// *************************************************************************** *
// *                                                                           *
// *                      Mentor Graphics Corporation                          *
// *                          All rights reserved                              *
// *                                                                           *
// *************************************************************************** *
// *                                                                           *
// * Description:         CANDB File                                           *
// * Generated at:        2019-08-28 11:46:03                                  *
// * System:              xMA19024                                             *
// * Variant:             LSPA                                                 *
// * Network:             PropulsionCAN                                        *
// *                                                                           *
// *************************************************************************** *
// *                                                                           *
// *             THIS CONFIGURATION MIGHT CONTAIN SOME ERRORS                  *
// *              IF THE INPUT MODEL WAS NOT PROPERLY FORMED!                  *
// *                    Do Not Use this File directly!                         *
// *                                                                           *
// *************************************************************************** *
VERSION "PropulsionCAN"

NS_ :

BS_:

BU_:  BECM DEM ECM EGSM ESM ETC IEM IGM ISGM MVBM MVCM MVEM OBC SRS TACM TCM VDDM VGM

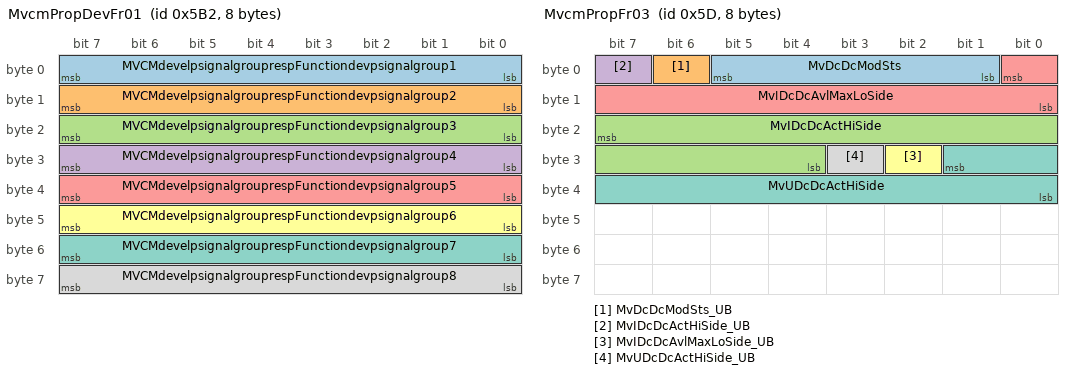
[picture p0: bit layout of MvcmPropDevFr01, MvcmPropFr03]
BO_ 1458 MvcmPropDevFr01: 8 MVCM
 SG_ MVCMdevelpsignalgrouprespFunctiondevpsignalgroup1 : 7|8@0+ (1.0,0.0) [0.0|255.0] "Unitless" ETC
 SG_ MVCMdevelpsignalgrouprespFunctiondevpsignalgroup2 : 15|8@0+ (1.0,0.0) [0.0|255.0] "Unitless" ETC
 SG_ MVCMdevelpsignalgrouprespFunctiondevpsignalgroup3 : 23|8@0+ (1.0,0.0) [0.0|255.0] "Unitless" ETC
 SG_ MVCMdevelpsignalgrouprespFunctiondevpsignalgroup4 : 31|8@0+ (1.0,0.0) [0.0|255.0] "Unitless" ETC
 SG_ MVCMdevelpsignalgrouprespFunctiondevpsignalgroup5 : 39|8@0+ (1.0,0.0) [0.0|255.0] "Unitless" ETC
 SG_ MVCMdevelpsignalgrouprespFunctiondevpsignalgroup6 : 47|8@0+ (1.0,0.0) [0.0|255.0] "Unitless" ETC
 SG_ MVCMdevelpsignalgrouprespFunctiondevpsignalgroup7 : 55|8@0+ (1.0,0.0) [0.0|255.0] "Unitless" ETC
 SG_ MVCMdevelpsignalgrouprespFunctiondevpsignalgroup8 : 63|8@0+ (1.0,0.0) [0.0|255.0] "Unitless" ETC

BO_ 93 MvcmPropFr03: 8 MVCM
 SG_ MvDcDcModSts : 5|5@0+ (1,0) [0|31] "" ECM
 SG_ MvDcDcModSts_UB : 6|1@0+ (1,0) [0|1] "" ECM
 SG_ MvIDcDcActHiSide : 23|12@0+ (0.1,-204.8) [-204.8|204.7] "A" ECM,MVBM
 SG_ MvIDcDcActHiSide_UB : 7|1@0+ (1,0) [0|1] "" ECM,MVBM
 SG_ MvIDcDcAvlMaxLoSide : 0|9@0+ (1.0,0.0) [0.0|511.0] "A" ECM,VDDM
 SG_ MvIDcDcAvlMaxLoSide_UB : 26|1@0+ (1,0) [0|1] "" ECM,VDDM
 SG_ MvUDcDcActHiSide : 25|10@0+ (0.1,0.0) [0.0|102.30000000000001] "Volt" ECM,MVBM
 SG_ MvUDcDcActHiSide_UB : 27|1@0+ (1,0) [0|1] "" ECM,MVBM

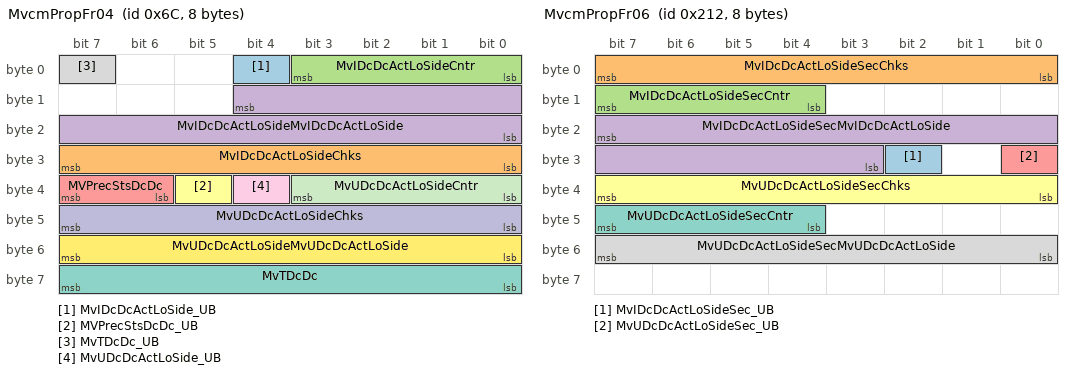
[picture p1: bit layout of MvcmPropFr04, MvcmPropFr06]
BO_ 108 MvcmPropFr04: 8 MVCM
 SG_ MvIDcDcActLoSide_UB : 4|1@0+ (1,0) [0|1] "" ECM,VDDM
 SG_ MvIDcDcActLoSideChks : 31|8@0+ (1.0,0.0) [0.0|255.0] "Unitless" ECM,VDDM
 SG_ MvIDcDcActLoSideCntr : 3|4@0+ (1.0,0.0) [0.0|15.0] "Unitless" ECM,VDDM
 SG_ MvIDcDcActLoSideMvIDcDcActLoSide : 12|13@0+ (0.1,-409.6) [-409.6|409.5] "A" ECM,VDDM
 SG_ MVPrecStsDcDc : 39|2@0+ (1,0) [0|3] "" ECM
 SG_ MVPrecStsDcDc_UB : 37|1@0+ (1,0) [0|1] "" ECM
 SG_ MvTDcDc : 63|8@0+ (1.0,-50.0) [-50.0|200.0] "degC" ECM,VDDM
 SG_ MvTDcDc_UB : 7|1@0+ (1,0) [0|1] "" ECM,VDDM
 SG_ MvUDcDcActLoSide_UB : 36|1@0+ (1,0) [0|1] "" ECM,VDDM
 SG_ MvUDcDcActLoSideChks : 47|8@0+ (1.0,0.0) [0.0|255.0] "Unitless" ECM,VDDM
 SG_ MvUDcDcActLoSideCntr : 35|4@0+ (1.0,0.0) [0.0|15.0] "Unitless" ECM,VDDM
 SG_ MvUDcDcActLoSideMvUDcDcActLoSide : 55|8@0+ (0.1,0.0) [0.0|25.400000000000002] "Volt" ECM,VDDM

BO_ 395 MvcmPropFr05: 8 MVCM
 SG_ MvFltDcDc_UB : 30|1@0+ (1,0) [0|1] "" ECM
 SG_ MvFltDcDcBoostModeFlt : 32|1@0+ (1,0) [0|1] "" ECM
 SG_ MvFltDcDcBuckModeFlt : 33|1@0+ (1,0) [0|1] "" ECM
 SG_ MvFltDcDcCANLoss : 39|1@0+ (1,0) [0|1] "" ECM
 SG_ MvFltDcDcHwFlt : 42|1@0+ (1,0) [0|1] "" ECM
 SG_ MvFltDcDcLVSideOpenLoad : 35|1@0+ (1,0) [0|1] "" ECM
 SG_ MvFltDcDcLVSideOverCurrent : 41|1@0+ (1,0) [0|1] "" ECM
 SG_ MvFltDcDcLVSideOverVoltage : 38|1@0+ (1,0) [0|1] "" ECM
 SG_ MvFltDcDcLVSideUnderVoltage : 47|1@0+ (1,0) [0|1] "" ECM
 SG_ MvFltDcDcMVSideOverCurrent : 44|1@0+ (1,0) [0|1] "" ECM
 SG_ MvFltDcDcMVSideOverVoltage : 34|1@0+ (1,0) [0|1] "" ECM
 SG_ MvFltDcDcMVSideUnderVoltage : 37|1@0+ (1,0) [0|1] "" ECM
 SG_ MvFltDcDcPCBOverTemp : 36|1@0+ (1,0) [0|1] "" ECM
 SG_ MvFltDcDcPreChargeFlt : 40|1@0+ (1,0) [0|1] "" ECM
 SG_ MvFltDcDcPwrGndLoss : 46|1@0+ (1,0) [0|1] "" ECM
 SG_ MvFltDcDcSec_UB : 60|1@0+ (1,0) [0|1] "" ECM
 SG_ MvFltDcDcSecBuckModeFault : 55|1@0+ (1,0) [0|1] "" ECM
 SG_ MvFltDcDcSecHwFlt : 54|1@0+ (1,0) [0|1] "" ECM
 SG_ MvFltDcDcSecLVSideOpenLoad : 53|1@0+ (1,0) [0|1] "" ECM
 SG_ MvFltDcDcSecLVSideOverCurrent : 52|1@0+ (1,0) [0|1] "" ECM
 SG_ MvFltDcDcSecLVSideOverVoltage : 51|1@0+ (1,0) [0|1] "" ECM
 SG_ MvFltDcDcSecLVSideUnderVoltage : 50|1@0+ (1,0) [0|1] "" ECM
 SG_ MvFltDcDcSecMVSideOverCurrent : 49|1@0+ (1,0) [0|1] "" ECM
 SG_ MvFltDcDcSecPCBOverTemperature : 48|1@0+ (1,0) [0|1] "" ECM
 SG_ MvFltDcDcSecPowerGNDLoss : 63|1@0+ (1,0) [0|1] "" ECM
 SG_ MvFltDcDcSecSensorFault : 62|1@0+ (1,0) [0|1] "" ECM
 SG_ MvFltDcDcSecSupplyVoltageCmpFlt : 61|1@0+ (1,0) [0|1] "" ECM
 SG_ MvFltDcDcSensorFlt : 45|1@0+ (1,0) [0|1] "" ECM
 SG_ MvFltDcDcSupplyVoltageCmpFlt : 43|1@0+ (1,0) [0|1] "" ECM
 SG_ MvLimnIndcnDcDc_UB : 31|1@0+ (1,0) [0|1] "" ECM,VDDM
 SG_ MvLimnIndcnDcDcChks : 7|8@0+ (1.0,0.0) [0.0|255.0] "Unitless" ECM,VDDM
 SG_ MvLimnIndcnDcDcCntr : 15|4@0+ (1.0,0.0) [0.0|15.0] "Unitless" ECM,VDDM
 SG_ MvLimnIndcnDcDcMvLimnIndcnDcDc : 23|8@0+ (1.0,0.0) [0.0|255.0] "Unitless" ECM,VDDM

BO_ 530 MvcmPropFr06: 8 MVCM
 SG_ MvIDcDcActLoSideSec_UB : 26|1@0+ (1,0) [0|1] "" ECM
 SG_ MvIDcDcActLoSideSecChks : 7|8@0+ (1.0,0.0) [0.0|255.0] "Unitless" ECM
 SG_ MvIDcDcActLoSideSecCntr : 15|4@0+ (1.0,0.0) [0.0|15.0] "Unitless" ECM
 SG_ MvIDcDcActLoSideSecMvIDcDcActLoSide : 23|13@0+ (0.1,-409.6) [-409.6|409.5] "A" ECM
 SG_ MvUDcDcActLoSideSec_UB : 24|1@0+ (1,0) [0|1] "" ECM
 SG_ MvUDcDcActLoSideSecChks : 39|8@0+ (1.0,0.0) [0.0|255.0] "Unitless" ECM
 SG_ MvUDcDcActLoSideSecCntr : 47|4@0+ (1.0,0.0) [0.0|15.0] "Unitless" ECM
 SG_ MvUDcDcActLoSideSecMvUDcDcActLoSide : 55|8@0+ (0.1,0.0) [0.0|25.400000000000002] "Volt" ECM

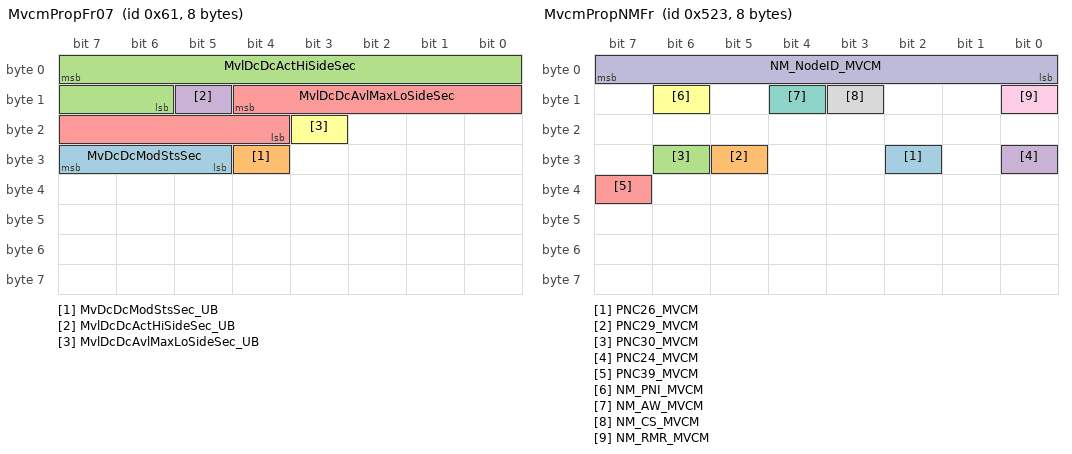
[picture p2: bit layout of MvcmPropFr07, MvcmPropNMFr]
BO_ 97 MvcmPropFr07: 8 MVCM
 SG_ MvDcDcModStsSec : 31|3@0+ (1,0) [0|7] "" ECM
 SG_ MvDcDcModStsSec_UB : 28|1@0+ (1,0) [0|1] "" ECM
 SG_ MvlDcDcActHiSideSec : 7|10@0+ (0.1,0.0) [0.0|102.30000000000001] "Volt" ECM
 SG_ MvlDcDcActHiSideSec_UB : 13|1@0+ (1,0) [0|1] "" ECM
 SG_ MvlDcDcAvlMaxLoSideSec : 12|9@0+ (1.0,0.0) [0.0|511.0] "A" ECM
 SG_ MvlDcDcAvlMaxLoSideSec_UB : 19|1@0+ (1,0) [0|1] "" ECM

BO_ 1154 MvcmPropFr08: 8 MVCM
 SG_ MvTDcDcSec : 7|8@0+ (1.0,-50.0) [-50.0|200.0] "degC" ECM
 SG_ MvTDcDcSec_UB : 15|1@0+ (1,0) [0|1] "" ECM

BO_ 1315 MvcmPropNMFr: 8 MVCM
 SG_ PNC26_MVCM : 26|1@0+ (1,0) [0|0] "" MVBM
 SG_ PNC29_MVCM : 29|1@0+ (1,0) [0|0] "" MVBM
 SG_ PNC30_MVCM : 30|1@0+ (1,0) [0|0] "" MVBM
 SG_ PNC24_MVCM : 24|1@0+ (1,0) [0|0] "" MVBM
 SG_ PNC39_MVCM : 39|1@0+ (1,0) [0|0] "" MVBM
 SG_ NM_PNI_MVCM : 14|1@0+ (1,0) [0|0] "" MVBM
 SG_ NM_AW_MVCM : 12|1@0+ (1,0) [0|0] "" MVBM
 SG_ NM_CS_MVCM : 11|1@0+ (1,0) [0|0] "" MVBM
 SG_ NM_RMR_MVCM : 8|1@0+ (1,0) [0|0] "" MVBM
 SG_ NM_NodeID_MVCM : 7|8@0+ (1,0) [0|0] "" MVBM

BO_ 1597 MvcmToVddmPropDiagResFrame: 8 MVCM
 SG_ MvcmToVddmPropDiagResNpdu : 7|64@0+ (1,0) [0|0] "" VDDM

BO_ 1617 MvemToVddmPropDiagResFrame1: 8 MVEM
 SG_ MvemToVddmPropDiagResNpdu : 7|64@0+ (1,0) [0|0] "" VDDM

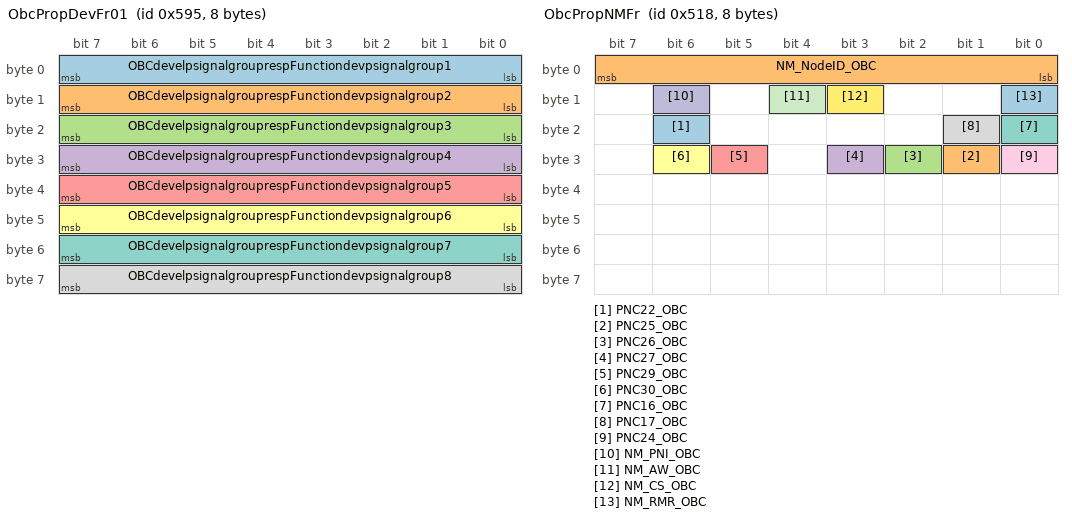
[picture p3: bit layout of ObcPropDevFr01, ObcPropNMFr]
BO_ 1429 ObcPropDevFr01: 8 OBC
 SG_ OBCdevelpsignalgrouprespFunctiondevpsignalgroup1 : 7|8@0+ (1.0,0.0) [0.0|255.0] "Unitless" ETC
 SG_ OBCdevelpsignalgrouprespFunctiondevpsignalgroup2 : 15|8@0+ (1.0,0.0) [0.0|255.0] "Unitless" ETC
 SG_ OBCdevelpsignalgrouprespFunctiondevpsignalgroup3 : 23|8@0+ (1.0,0.0) [0.0|255.0] "Unitless" ETC
 SG_ OBCdevelpsignalgrouprespFunctiondevpsignalgroup4 : 31|8@0+ (1.0,0.0) [0.0|255.0] "Unitless" ETC
 SG_ OBCdevelpsignalgrouprespFunctiondevpsignalgroup5 : 39|8@0+ (1.0,0.0) [0.0|255.0] "Unitless" ETC
 SG_ OBCdevelpsignalgrouprespFunctiondevpsignalgroup6 : 47|8@0+ (1.0,0.0) [0.0|255.0] "Unitless" ETC
 SG_ OBCdevelpsignalgrouprespFunctiondevpsignalgroup7 : 55|8@0+ (1.0,0.0) [0.0|255.0] "Unitless" ETC
 SG_ OBCdevelpsignalgrouprespFunctiondevpsignalgroup8 : 63|8@0+ (1.0,0.0) [0.0|255.0] "Unitless" ETC

BO_ 1304 ObcPropNMFr: 8 OBC
 SG_ PNC22_OBC : 22|1@0+ (1,0) [0|0] "" MVCM
 SG_ PNC25_OBC : 25|1@0+ (1,0) [0|0] "" MVCM
 SG_ PNC26_OBC : 26|1@0+ (1,0) [0|0] "" MVCM
 SG_ PNC27_OBC : 27|1@0+ (1,0) [0|0] "" MVCM
 SG_ PNC29_OBC : 29|1@0+ (1,0) [0|0] "" MVCM
 SG_ PNC30_OBC : 30|1@0+ (1,0) [0|0] "" MVCM
 SG_ PNC16_OBC : 16|1@0+ (1,0) [0|0] "" MVCM
 SG_ PNC17_OBC : 17|1@0+ (1,0) [0|0] "" MVCM
 SG_ PNC24_OBC : 24|1@0+ (1,0) [0|0] "" MVCM
 SG_ NM_PNI_OBC : 14|1@0+ (1,0) [0|0] "" MVCM
 SG_ NM_AW_OBC : 12|1@0+ (1,0) [0|0] "" MVCM
 SG_ NM_CS_OBC : 11|1@0+ (1,0) [0|0] "" MVCM
 SG_ NM_RMR_OBC : 8|1@0+ (1,0) [0|0] "" MVCM
 SG_ NM_NodeID_OBC : 7|8@0+ (1,0) [0|0] "" MVCM

BO_ 1362 ObcPropVFCVectorFr: 8 OBC
 SG_ VFCVectorOBCBlockID : 1|2@0+ (1.0,0.0) [0.0|3.0] "Unitless" ETC
 SG_ VFCVectorOBCVFCid0 : 2|1@0+ (1,0) [0|1] "" ETC
 SG_ VFCVectorOBCVFCid1 : 3|1@0+ (1,0) [0|1] "" ETC
 SG_ VFCVectorOBCVFCid10 : 12|1@0+ (1,0) [0|1] "" ETC
 SG_ VFCVectorOBCVFCid11 : 13|1@0+ (1,0) [0|1] "" ETC
 SG_ VFCVectorOBCVFCid12 : 14|1@0+ (1,0) [0|1] "" ETC
 SG_ VFCVectorOBCVFCid13 : 15|1@0+ (1,0) [0|1] "" ETC
 SG_ VFCVectorOBCVFCid14 : 16|1@0+ (1,0) [0|1] "" ETC
 SG_ VFCVectorOBCVFCid15 : 17|1@0+ (1,0) [0|1] "" ETC
 SG_ VFCVectorOBCVFCid16 : 18|1@0+ (1,0) [0|1] "" ETC
 SG_ VFCVectorOBCVFCid17 : 19|1@0+ (1,0) [0|1] "" ETC
 SG_ VFCVectorOBCVFCid18 : 20|1@0+ (1,0) [0|1] "" ETC
 SG_ VFCVectorOBCVFCid19 : 21|1@0+ (1,0) [0|1] "" ETC
 SG_ VFCVectorOBCVFCid2 : 4|1@0+ (1,0) [0|1] "" ETC
 SG_ VFCVectorOBCVFCid20 : 22|1@0+ (1,0) [0|1] "" ETC
 SG_ VFCVectorOBCVFCid21 : 23|1@0+ (1,0) [0|1] "" ETC
 SG_ VFCVectorOBCVFCid22 : 24|1@0+ (1,0) [0|1] "" ETC
 SG_ VFCVectorOBCVFCid23 : 25|1@0+ (1,0) [0|1] "" ETC
 SG_ VFCVectorOBCVFCid24 : 26|1@0+ (1,0) [0|1] "" ETC
 SG_ VFCVectorOBCVFCid25 : 27|1@0+ (1,0) [0|1] "" ETC
 SG_ VFCVectorOBCVFCid26 : 28|1@0+ (1,0) [0|1] "" ETC
 SG_ VFCVectorOBCVFCid27 : 29|1@0+ (1,0) [0|1] "" ETC
 SG_ VFCVectorOBCVFCid28 : 30|1@0+ (1,0) [0|1] "" ETC
 SG_ VFCVectorOBCVFCid29 : 31|1@0+ (1,0) [0|1] "" ETC
 SG_ VFCVectorOBCVFCid3 : 5|1@0+ (1,0) [0|1] "" ETC
 SG_ VFCVectorOBCVFCid30 : 32|1@0+ (1,0) [0|1] "" ETC
 SG_ VFCVectorOBCVFCid31 : 33|1@0+ (1,0) [0|1] "" ETC
 SG_ VFCVectorOBCVFCid32 : 34|1@0+ (1,0) [0|1] "" ETC
 SG_ VFCVectorOBCVFCid33 : 35|1@0+ (1,0) [0|1] "" ETC
 SG_ VFCVectorOBCVFCid34 : 36|1@0+ (1,0) [0|1] "" ETC
 SG_ VFCVectorOBCVFCid35 : 37|1@0+ (1,0) [0|1] "" ETC
 SG_ VFCVectorOBCVFCid36 : 38|1@0+ (1,0) [0|1] "" ETC
 SG_ VFCVectorOBCVFCid37 : 39|1@0+ (1,0) [0|1] "" ETC
 SG_ VFCVectorOBCVFCid38 : 40|1@0+ (1,0) [0|1] "" ETC
 SG_ VFCVectorOBCVFCid39 : 41|1@0+ (1,0) [0|1] "" ETC
 SG_ VFCVectorOBCVFCid4 : 6|1@0+ (1,0) [0|1] "" ETC
 SG_ VFCVectorOBCVFCid40 : 42|1@0+ (1,0) [0|1] "" ETC
 SG_ VFCVectorOBCVFCid41 : 43|1@0+ (1,0) [0|1] "" ETC
 SG_ VFCVectorOBCVFCid42 : 44|1@0+ (1,0) [0|1] "" ETC
 SG_ VFCVectorOBCVFCid43 : 45|1@0+ (1,0) [0|1] "" ETC
 SG_ VFCVectorOBCVFCid44 : 46|1@0+ (1,0) [0|1] "" ETC
 SG_ VFCVectorOBCVFCid45 : 47|1@0+ (1,0) [0|1] "" ETC
 SG_ VFCVectorOBCVFCid46 : 48|1@0+ (1,0) [0|1] "" ETC
 SG_ VFCVectorOBCVFCid47 : 49|1@0+ (1,0) [0|1] "" ETC
 SG_ VFCVectorOBCVFCid48 : 50|1@0+ (1,0) [0|1] "" ETC
 SG_ VFCVectorOBCVFCid49 : 51|1@0+ (1,0) [0|1] "" ETC
 SG_ VFCVectorOBCVFCid5 : 7|1@0+ (1,0) [0|1] "" ETC
 SG_ VFCVectorOBCVFCid50 : 52|1@0+ (1,0) [0|1] "" ETC
 SG_ VFCVectorOBCVFCid51 : 53|1@0+ (1,0) [0|1] "" ETC
 SG_ VFCVectorOBCVFCid52 : 54|1@0+ (1,0) [0|1] "" ETC
 SG_ VFCVectorOBCVFCid53 : 55|1@0+ (1,0) [0|1] "" ETC
 SG_ VFCVectorOBCVFCid54 : 56|1@0+ (1,0) [0|1] "" ETC
 SG_ VFCVectorOBCVFCid55 : 57|1@0+ (1,0) [0|1] "" ETC
 SG_ VFCVectorOBCVFCid56 : 58|1@0+ (1,0) [0|1] "" ETC
 SG_ VFCVectorOBCVFCid57 : 59|1@0+ (1,0) [0|1] "" ETC
 SG_ VFCVectorOBCVFCid58 : 60|1@0+ (1,0) [0|1] "" ETC
 SG_ VFCVectorOBCVFCid59 : 61|1@0+ (1,0) [0|1] "" ETC
 SG_ VFCVectorOBCVFCid6 : 8|1@0+ (1,0) [0|1] "" ETC
 SG_ VFCVectorOBCVFCid60 : 62|1@0+ (1,0) [0|1] "" ETC
 SG_ VFCVectorOBCVFCid61 : 63|1@0+ (1,0) [0|1] "" ETC
 SG_ VFCVectorOBCVFCid7 : 9|1@0+ (1,0) [0|1] "" ETC
 SG_ VFCVectorOBCVFCid8 : 10|1@0+ (1,0) [0|1] "" ETC
 SG_ VFCVectorOBCVFCid9 : 11|1@0+ (1,0) [0|1] "" ETC

BO_ 1588 ObcToVddmPropDiagResFrame: 8 OBC
 SG_ ObcToVddmPropDiagResNpdu : 7|64@0+ (1,0) [0|0] "" VDDM

BO_ 2029 ObcToVgmJ1979OBDPropCanResFrame11: 8 OBC
 SG_ ObcToVgmJ1979OBDPropCanResNpdu11 : 7|64@0+ (1,0) [0|0] "" VGM

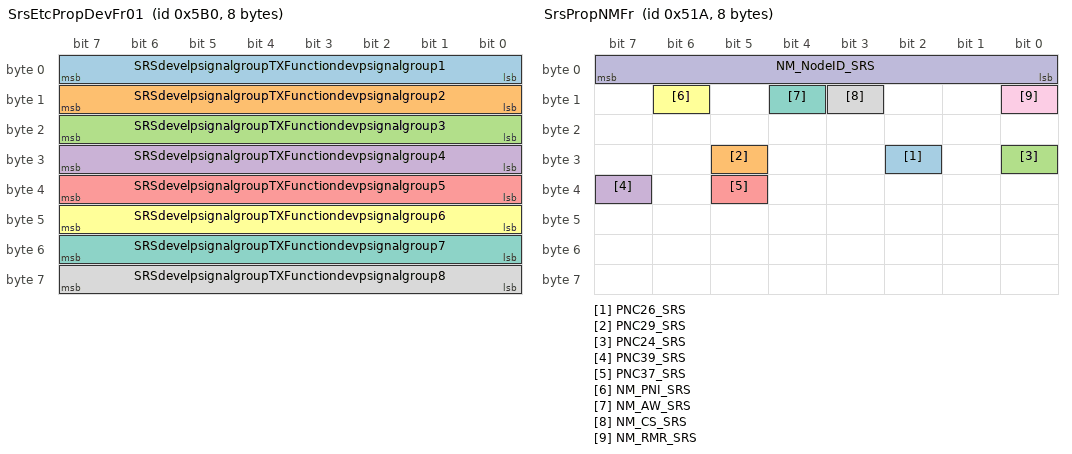
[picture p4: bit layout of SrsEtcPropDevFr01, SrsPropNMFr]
BO_ 1456 SrsEtcPropDevFr01: 8 SRS
 SG_ SRSdevelpsignalgroupTXFunctiondevpsignalgroup1 : 7|8@0+ (1.0,0.0) [0.0|255.0] "Unitless" ETC
 SG_ SRSdevelpsignalgroupTXFunctiondevpsignalgroup2 : 15|8@0+ (1.0,0.0) [0.0|255.0] "Unitless" ETC
 SG_ SRSdevelpsignalgroupTXFunctiondevpsignalgroup3 : 23|8@0+ (1.0,0.0) [0.0|255.0] "Unitless" ETC
 SG_ SRSdevelpsignalgroupTXFunctiondevpsignalgroup4 : 31|8@0+ (1.0,0.0) [0.0|255.0] "Unitless" ETC
 SG_ SRSdevelpsignalgroupTXFunctiondevpsignalgroup5 : 39|8@0+ (1.0,0.0) [0.0|255.0] "Unitless" ETC
 SG_ SRSdevelpsignalgroupTXFunctiondevpsignalgroup6 : 47|8@0+ (1.0,0.0) [0.0|255.0] "Unitless" ETC
 SG_ SRSdevelpsignalgroupTXFunctiondevpsignalgroup7 : 55|8@0+ (1.0,0.0) [0.0|255.0] "Unitless" ETC
 SG_ SRSdevelpsignalgroupTXFunctiondevpsignalgroup8 : 63|8@0+ (1.0,0.0) [0.0|255.0] "Unitless" ETC

BO_ 53 SrsPropFr02: 8 SRS
 SG_ CrashStsSafe_UB : 5|1@0+ (1,0) [0|1] "" BECM,ECM,IEM,IGM,ISGM,MVBM,MVCM,TCM
 SG_ CrashStsSafeChks : 15|8@0+ (1.0,0.0) [0.0|255.0] "Unitless" BECM,ECM,IEM,IGM,ISGM,MVBM,MVCM,TCM
 SG_ CrashStsSafeCntr : 3|4@0+ (1.0,0.0) [0.0|15.0] "Unitless" BECM,ECM,IEM,IGM,ISGM,MVBM,MVCM,TCM
 SG_ CrashStsSafeSts : 4|1@0+ (1,0) [0|1] "" BECM,ECM,IEM,IGM,ISGM,MVBM,MVCM,TCM

BO_ 1306 SrsPropNMFr: 8 SRS
 SG_ PNC26_SRS : 26|1@0+ (1,0) [0|0] "" OBC
 SG_ PNC29_SRS : 29|1@0+ (1,0) [0|0] "" OBC
 SG_ PNC24_SRS : 24|1@0+ (1,0) [0|0] "" OBC
 SG_ PNC39_SRS : 39|1@0+ (1,0) [0|0] "" OBC
 SG_ PNC37_SRS : 37|1@0+ (1,0) [0|0] "" OBC
 SG_ NM_PNI_SRS : 14|1@0+ (1,0) [0|0] "" OBC
 SG_ NM_AW_SRS : 12|1@0+ (1,0) [0|0] "" OBC
 SG_ NM_CS_SRS : 11|1@0+ (1,0) [0|0] "" OBC
 SG_ NM_RMR_SRS : 8|1@0+ (1,0) [0|0] "" OBC
 SG_ NM_NodeID_SRS : 7|8@0+ (1,0) [0|0] "" OBC

BO_ 2041 SrsToVgmISO26021PropDiagResFrame11: 8 SRS
 SG_ SrsToVgmISO26021PropCanResNpdu11 : 7|64@0+ (1,0) [0|0] "" VGM

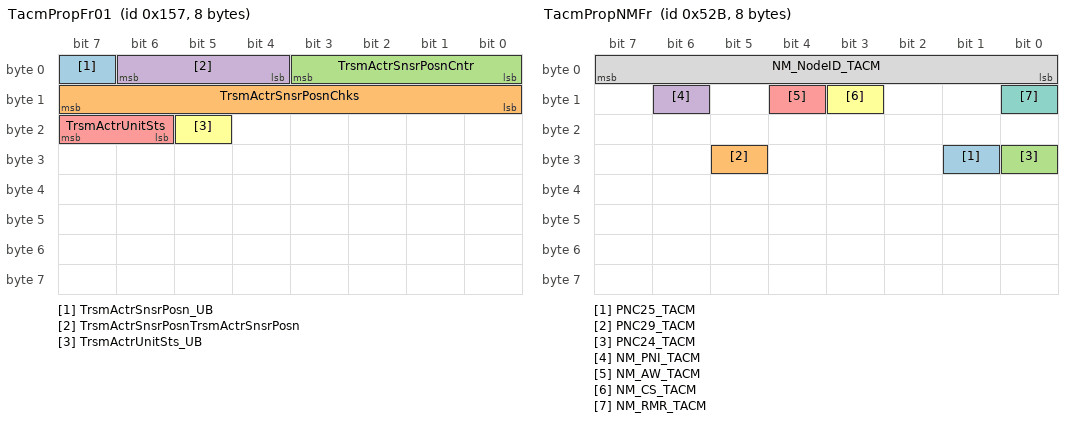
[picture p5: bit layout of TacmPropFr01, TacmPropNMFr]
BO_ 343 TacmPropFr01: 8 TACM
 SG_ TrsmActrSnsrPosn_UB : 7|1@0+ (1,0) [0|1] "" ECM,VDDM
 SG_ TrsmActrSnsrPosnChks : 15|8@0+ (1.0,0.0) [0.0|255.0] "Unitless" ECM,VDDM
 SG_ TrsmActrSnsrPosnCntr : 3|4@0+ (1.0,0.0) [0.0|15.0] "Unitless" ECM,VDDM
 SG_ TrsmActrSnsrPosnTrsmActrSnsrPosn : 6|3@0+ (1,0) [0|7] "" ECM,VDDM
 SG_ TrsmActrUnitSts : 23|2@0+ (1,0) [0|3] "" ECM
 SG_ TrsmActrUnitSts_UB : 21|1@0+ (1,0) [0|1] "" ECM

BO_ 1323 TacmPropNMFr: 8 TACM
 SG_ PNC25_TACM : 25|1@0+ (1,0) [0|0] "" SRS
 SG_ PNC29_TACM : 29|1@0+ (1,0) [0|0] "" SRS
 SG_ PNC24_TACM : 24|1@0+ (1,0) [0|0] "" SRS
 SG_ NM_PNI_TACM : 14|1@0+ (1,0) [0|0] "" SRS
 SG_ NM_AW_TACM : 12|1@0+ (1,0) [0|0] "" SRS
 SG_ NM_CS_TACM : 11|1@0+ (1,0) [0|0] "" SRS
 SG_ NM_RMR_TACM : 8|1@0+ (1,0) [0|0] "" SRS
 SG_ NM_NodeID_TACM : 7|8@0+ (1,0) [0|0] "" SRS

BO_ 1425 TACMtoETCXcpFr01: 8 TACM

BO_ 1426 TACMtoETCXcpFr02: 8 TACM

BO_ 1427 TACMtoETCXcpFr03: 8 TACM

BO_ 1596 TacmToVddmPropDiagResFrame: 8 TACM
 SG_ TacmToVddmPropDiagResNpdu : 7|64@0+ (1,0) [0|0] "" VDDM

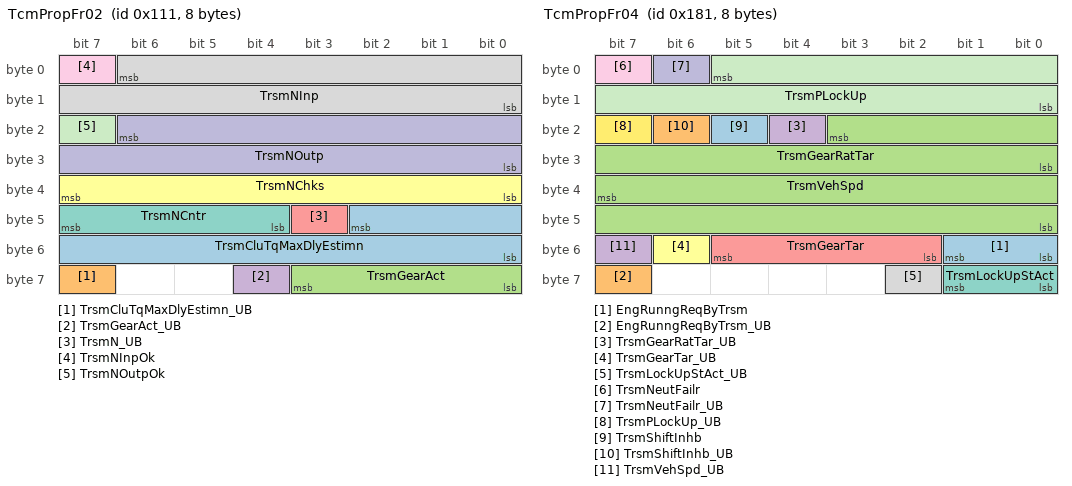
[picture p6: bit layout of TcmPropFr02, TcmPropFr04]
BO_ 273 TcmPropFr02: 8 TCM
 SG_ TrsmCluTqMaxDlyEstimn : 42|11@0+ (1.0,-1024.0) [-1024.0|1023.0] "NewtonMeter" ECM
 SG_ TrsmCluTqMaxDlyEstimn_UB : 63|1@0+ (1,0) [0|1] "" ECM
 SG_ TrsmGearAct : 59|4@0+ (1,0) [0|15] "" ECM
 SG_ TrsmGearAct_UB : 60|1@0+ (1,0) [0|1] "" ECM
 SG_ TrsmN_UB : 43|1@0+ (1,0) [0|1] "" ECM,VDDM
 SG_ TrsmNChks : 39|8@0+ (1.0,0.0) [0.0|255.0] "Unitless" ECM,VDDM
 SG_ TrsmNCntr : 47|4@0+ (1.0,0.0) [0.0|15.0] "Unitless" ECM,VDDM
 SG_ TrsmNInp : 6|15@0+ (0.5,0.0) [0.0|16383.5] "rpm" ECM,VDDM
 SG_ TrsmNInpOk : 7|1@0+ (1,0) [0|1] "" ECM,VDDM
 SG_ TrsmNOutp : 22|15@0+ (0.5,0.0) [0.0|16383.5] "rpm" ECM,VDDM
 SG_ TrsmNOutpOk : 23|1@0+ (1,0) [0|1] "" ECM,VDDM

BO_ 385 TcmPropFr04: 8 TCM
 SG_ EngRunngReqByTrsm : 49|2@0+ (1,0) [0|3] "" ECM,VDDM
 SG_ EngRunngReqByTrsm_UB : 63|1@0+ (1,0) [0|1] "" ECM,VDDM
 SG_ TrsmGearRatTar : 19|12@0+ (0.01,0.0) [0.0|40.95] "Unitless" ECM
 SG_ TrsmGearRatTar_UB : 20|1@0+ (1,0) [0|1] "" ECM
 SG_ TrsmGearTar : 53|4@0+ (1,0) [0|15] "" ECM
 SG_ TrsmGearTar_UB : 54|1@0+ (1,0) [0|1] "" ECM
 SG_ TrsmLockUpStAct : 57|2@0+ (1,0) [0|3] "" ECM
 SG_ TrsmLockUpStAct_UB : 58|1@0+ (1,0) [0|1] "" ECM
 SG_ TrsmNeutFailr : 7|1@0+ (1,0) [0|1] "" ECM
 SG_ TrsmNeutFailr_UB : 6|1@0+ (1,0) [0|1] "" ECM
 SG_ TrsmPLockUp : 5|14@0+ (1.0,0.0) [0.0|16383.0] "Unitless" ECM
 SG_ TrsmPLockUp_UB : 23|1@0+ (1,0) [0|1] "" ECM
 SG_ TrsmShiftInhb : 21|1@0+ (1,0) [0|1] "" ECM
 SG_ TrsmShiftInhb_UB : 22|1@0+ (1,0) [0|1] "" ECM
 SG_ TrsmVehSpd : 39|16@0+ (0.01,0.0) [0.0|655.35] "Km/h" BECM,ECM
 SG_ TrsmVehSpd_UB : 55|1@0+ (1,0) [0|1] "" BECM,ECM

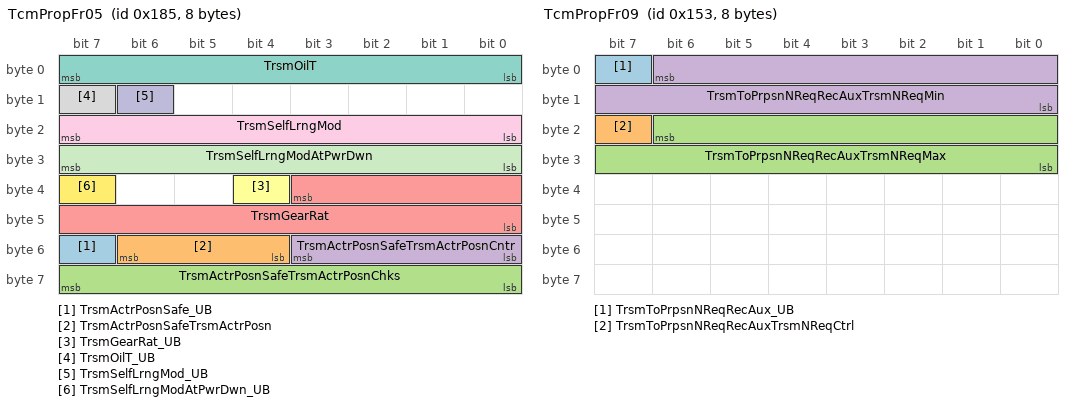
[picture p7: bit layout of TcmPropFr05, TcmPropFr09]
BO_ 389 TcmPropFr05: 8 TCM
 SG_ TrsmActrPosnSafe_UB : 55|1@0+ (1,0) [0|1] "" ECM,EGSM,TACM,VDDM
 SG_ TrsmActrPosnSafeTrsmActrPosn : 54|3@0+ (1,0) [0|7] "" ECM,EGSM,TACM,VDDM
 SG_ TrsmActrPosnSafeTrsmActrPosnChks : 63|8@0+ (1.0,0.0) [0.0|255.0] "Unitless" ECM,EGSM,TACM,VDDM
 SG_ TrsmActrPosnSafeTrsmActrPosnCntr : 51|4@0+ (1.0,0.0) [0.0|15.0] "Unitless" ECM,EGSM,TACM,VDDM
 SG_ TrsmGearRat : 35|12@0+ (0.01,0.0) [0.0|40.95] "Unitless" ECM
 SG_ TrsmGearRat_UB : 36|1@0+ (1,0) [0|1] "" ECM
 SG_ TrsmOilT : 7|8@0+ (1.0,-60.0) [-60.0|195.0] "degC" ECM,VDDM
 SG_ TrsmOilT_UB : 15|1@0+ (1,0) [0|1] "" ECM,VDDM
 SG_ TrsmSelfLrngMod : 23|8@0+ (1.0,0.0) [0.0|255.0] "Unitless" ECM
 SG_ TrsmSelfLrngMod_UB : 14|1@0+ (1,0) [0|1] "" ECM
 SG_ TrsmSelfLrngModAtPwrDwn : 31|8@0+ (1.0,0.0) [0.0|255.0] "Unitless" ECM
 SG_ TrsmSelfLrngModAtPwrDwn_UB : 39|1@0+ (1,0) [0|1] "" ECM

BO_ 339 TcmPropFr09: 8 TCM
 SG_ TrsmToPrpsnNReqRecAux_UB : 7|1@0+ (1,0) [0|1] "" ECM
 SG_ TrsmToPrpsnNReqRecAuxTrsmNReqCtrl : 23|1@0+ (1,0) [0|1] "" ECM
 SG_ TrsmToPrpsnNReqRecAuxTrsmNReqMax : 22|15@0+ (0.5,0.0) [0.0|16383.5] "rpm" ECM
 SG_ TrsmToPrpsnNReqRecAuxTrsmNReqMin : 6|15@0+ (0.5,0.0) [0.0|16383.5] "rpm" ECM

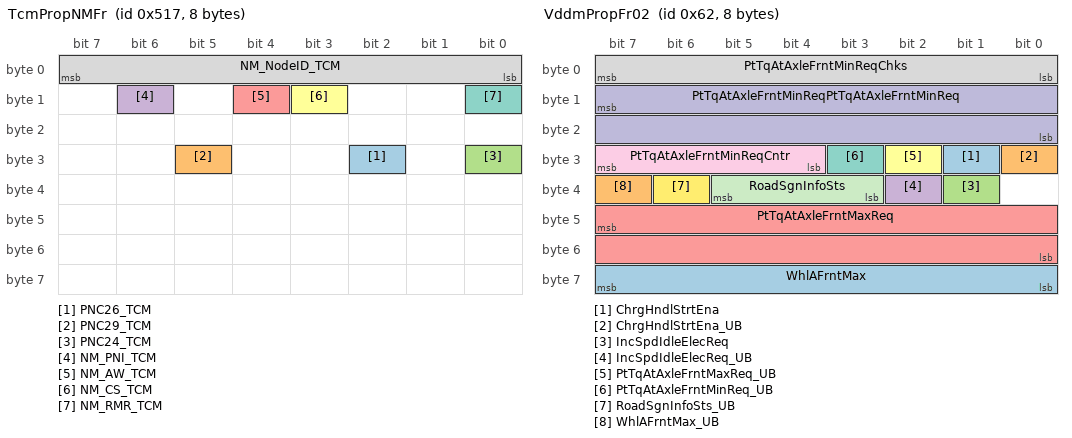
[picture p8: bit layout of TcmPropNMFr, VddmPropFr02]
BO_ 1303 TcmPropNMFr: 8 TCM
 SG_ PNC26_TCM : 26|1@0+ (1,0) [0|0] "" TACM
 SG_ PNC29_TCM : 29|1@0+ (1,0) [0|0] "" TACM
 SG_ PNC24_TCM : 24|1@0+ (1,0) [0|0] "" TACM
 SG_ NM_PNI_TCM : 14|1@0+ (1,0) [0|0] "" TACM
 SG_ NM_AW_TCM : 12|1@0+ (1,0) [0|0] "" TACM
 SG_ NM_CS_TCM : 11|1@0+ (1,0) [0|0] "" TACM
 SG_ NM_RMR_TCM : 8|1@0+ (1,0) [0|0] "" TACM
 SG_ NM_NodeID_TCM : 7|8@0+ (1,0) [0|0] "" TACM

BO_ 1586 TcmToVddmPropDiagResFrame: 8 TCM
 SG_ TcmToVddmPropDiagResNpdu : 7|64@0+ (1,0) [0|0] "" VDDM

BO_ 2025 TcmToVgmJ1979OBDPropCanResFrame11: 8 TCM
 SG_ TcmToVgmJ1979OBDPropCanResNpdu11 : 7|64@0+ (1,0) [0|0] "" VGM

BO_ 1772 UudtBecmFr01: 8 BECM
 SG_ UudtBecmNPdu1 : 7|64@0+ (1,0) [0|0] "" ETC

BO_ 1773 UudtBecmFr02: 8 BECM
 SG_ UudtBecmNPdu2 : 7|64@0+ (1,0) [0|0] "" ETC

BO_ 1774 UudtBecmFr03: 8 BECM
 SG_ UudtBecmNPdu3 : 7|64@0+ (1,0) [0|0] "" ETC

BO_ 1775 UudtBecmFr04: 8 BECM
 SG_ UudtBecmNPdu4 : 7|64@0+ (1,0) [0|0] "" ETC

BO_ 1764 UudtBecmFr05: 8 BECM
 SG_ UudtBecmNPdu5 : 7|64@0+ (1,0) [0|0] "" ETC

BO_ 1791 UudtDemFr01: 8 DEM
 SG_ UudtDemNPdu1 : 7|64@0+ (1,0) [0|0] "" ETC

BO_ 1790 UudtDemFr02: 8 DEM
 SG_ UudtDemNPdu2 : 7|64@0+ (1,0) [0|0] "" ETC

BO_ 1789 UudtEcmFr01: 8 ECM
 SG_ UudtEcmNPdu1 : 7|64@0+ (1,0) [0|0] "" ETC

BO_ 1788 UudtEcmFr02: 8 ECM
 SG_ UudtEcmNPdu2 : 7|64@0+ (1,0) [0|0] "" ETC

BO_ 1787 UudtEcmFr03: 8 ECM
 SG_ UudtEcmNPdu3 : 7|64@0+ (1,0) [0|0] "" ETC

BO_ 1786 UudtEcmFr04: 8 ECM
 SG_ UudtEcmNPdu4 : 7|64@0+ (1,0) [0|0] "" ETC

BO_ 1770 UudtEgsmFr01: 8 EGSM
 SG_ UudtEgsmNPdu1 : 7|64@0+ (1,0) [0|0] "" ETC

BO_ 1771 UudtEgsmFr02: 8 EGSM
 SG_ UudtEgsmNPdu2 : 7|64@0+ (1,0) [0|0] "" ETC

BO_ 1776 UudtIemFr01: 8 IEM
 SG_ UudtIemNPdu1 : 7|64@0+ (1,0) [0|0] "" ETC

BO_ 1777 UudtIemFr02: 8 IEM
 SG_ UudtIemNPdu2 : 7|64@0+ (1,0) [0|0] "" ETC

BO_ 1778 UudtIemFr03: 8 IEM
 SG_ UudtIemNPdu3 : 7|64@0+ (1,0) [0|0] "" ETC

BO_ 1779 UudtIgmFr01: 8 IGM
 SG_ UudtIgmNPdu1 : 7|64@0+ (1,0) [0|0] "" ETC

BO_ 1780 UudtIgmFr02: 8 IGM
 SG_ UudtIgmNPdu2 : 7|64@0+ (1,0) [0|0] "" ETC

BO_ 1781 UudtIgmFr03: 8 IGM
 SG_ UudtIgmNPdu3 : 7|64@0+ (1,0) [0|0] "" ETC

BO_ 1785 UudtTcmFr01: 8 TCM
 SG_ UudtTcmNPdu1 : 7|64@0+ (1,0) [0|0] "" ETC

BO_ 1784 UudtTcmFr02: 8 TCM
 SG_ UudtTcmNPdu2 : 7|64@0+ (1,0) [0|0] "" ETC

BO_ 1783 UudtTcmFr03: 8 TCM
 SG_ UudtTcmNPdu3 : 7|64@0+ (1,0) [0|0] "" ETC

BO_ 1782 UudtTcmFr04: 8 TCM
 SG_ UudtTcmNPdu4 : 7|64@0+ (1,0) [0|0] "" ETC

BO_ 98 VddmPropFr02: 8 VDDM
 SG_ ChrgHndlStrtEna : 25|1@0+ (1,0) [0|1] "" ECM
 SG_ ChrgHndlStrtEna_UB : 24|1@0+ (1,0) [0|1] "" ECM
 SG_ IncSpdIdleElecReq : 33|1@0+ (1,0) [0|1] "" ECM
 SG_ IncSpdIdleElecReq_UB : 34|1@0+ (1,0) [0|1] "" ECM
 SG_ PtTqAtAxleFrntMaxReq : 47|16@0- (1.0,0.0) [-20000.0|20000.0] "NewtonMeter" ECM,IGM
 SG_ PtTqAtAxleFrntMaxReq_UB : 26|1@0+ (1,0) [0|1] "" ECM,IGM
 SG_ PtTqAtAxleFrntMinReq_UB : 27|1@0+ (1,0) [0|1] "" ECM
 SG_ PtTqAtAxleFrntMinReqChks : 7|8@0+ (1.0,0.0) [0.0|255.0] "Unitless" ECM
 SG_ PtTqAtAxleFrntMinReqCntr : 31|4@0+ (1.0,0.0) [0.0|15.0] "Unitless" ECM
 SG_ PtTqAtAxleFrntMinReqPtTqAtAxleFrntMinReq : 15|16@0- (1.0,0.0) [-20000.0|20000.0] "NewtonMeter" ECM
 SG_ RoadSgnInfoSts : 37|3@0+ (1,0) [0|7] "" ECM
 SG_ RoadSgnInfoSts_UB : 38|1@0+ (1,0) [0|1] "" ECM
 SG_ WhlAFrntMax : 63|8@0+ (2.48,0.0) [0.0|632.4] "rad/s^2" ECM
 SG_ WhlAFrntMax_UB : 39|1@0+ (1,0) [0|1] "" ECM

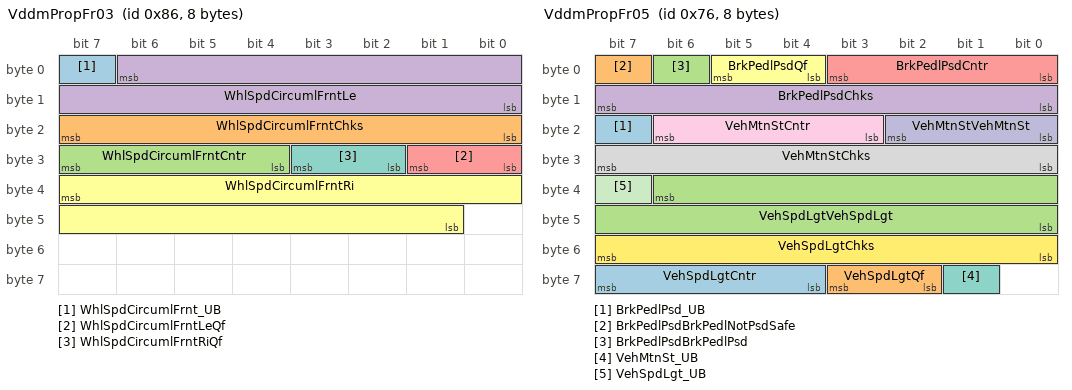
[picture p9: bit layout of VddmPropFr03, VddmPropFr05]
BO_ 134 VddmPropFr03: 8 VDDM
 SG_ WhlSpdCircumlFrnt_UB : 7|1@0+ (1,0) [0|1] "" DEM,TCM
 SG_ WhlSpdCircumlFrntChks : 23|8@0+ (1.0,0.0) [0.0|255.0] "Unitless" DEM,TCM
 SG_ WhlSpdCircumlFrntCntr : 31|4@0+ (1.0,0.0) [0.0|15.0] "Unitless" DEM,TCM
 SG_ WhlSpdCircumlFrntLe : 6|15@0+ (0.00391,0.0) [0.0|125.0027] "m/s" DEM,TCM
 SG_ WhlSpdCircumlFrntLeQf : 25|2@0+ (1,0) [0|3] "" DEM,TCM
 SG_ WhlSpdCircumlFrntRi : 39|15@0+ (0.00391,0.0) [0.0|125.0027] "m/s" DEM,TCM
 SG_ WhlSpdCircumlFrntRiQf : 27|2@0+ (1,0) [0|3] "" DEM,TCM

BO_ 118 VddmPropFr05: 8 VDDM
 SG_ BrkPedlPsd_UB : 23|1@0+ (1,0) [0|1] "" DEM,ESM,TCM
 SG_ BrkPedlPsdBrkPedlNotPsdSafe : 7|1@0+ (1,0) [0|1] "" DEM,ESM,TCM
 SG_ BrkPedlPsdBrkPedlPsd : 6|1@0+ (1,0) [0|1] "" DEM,ESM,TCM
 SG_ BrkPedlPsdChks : 15|8@0+ (1.0,0.0) [0.0|255.0] "Unitless" DEM,ESM,TCM
 SG_ BrkPedlPsdCntr : 3|4@0+ (1.0,0.0) [0.0|15.0] "Unitless" DEM,ESM,TCM
 SG_ BrkPedlPsdQf : 5|2@0+ (1,0) [0|3] "" DEM,ESM,TCM
 SG_ VehMtnSt_UB : 57|1@0+ (1,0) [0|1] "" IEM,IGM,TCM
 SG_ VehMtnStChks : 31|8@0+ (1.0,0.0) [0.0|255.0] "Unitless" IEM,IGM,TCM
 SG_ VehMtnStCntr : 22|4@0+ (1.0,0.0) [0.0|15.0] "Unitless" IEM,IGM,TCM
 SG_ VehMtnStVehMtnSt : 18|3@0+ (1,0) [0|7] "" IEM,IGM,TCM
 SG_ VehSpdLgt_UB : 39|1@0+ (1,0) [0|1] "" BECM,DEM,EGSM,ESM,IEM,IGM,ISGM,MVBM,MVCM,OBC,TACM,TCM
 SG_ VehSpdLgtChks : 55|8@0+ (1.0,0.0) [0.0|255.0] "Unitless" BECM,DEM,EGSM,ESM,IEM,IGM,ISGM,MVBM,MVCM,OBC,TACM,TCM
 SG_ VehSpdLgtCntr : 63|4@0+ (1.0,0.0) [0.0|15.0] "Unitless" BECM,DEM,EGSM,ESM,IEM,IGM,ISGM,MVBM,MVCM,OBC,TACM,TCM
 SG_ VehSpdLgtQf : 59|2@0+ (1,0) [0|3] "" BECM,DEM,EGSM,ESM,IEM,IGM,ISGM,MVBM,MVCM,OBC,TACM,TCM
 SG_ VehSpdLgtVehSpdLgt : 38|15@0+ (0.00391,0.0) [0.0|125.0027] "m/s" BECM,DEM,EGSM,ESM,IEM,IGM,ISGM,MVBM,MVCM,OBC,TACM,TCM

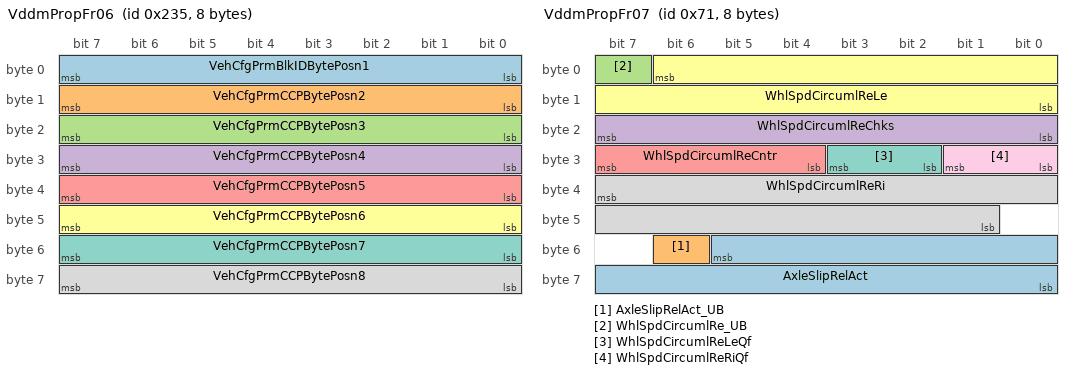
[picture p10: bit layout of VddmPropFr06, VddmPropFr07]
BO_ 565 VddmPropFr06: 8 VDDM
 SG_ VehCfgPrmBlkIDBytePosn1 : 7|8@0+ (1.0,0.0) [0.0|255.0] "Unitless" BECM,DEM,EGSM,ESM,IEM,IGM,OBC,TCM
 SG_ VehCfgPrmCCPBytePosn2 : 15|8@0+ (1.0,0.0) [0.0|255.0] "Unitless" BECM,DEM,EGSM,ESM,IEM,IGM,OBC,TCM
 SG_ VehCfgPrmCCPBytePosn3 : 23|8@0+ (1.0,0.0) [0.0|255.0] "Unitless" BECM,DEM,EGSM,ESM,IEM,IGM,OBC,TCM
 SG_ VehCfgPrmCCPBytePosn4 : 31|8@0+ (1.0,0.0) [0.0|255.0] "Unitless" BECM,DEM,EGSM,ESM,IEM,IGM,OBC,TCM
 SG_ VehCfgPrmCCPBytePosn5 : 39|8@0+ (1.0,0.0) [0.0|255.0] "Unitless" BECM,DEM,EGSM,ESM,IEM,IGM,OBC,TCM
 SG_ VehCfgPrmCCPBytePosn6 : 47|8@0+ (1.0,0.0) [0.0|255.0] "Unitless" BECM,DEM,EGSM,ESM,IEM,IGM,OBC,TCM
 SG_ VehCfgPrmCCPBytePosn7 : 55|8@0+ (1.0,0.0) [0.0|255.0] "Unitless" BECM,DEM,EGSM,ESM,IEM,IGM,OBC,TCM
 SG_ VehCfgPrmCCPBytePosn8 : 63|8@0+ (1.0,0.0) [0.0|255.0] "Unitless" BECM,DEM,EGSM,ESM,IEM,IGM,OBC,TCM

BO_ 113 VddmPropFr07: 8 VDDM
 SG_ AxleSlipRelAct : 53|14@0- (0.003906369,0.0) [-29.997007551|30.00091392] "m/s" ECM
 SG_ AxleSlipRelAct_UB : 54|1@0+ (1,0) [0|1] "" ECM
 SG_ WhlSpdCircumlRe_UB : 7|1@0+ (1,0) [0|1] "" DEM,TCM
 SG_ WhlSpdCircumlReChks : 23|8@0+ (1.0,0.0) [0.0|255.0] "Unitless" DEM,TCM
 SG_ WhlSpdCircumlReCntr : 31|4@0+ (1.0,0.0) [0.0|15.0] "Unitless" DEM,TCM
 SG_ WhlSpdCircumlReLe : 6|15@0+ (0.00391,0.0) [0.0|125.0027] "m/s" DEM,TCM
 SG_ WhlSpdCircumlReLeQf : 27|2@0+ (1,0) [0|3] "" DEM,TCM
 SG_ WhlSpdCircumlReRi : 39|15@0+ (0.00391,0.0) [0.0|125.0027] "m/s" DEM,TCM
 SG_ WhlSpdCircumlReRiQf : 25|2@0+ (1,0) [0|3] "" DEM,TCM

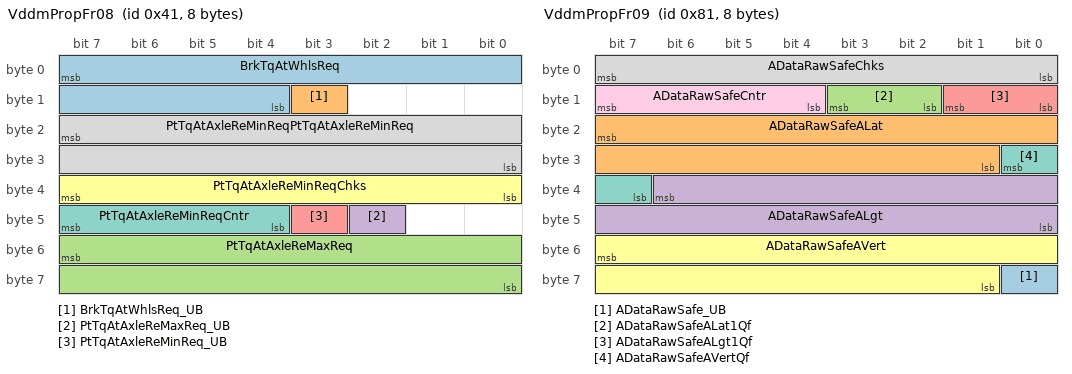
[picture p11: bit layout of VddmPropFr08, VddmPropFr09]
BO_ 65 VddmPropFr08: 8 VDDM
 SG_ BrkTqAtWhlsReq : 7|12@0+ (4.0,0.0) [0.0|16380.0] "Nm" ECM,TCM
 SG_ BrkTqAtWhlsReq_UB : 11|1@0+ (1,0) [0|1] "" ECM,TCM
 SG_ PtTqAtAxleReMaxReq : 55|16@0- (1.0,0.0) [-20000.0|20000.0] "NewtonMeter" DEM,ECM,IEM
 SG_ PtTqAtAxleReMaxReq_UB : 42|1@0+ (1,0) [0|1] "" DEM,ECM,IEM
 SG_ PtTqAtAxleReMinReq_UB : 43|1@0+ (1,0) [0|1] "" ECM
 SG_ PtTqAtAxleReMinReqChks : 39|8@0+ (1.0,0.0) [0.0|255.0] "Unitless" ECM
 SG_ PtTqAtAxleReMinReqCntr : 47|4@0+ (1.0,0.0) [0.0|15.0] "Unitless" ECM
 SG_ PtTqAtAxleReMinReqPtTqAtAxleReMinReq : 23|16@0- (1.0,0.0) [-20000.0|20000.0] "NewtonMeter" ECM

BO_ 129 VddmPropFr09: 8 VDDM
 SG_ ADataRawSafe_UB : 56|1@0+ (1,0) [0|1] "" DEM,ESM,TCM
 SG_ ADataRawSafeALat : 23|15@0- (0.0085,0.0) [-138.99200000000002|139.00050000000002] "m/s^2" DEM,ESM,TCM
 SG_ ADataRawSafeALat1Qf : 11|2@0+ (1,0) [0|3] "" DEM,ESM,TCM
 SG_ ADataRawSafeALgt : 38|15@0- (0.0085,0.0) [-138.99200000000002|139.00050000000002] "m/s^2" DEM,ESM,TCM
 SG_ ADataRawSafeALgt1Qf : 9|2@0+ (1,0) [0|3] "" DEM,ESM,TCM
 SG_ ADataRawSafeAVert : 55|15@0- (0.0085,0.0) [-138.99200000000002|139.00050000000002] "m/s^2" DEM,ESM,TCM
 SG_ ADataRawSafeAVertQf : 24|2@0+ (1,0) [0|3] "" DEM,ESM,TCM
 SG_ ADataRawSafeChks : 7|8@0+ (1.0,0.0) [0.0|255.0] "Unitless" DEM,ESM,TCM
 SG_ ADataRawSafeCntr : 15|4@0+ (1.0,0.0) [0.0|15.0] "Unitless" DEM,ESM,TCM

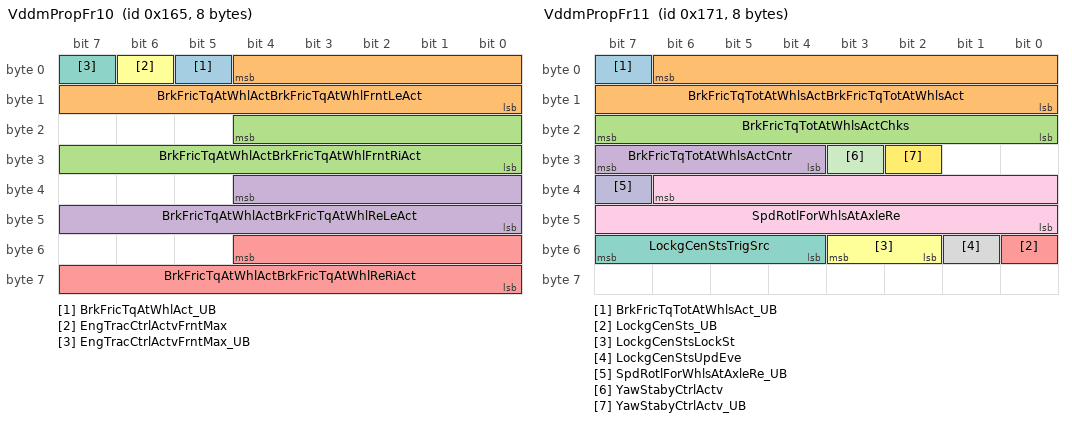
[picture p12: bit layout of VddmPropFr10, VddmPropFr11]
BO_ 357 VddmPropFr10: 8 VDDM
 SG_ BrkFricTqAtWhlAct_UB : 5|1@0+ (1,0) [0|1] "" ECM,TCM
 SG_ BrkFricTqAtWhlActBrkFricTqAtWhlFrntLeAct : 4|13@0+ (1.0,0.0) [0.0|8191.0] "Nm" ECM,TCM
 SG_ BrkFricTqAtWhlActBrkFricTqAtWhlFrntRiAct : 20|13@0+ (1.0,0.0) [0.0|8191.0] "Nm" ECM,TCM
 SG_ BrkFricTqAtWhlActBrkFricTqAtWhlReLeAct : 36|13@0+ (1.0,0.0) [0.0|8191.0] "Nm" ECM,TCM
 SG_ BrkFricTqAtWhlActBrkFricTqAtWhlReRiAct : 52|13@0+ (1.0,0.0) [0.0|8191.0] "Nm" ECM,TCM
 SG_ EngTracCtrlActvFrntMax : 6|1@0+ (1,0) [0|1] "" DEM
 SG_ EngTracCtrlActvFrntMax_UB : 7|1@0+ (1,0) [0|1] "" DEM

BO_ 369 VddmPropFr11: 8 VDDM
 SG_ BrkFricTqTotAtWhlsAct_UB : 7|1@0+ (1,0) [0|1] "" ECM,TCM
 SG_ BrkFricTqTotAtWhlsActBrkFricTqTotAtWhlsAct : 6|15@0+ (1.0,0.0) [0.0|20000.0] "NewtonMeter" ECM,TCM
 SG_ BrkFricTqTotAtWhlsActChks : 23|8@0+ (1.0,0.0) [0.0|255.0] "Unitless" ECM,TCM
 SG_ BrkFricTqTotAtWhlsActCntr : 31|4@0+ (1.0,0.0) [0.0|15.0] "Unitless" ECM,TCM
 SG_ LockgCenSts_UB : 48|1@0+ (1,0) [0|1] "" OBC
 SG_ LockgCenStsLockSt : 51|2@0+ (1,0) [0|3] "" OBC
 SG_ LockgCenStsTrigSrc : 55|4@0+ (1,0) [0|15] "" OBC
 SG_ LockgCenStsUpdEve : 49|1@0+ (1,0) [0|1] "" OBC
 SG_ SpdRotlForWhlsAtAxleRe : 38|15@0+ (0.5,0.0) [0.0|16383.5] "rpm" ECM,IEM
 SG_ SpdRotlForWhlsAtAxleRe_UB : 39|1@0+ (1,0) [0|1] "" ECM,IEM
 SG_ YawStabyCtrlActv : 27|1@0+ (1,0) [0|1] "" DEM,ECM
 SG_ YawStabyCtrlActv_UB : 26|1@0+ (1,0) [0|1] "" DEM,ECM

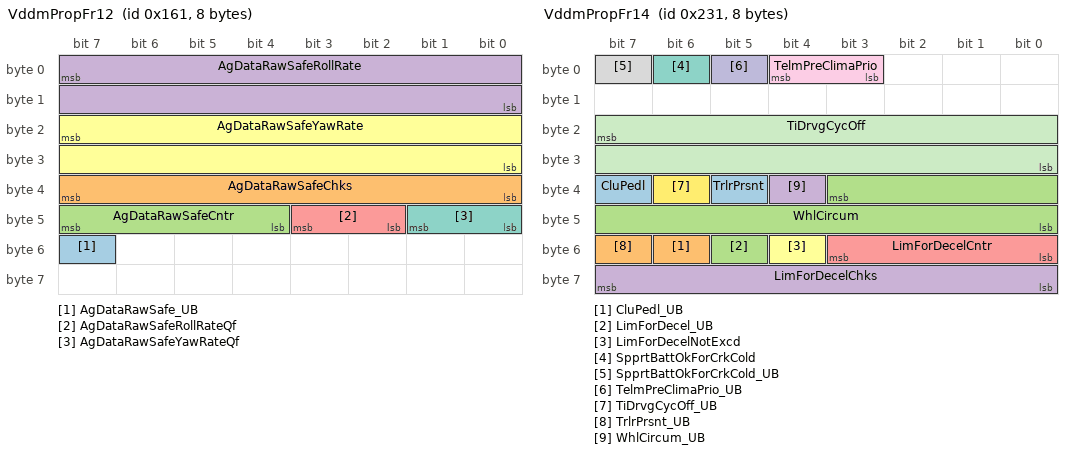
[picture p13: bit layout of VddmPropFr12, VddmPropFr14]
BO_ 353 VddmPropFr12: 8 VDDM
 SG_ AgDataRawSafe_UB : 55|1@0+ (1,0) [0|1] "" DEM
 SG_ AgDataRawSafeChks : 39|8@0+ (1.0,0.0) [0.0|255.0] "Unitless" DEM
 SG_ AgDataRawSafeCntr : 47|4@0+ (1.0,0.0) [0.0|15.0] "Unitless" DEM
 SG_ AgDataRawSafeRollRate : 7|16@0- (0.000244140625,0.0) [-6.0|6.0] "rad/s" DEM
 SG_ AgDataRawSafeRollRateQf : 43|2@0+ (1,0) [0|3] "" DEM
 SG_ AgDataRawSafeYawRate : 23|16@0- (0.000244140625,0.0) [-6.0|6.0] "rad/s" DEM
 SG_ AgDataRawSafeYawRateQf : 41|2@0+ (1,0) [0|3] "" DEM

BO_ 561 VddmPropFr14: 8 VDDM
 SG_ CluPedl : 39|1@0+ (1,0) [0|1] "" DEM
 SG_ CluPedl_UB : 54|1@0+ (1,0) [0|1] "" DEM
 SG_ LimForDecel_UB : 53|1@0+ (1,0) [0|1] "" ECM
 SG_ LimForDecelChks : 63|8@0+ (1.0,0.0) [0.0|255.0] "Unitless" ECM
 SG_ LimForDecelCntr : 51|4@0+ (1.0,0.0) [0.0|15.0] "Unitless" ECM
 SG_ LimForDecelNotExcd : 52|1@0+ (1,0) [0|1] "" ECM
 SG_ SpprtBattOkForCrkCold : 6|1@0+ (1,0) [0|1] "" ECM
 SG_ SpprtBattOkForCrkCold_UB : 7|1@0+ (1,0) [0|1] "" ECM
 SG_ TelmPreClimaPrio : 4|2@0+ (1,0) [0|3] "" ECM
 SG_ TelmPreClimaPrio_UB : 5|1@0+ (1,0) [0|1] "" ECM
 SG_ TiDrvgCycOff : 23|16@0+ (1.0,0.0) [0.0|65535.0] "Unitless" DEM,ECM,TCM
 SG_ TiDrvgCycOff_UB : 38|1@0+ (1,0) [0|1] "" DEM,ECM,TCM
 SG_ TrlrPrsnt : 37|1@0+ (1,0) [0|1] "" DEM
 SG_ TrlrPrsnt_UB : 55|1@0+ (1,0) [0|1] "" DEM
 SG_ WhlCircum : 35|12@0+ (1.0,0.0) [0.0|4095.0] "Unitless" DEM,TCM
 SG_ WhlCircum_UB : 36|1@0+ (1,0) [0|1] "" DEM,TCM

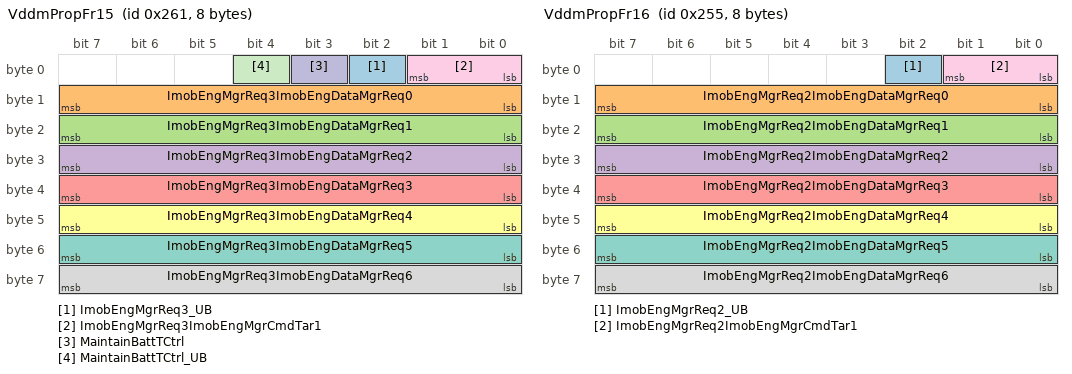
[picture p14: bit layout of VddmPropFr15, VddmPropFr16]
BO_ 609 VddmPropFr15: 8 VDDM
 SG_ ImobEngMgrReq3_UB : 2|1@0+ (1,0) [0|1] "" IGM
 SG_ ImobEngMgrReq3ImobEngDataMgrReq0 : 15|8@0+ (1.0,0.0) [0.0|255.0] "Unitless" IGM
 SG_ ImobEngMgrReq3ImobEngDataMgrReq1 : 23|8@0+ (1.0,0.0) [0.0|255.0] "Unitless" IGM
 SG_ ImobEngMgrReq3ImobEngDataMgrReq2 : 31|8@0+ (1.0,0.0) [0.0|255.0] "Unitless" IGM
 SG_ ImobEngMgrReq3ImobEngDataMgrReq3 : 39|8@0+ (1.0,0.0) [0.0|255.0] "Unitless" IGM
 SG_ ImobEngMgrReq3ImobEngDataMgrReq4 : 47|8@0+ (1.0,0.0) [0.0|255.0] "Unitless" IGM
 SG_ ImobEngMgrReq3ImobEngDataMgrReq5 : 55|8@0+ (1.0,0.0) [0.0|255.0] "Unitless" IGM
 SG_ ImobEngMgrReq3ImobEngDataMgrReq6 : 63|8@0+ (1.0,0.0) [0.0|255.0] "Unitless" IGM
 SG_ ImobEngMgrReq3ImobEngMgrCmdTar1 : 1|2@0+ (1,0) [0|3] "" IGM
 SG_ MaintainBattTCtrl : 3|1@0+ (1,0) [0|1] "" BECM
 SG_ MaintainBattTCtrl_UB : 4|1@0+ (1,0) [0|1] "" BECM

BO_ 597 VddmPropFr16: 8 VDDM
 SG_ ImobEngMgrReq2_UB : 2|1@0+ (1,0) [0|1] "" IEM
 SG_ ImobEngMgrReq2ImobEngDataMgrReq0 : 15|8@0+ (1.0,0.0) [0.0|255.0] "Unitless" IEM
 SG_ ImobEngMgrReq2ImobEngDataMgrReq1 : 23|8@0+ (1.0,0.0) [0.0|255.0] "Unitless" IEM
 SG_ ImobEngMgrReq2ImobEngDataMgrReq2 : 31|8@0+ (1.0,0.0) [0.0|255.0] "Unitless" IEM
 SG_ ImobEngMgrReq2ImobEngDataMgrReq3 : 39|8@0+ (1.0,0.0) [0.0|255.0] "Unitless" IEM
 SG_ ImobEngMgrReq2ImobEngDataMgrReq4 : 47|8@0+ (1.0,0.0) [0.0|255.0] "Unitless" IEM
 SG_ ImobEngMgrReq2ImobEngDataMgrReq5 : 55|8@0+ (1.0,0.0) [0.0|255.0] "Unitless" IEM
 SG_ ImobEngMgrReq2ImobEngDataMgrReq6 : 63|8@0+ (1.0,0.0) [0.0|255.0] "Unitless" IEM
 SG_ ImobEngMgrReq2ImobEngMgrCmdTar1 : 1|2@0+ (1,0) [0|3] "" IEM

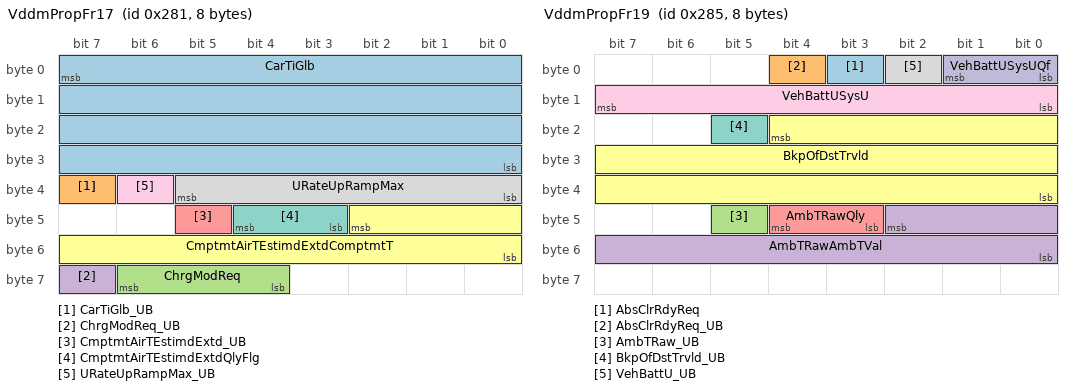
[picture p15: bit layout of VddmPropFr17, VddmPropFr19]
BO_ 641 VddmPropFr17: 8 VDDM
 SG_ CarTiGlb : 7|32@0+ (0.1,0.0) [0.0|429496729.5] "s" BECM,DEM,EGSM,ESM,IEM,IGM,ISGM,MVBM,MVCM,OBC,TACM,TCM
 SG_ CarTiGlb_UB : 39|1@0+ (1,0) [0|1] "" BECM,DEM,EGSM,ESM,IEM,IGM,ISGM,MVBM,MVCM,OBC,TACM,TCM
 SG_ ChrgModReq : 62|3@0+ (1,0) [0|7] "" ECM
 SG_ ChrgModReq_UB : 63|1@0+ (1,0) [0|1] "" ECM
 SG_ CmptmtAirTEstimdExtd_UB : 45|1@0+ (1,0) [0|1] "" TACM
 SG_ CmptmtAirTEstimdExtdComptmtT : 42|11@0+ (0.1,-60.0) [-60.0|125.0] "degC" TACM
 SG_ CmptmtAirTEstimdExtdQlyFlg : 44|2@0+ (1,0) [0|3] "" TACM
 SG_ URateUpRampMax : 37|6@0+ (0.1,0.0) [0.0|6.0] "V/s" ECM
 SG_ URateUpRampMax_UB : 38|1@0+ (1,0) [0|1] "" ECM

BO_ 86 VddmPropFr18: 8 VDDM
 SG_ ChrgnUReq : 55|8@0+ (0.025,10.6) [10.6|16.0] "Volt" ECM,IGM,MVCM
 SG_ ChrgnUReq_UB : 40|1@0+ (1,0) [0|1] "" ECM,IGM,MVCM
 SG_ IntrBriSts : 44|4@0+ (1.0,0.0) [0.0|15.0] "Unitless" EGSM
 SG_ IntrBriSts_UB : 45|1@0+ (1,0) [0|1] "" EGSM
 SG_ TwliBriSts : 47|1@0+ (1,0) [0|1] "" EGSM
 SG_ TwliBriSts_UB : 46|1@0+ (1,0) [0|1] "" EGSM
 SG_ VehModMngtGlbSafe1_UB : 32|1@0+ (1,0) [0|1] "" BECM,DEM,EGSM,ESM,IEM,IGM,ISGM,MVBM,MVCM,OBC,TACM,TCM
 SG_ VehModMngtGlbSafe1CarModSts1 : 39|3@0+ (1,0) [0|7] "" BECM,DEM,EGSM,ESM,IEM,IGM,ISGM,MVBM,MVCM,OBC,TACM,TCM
 SG_ VehModMngtGlbSafe1CarModSubtypWdCarModSubtyp : 36|3@0+ (1.0,0.0) [0.0|7.0] "Unitless" BECM,DEM,EGSM,ESM,IEM,IGM,ISGM,MVBM,MVCM,OBC,TACM,TCM
 SG_ VehModMngtGlbSafe1Chks : 7|8@0+ (1.0,0.0) [0.0|255.0] "Unitless" BECM,DEM,EGSM,ESM,IEM,IGM,ISGM,MVBM,MVCM,OBC,TACM,TCM
 SG_ VehModMngtGlbSafe1Cntr : 15|4@0+ (1.0,0.0) [0.0|15.0] "Unitless" BECM,DEM,EGSM,ESM,IEM,IGM,ISGM,MVBM,MVCM,OBC,TACM,TCM
 SG_ VehModMngtGlbSafe1EgyLvlElecMai : 27|4@0+ (1.0,0.0) [0.0|15.0] "Unitless" BECM,DEM,EGSM,ESM,IEM,IGM,ISGM,MVBM,MVCM,OBC,TACM,TCM
 SG_ VehModMngtGlbSafe1EgyLvlElecSubtyp : 31|4@0+ (1.0,0.0) [0.0|15.0] "Unitless" BECM,DEM,EGSM,ESM,IEM,IGM,ISGM,MVBM,MVCM,OBC,TACM,TCM
 SG_ VehModMngtGlbSafe1FltEgyCnsWdSts : 33|1@0+ (1,0) [0|1] "" BECM,DEM,EGSM,ESM,IEM,IGM,ISGM,MVBM,MVCM,OBC,TACM,TCM
 SG_ VehModMngtGlbSafe1PwrLvlElecMai : 19|4@0+ (1.0,0.0) [0.0|15.0] "Unitless" BECM,DEM,EGSM,ESM,IEM,IGM,ISGM,MVBM,MVCM,OBC,TACM,TCM
 SG_ VehModMngtGlbSafe1PwrLvlElecSubtyp : 23|4@0+ (1.0,0.0) [0.0|15.0] "Unitless" BECM,DEM,EGSM,ESM,IEM,IGM,ISGM,MVBM,MVCM,OBC,TACM,TCM
 SG_ VehModMngtGlbSafe1UsgModSts : 11|4@0+ (1,0) [0|15] "" BECM,DEM,EGSM,ESM,IEM,IGM,ISGM,MVBM,MVCM,OBC,TACM,TCM

BO_ 645 VddmPropFr19: 8 VDDM
 SG_ AbsClrRdyReq : 3|1@0+ (1,0) [0|1] "" ECM
 SG_ AbsClrRdyReq_UB : 4|1@0+ (1,0) [0|1] "" ECM
 SG_ AmbTRaw_UB : 45|1@0+ (1,0) [0|1] "" BECM,DEM,ECM,MVBM,TACM
 SG_ AmbTRawAmbTVal : 42|11@0+ (0.1,-70.0) [-70.0|134.70000000000002] "degC" BECM,DEM,ECM,MVBM,TACM
 SG_ AmbTRawQly : 44|2@0+ (1,0) [0|3] "" BECM,DEM,ECM,MVBM,TACM
 SG_ BkpOfDstTrvld : 20|21@0+ (1.0,0.0) [0.0|2000000.0] "km" BECM,DEM,EGSM,ESM,IEM,IGM,ISGM,MVBM,MVCM,OBC,TACM,TCM
 SG_ BkpOfDstTrvld_UB : 21|1@0+ (1,0) [0|1] "" BECM,DEM,EGSM,ESM,IEM,IGM,ISGM,MVBM,MVCM,OBC,TACM,TCM
 SG_ VehBattU_UB : 2|1@0+ (1,0) [0|1] "" BECM,DEM,EGSM,ESM,IEM,IGM,ISGM,MVBM,MVCM,OBC,TACM,TCM
 SG_ VehBattUSysU : 15|8@0+ (0.1,0.0) [0.0|25.0] "Volt" BECM,DEM,EGSM,ESM,IEM,IGM,ISGM,MVBM,MVCM,OBC,TACM,TCM
 SG_ VehBattUSysUQf : 1|2@0+ (1,0) [0|3] "" BECM,DEM,EGSM,ESM,IEM,IGM,ISGM,MVBM,MVCM,OBC,TACM,TCM

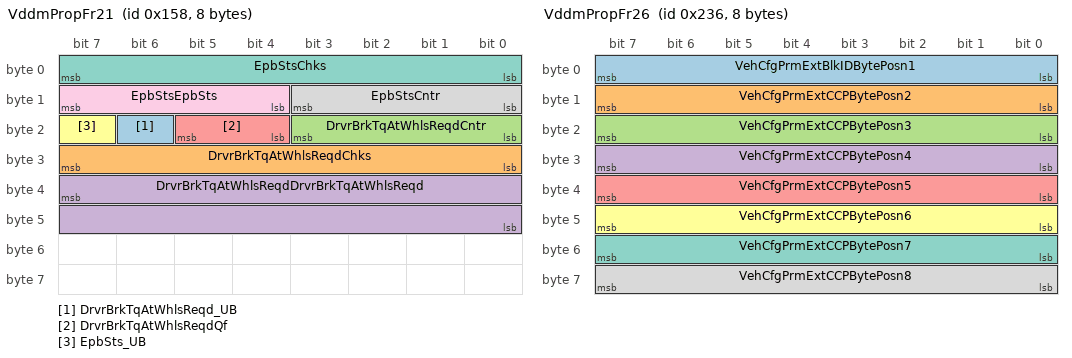
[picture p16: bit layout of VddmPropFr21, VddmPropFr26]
BO_ 344 VddmPropFr21: 8 VDDM
 SG_ DrvrBrkTqAtWhlsReqd_UB : 22|1@0+ (1,0) [0|1] "" TCM
 SG_ DrvrBrkTqAtWhlsReqdChks : 31|8@0+ (1.0,0.0) [0.0|255.0] "Unitless" TCM
 SG_ DrvrBrkTqAtWhlsReqdCntr : 19|4@0+ (1.0,0.0) [0.0|15.0] "Unitless" TCM
 SG_ DrvrBrkTqAtWhlsReqdDrvrBrkTqAtWhlsReqd : 39|16@0- (1.0,0.0) [-20000.0|20000.0] "NewtonMeter" TCM
 SG_ DrvrBrkTqAtWhlsReqdQf : 21|2@0+ (1,0) [0|3] "" TCM
 SG_ EpbSts_UB : 23|1@0+ (1,0) [0|1] "" DEM,ECM,TCM
 SG_ EpbStsChks : 7|8@0+ (1.0,0.0) [0.0|255.0] "Unitless" DEM,ECM,TCM
 SG_ EpbStsCntr : 11|4@0+ (1.0,0.0) [0.0|15.0] "Unitless" DEM,ECM,TCM
 SG_ EpbStsEpbSts : 15|4@0+ (1,0) [0|15] "" DEM,ECM,TCM

BO_ 566 VddmPropFr26: 8 VDDM
 SG_ VehCfgPrmExtBlkIDBytePosn1 : 7|8@0+ (1.0,0.0) [0.0|255.0] "Unitless" BECM,DEM,EGSM,ESM,IEM,IGM,OBC,TCM
 SG_ VehCfgPrmExtCCPBytePosn2 : 15|8@0+ (1.0,0.0) [0.0|255.0] "Unitless" BECM,DEM,EGSM,ESM,IEM,IGM,OBC,TCM
 SG_ VehCfgPrmExtCCPBytePosn3 : 23|8@0+ (1.0,0.0) [0.0|255.0] "Unitless" BECM,DEM,EGSM,ESM,IEM,IGM,OBC,TCM
 SG_ VehCfgPrmExtCCPBytePosn4 : 31|8@0+ (1.0,0.0) [0.0|255.0] "Unitless" BECM,DEM,EGSM,ESM,IEM,IGM,OBC,TCM
 SG_ VehCfgPrmExtCCPBytePosn5 : 39|8@0+ (1.0,0.0) [0.0|255.0] "Unitless" BECM,DEM,EGSM,ESM,IEM,IGM,OBC,TCM
 SG_ VehCfgPrmExtCCPBytePosn6 : 47|8@0+ (1.0,0.0) [0.0|255.0] "Unitless" BECM,DEM,EGSM,ESM,IEM,IGM,OBC,TCM
 SG_ VehCfgPrmExtCCPBytePosn7 : 55|8@0+ (1.0,0.0) [0.0|255.0] "Unitless" BECM,DEM,EGSM,ESM,IEM,IGM,OBC,TCM
 SG_ VehCfgPrmExtCCPBytePosn8 : 63|8@0+ (1.0,0.0) [0.0|255.0] "Unitless" BECM,DEM,EGSM,ESM,IEM,IGM,OBC,TCM

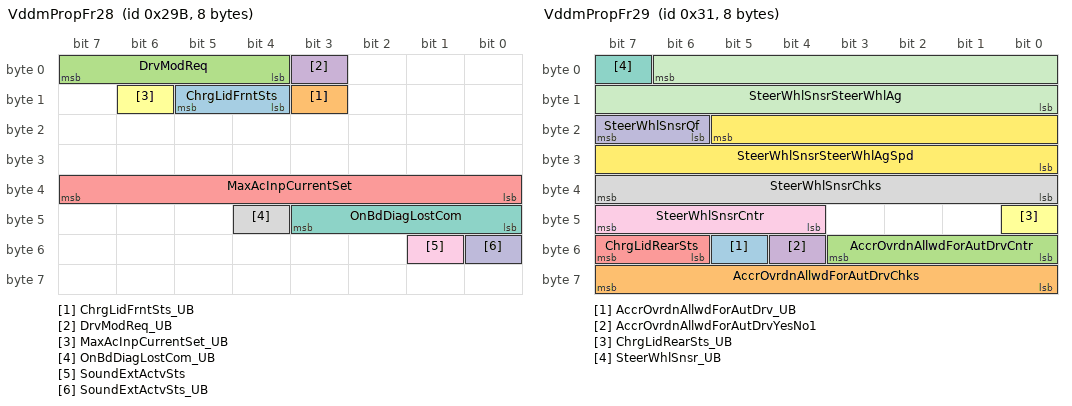
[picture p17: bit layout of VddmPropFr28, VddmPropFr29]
BO_ 667 VddmPropFr28: 8 VDDM
 SG_ ChrgLidFrntSts : 13|2@0+ (1,0) [0|3] "" OBC
 SG_ ChrgLidFrntSts_UB : 11|1@0+ (1,0) [0|1] "" OBC
 SG_ DrvModReq : 7|4@0+ (1,0) [0|15] "" DEM
 SG_ DrvModReq_UB : 3|1@0+ (1,0) [0|1] "" DEM
 SG_ MaxAcInpCurrentSet : 39|8@0+ (1.0,0.0) [0.0|255.0] "Unitless" OBC
 SG_ MaxAcInpCurrentSet_UB : 14|1@0+ (1,0) [0|1] "" OBC
 SG_ OnBdDiagLostCom : 43|4@0+ (1.0,0.0) [0.0|15.0] "Unitless" ECM
 SG_ OnBdDiagLostCom_UB : 44|1@0+ (1,0) [0|1] "" ECM
 SG_ SoundExtActvSts : 49|1@0+ (1,0) [0|1] "" ESM
 SG_ SoundExtActvSts_UB : 48|1@0+ (1,0) [0|1] "" ESM

BO_ 49 VddmPropFr29: 8 VDDM
 SG_ AccrOvrdnAllwdForAutDrv_UB : 53|1@0+ (1,0) [0|1] "" ECM
 SG_ AccrOvrdnAllwdForAutDrvChks : 63|8@0+ (1.0,0.0) [0.0|255.0] "Unitless" ECM
 SG_ AccrOvrdnAllwdForAutDrvCntr : 51|4@0+ (1.0,0.0) [0.0|15.0] "Unitless" ECM
 SG_ AccrOvrdnAllwdForAutDrvYesNo1 : 52|1@0+ (1,0) [0|1] "" ECM
 SG_ ChrgLidRearSts : 55|2@0+ (1,0) [0|3] "" Vector_XXX
 SG_ ChrgLidRearSts_UB : 40|1@0+ (1,0) [0|1] "" Vector_XXX
 SG_ SteerWhlSnsr_UB : 7|1@0+ (1,0) [0|1] "" DEM
 SG_ SteerWhlSnsrChks : 39|8@0+ (1.0,0.0) [0.0|255.0] "Unitless" DEM
 SG_ SteerWhlSnsrCntr : 47|4@0+ (1.0,0.0) [0.0|15.0] "Unitless" DEM
 SG_ SteerWhlSnsrQf : 23|2@0+ (1,0) [0|3] "" DEM
 SG_ SteerWhlSnsrSteerWhlAg : 6|15@0- (0.0009765625,0.0) [-14.5|14.5] "rad" DEM
 SG_ SteerWhlSnsrSteerWhlAgSpd : 21|14@0- (0.0078125,0.0) [-50.0|50.0] "rad/s" DEM

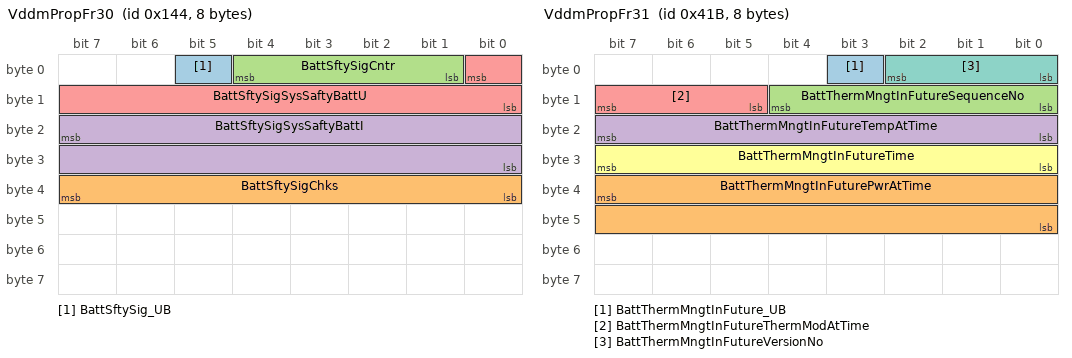
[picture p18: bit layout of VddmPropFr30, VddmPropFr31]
BO_ 324 VddmPropFr30: 8 VDDM
 SG_ BattSftySig_UB : 5|1@0+ (1,0) [0|1] "" MVCM
 SG_ BattSftySigChks : 39|8@0+ (1.0,0.0) [0.0|255.0] "Unitless" MVCM
 SG_ BattSftySigCntr : 4|4@0+ (1.0,0.0) [0.0|15.0] "Unitless" MVCM
 SG_ BattSftySigSysSaftyBattI : 23|16@0+ (0.015625,-512.0) [-512.0|511.984375] "A" MVCM
 SG_ BattSftySigSysSaftyBattU : 0|9@0+ (0.025,5.0) [5.0|17.775] "Volt" MVCM

BO_ 1051 VddmPropFr31: 8 VDDM
 SG_ BattThermMngtInFuture_UB : 3|1@0+ (1,0) [0|1] "" ECM
 SG_ BattThermMngtInFuturePwrAtTime : 39|16@0+ (50.0,-25000.0) [-25000.0|25000.0] "W" ECM
 SG_ BattThermMngtInFutureSequenceNo : 12|5@0+ (1.0,0.0) [0.0|31.0] "Unitless" ECM
 SG_ BattThermMngtInFutureTempAtTime : 23|8@0+ (1.0,-50.0) [-50.0|205.0] "degC" ECM
 SG_ BattThermMngtInFutureThermModAtTime : 15|3@0+ (1,0) [0|7] "" ECM
 SG_ BattThermMngtInFutureTime : 31|8@0+ (1.0,0.0) [0.0|255.0] "Unitless" ECM
 SG_ BattThermMngtInFutureVersionNo : 2|3@0+ (1.0,0.0) [0.0|7.0] "Unitless" ECM

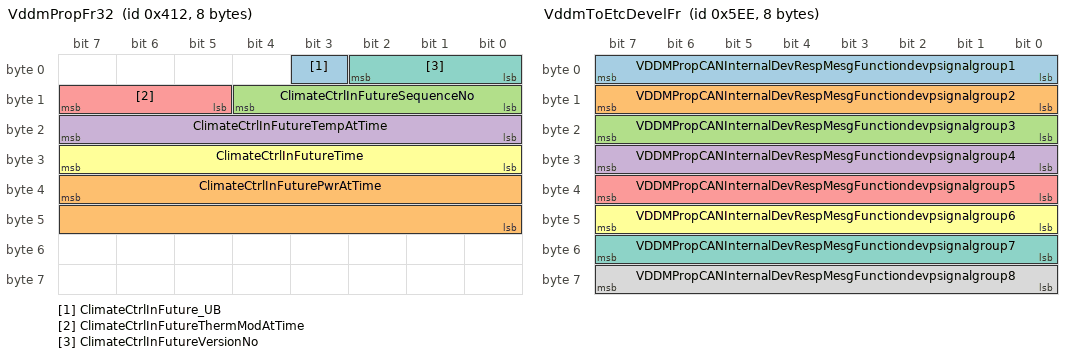
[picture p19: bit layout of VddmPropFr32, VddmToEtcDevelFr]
BO_ 1042 VddmPropFr32: 8 VDDM
 SG_ ClimateCtrlInFuture_UB : 3|1@0+ (1,0) [0|1] "" ECM
 SG_ ClimateCtrlInFuturePwrAtTime : 39|16@0+ (50.0,-25000.0) [-25000.0|25000.0] "W" ECM
 SG_ ClimateCtrlInFutureSequenceNo : 12|5@0+ (1.0,0.0) [0.0|31.0] "Unitless" ECM
 SG_ ClimateCtrlInFutureTempAtTime : 23|8@0+ (1.0,-50.0) [-50.0|205.0] "degC" ECM
 SG_ ClimateCtrlInFutureThermModAtTime : 15|3@0+ (1,0) [0|7] "" ECM
 SG_ ClimateCtrlInFutureTime : 31|8@0+ (1.0,0.0) [0.0|255.0] "Unitless" ECM
 SG_ ClimateCtrlInFutureVersionNo : 2|3@0+ (1.0,0.0) [0.0|7.0] "Unitless" ECM

BO_ 1318 VddmPropNMfr: 8 VDDM
 SG_ PNC22_VDDM : 22|1@0+ (1,0) [0|0] "" TCM
 SG_ PNC25_VDDM : 25|1@0+ (1,0) [0|0] "" TCM
 SG_ PNC26_VDDM : 26|1@0+ (1,0) [0|0] "" TCM
 SG_ PNC28_VDDM : 28|1@0+ (1,0) [0|0] "" TCM
 SG_ PNC29_VDDM : 29|1@0+ (1,0) [0|0] "" TCM
 SG_ PNC30_VDDM : 30|1@0+ (1,0) [0|0] "" TCM
 SG_ PNC16_VDDM : 16|1@0+ (1,0) [0|0] "" TCM
 SG_ PNC17_VDDM : 17|1@0+ (1,0) [0|0] "" TCM
 SG_ PNC24_VDDM : 24|1@0+ (1,0) [0|0] "" TCM
 SG_ PNC21_VDDM : 21|1@0+ (1,0) [0|0] "" TCM
 SG_ PNC20_VDDM : 20|1@0+ (1,0) [0|0] "" TCM
 SG_ PNC19_VDDM : 19|1@0+ (1,0) [0|0] "" TCM
 SG_ PNC33_VDDM : 33|1@0+ (1,0) [0|0] "" TCM
 SG_ PNC39_VDDM : 39|1@0+ (1,0) [0|0] "" TCM
 SG_ PNC36_VDDM : 36|1@0+ (1,0) [0|0] "" TCM
 SG_ PNC35_VDDM : 35|1@0+ (1,0) [0|0] "" TCM
 SG_ NM_PNI_VDDM : 14|1@0+ (1,0) [0|0] "" TCM
 SG_ NM_AW_VDDM : 12|1@0+ (1,0) [0|0] "" TCM
 SG_ NM_CS_VDDM : 11|1@0+ (1,0) [0|0] "" TCM
 SG_ NM_RMR_VDDM : 8|1@0+ (1,0) [0|0] "" TCM
 SG_ NM_NodeID_VDDM : 7|8@0+ (1,0) [0|0] "" TCM

BO_ 1375 VddmPropVFCInfoEnaFr: 1 VDDM
 SG_ VFCInfoEna : 0|1@0+ (1,0) [0|1] "" BECM,EGSM,OBC
 SG_ VFCInfoEna_UB : 1|1@0+ (1,0) [0|1] "" BECM,EGSM,OBC

BO_ 2047 VddmToAllFuncPropDiagReqFrame: 8 VDDM
 SG_ VddmToAllFuncPropDiagReqNpdu : 7|64@0+ (1,0) [0|0] "" BECM, DEM, ECM, EGSM, ESM, IEM, IGM, ISGM, MVBM, MVCM, MVEM, OBC, TACM, TCM

BO_ 1845 VddmToBecmPropDiagReqFrame: 8 VDDM
 SG_ VddmToBecmPropDiagReqNpdu : 7|64@0+ (1,0) [0|0] "" BECM

BO_ 1872 VddmToCddPropDiagReqFrame1: 8 VDDM
 SG_ VddmToCddPropDiagReqNpdu : 7|64@0+ (1,0) [0|0] "" Vector_XXX

BO_ 1848 VddmToDemPropDiagReqFrame: 8 VDDM
 SG_ VddmToDemPropDiagReqNpdu : 7|64@0+ (1,0) [0|0] "" DEM

BO_ 1840 VddmToEcmPropDiagReqFrame: 8 VDDM
 SG_ VddmToEcmPropDiagReqNpdu : 7|64@0+ (1,0) [0|0] "" ECM

BO_ 1843 VddmToEgsmPropDiagReqFrame: 8 VDDM
 SG_ VddmToEgsmPropDiagReqNpdu : 7|64@0+ (1,0) [0|0] "" EGSM

BO_ 1850 VddmToEsmPropDiagReqFrame: 8 VDDM
 SG_ VddmToEsmPropDiagReqNpdu : 7|64@0+ (1,0) [0|0] "" ESM

BO_ 1518 VddmToEtcDevelFr: 8 VDDM
 SG_ VDDMPropCANInternalDevRespMesgFunctiondevpsignalgroup1 : 7|8@0+ (1.0,0.0) [0.0|255.0] "Unitless" ETC
 SG_ VDDMPropCANInternalDevRespMesgFunctiondevpsignalgroup2 : 15|8@0+ (1.0,0.0) [0.0|255.0] "Unitless" ETC
 SG_ VDDMPropCANInternalDevRespMesgFunctiondevpsignalgroup3 : 23|8@0+ (1.0,0.0) [0.0|255.0] "Unitless" ETC
 SG_ VDDMPropCANInternalDevRespMesgFunctiondevpsignalgroup4 : 31|8@0+ (1.0,0.0) [0.0|255.0] "Unitless" ETC
 SG_ VDDMPropCANInternalDevRespMesgFunctiondevpsignalgroup5 : 39|8@0+ (1.0,0.0) [0.0|255.0] "Unitless" ETC
 SG_ VDDMPropCANInternalDevRespMesgFunctiondevpsignalgroup6 : 47|8@0+ (1.0,0.0) [0.0|255.0] "Unitless" ETC
 SG_ VDDMPropCANInternalDevRespMesgFunctiondevpsignalgroup7 : 55|8@0+ (1.0,0.0) [0.0|255.0] "Unitless" ETC
 SG_ VDDMPropCANInternalDevRespMesgFunctiondevpsignalgroup8 : 63|8@0+ (1.0,0.0) [0.0|255.0] "Unitless" ETC

BO_ 1847 VddmToIemPropDiagReqFrame: 8 VDDM
 SG_ VddmToIemPropDiagReqNpdu : 7|64@0+ (1,0) [0|0] "" IEM

BO_ 1846 VddmToIgmPropDiagReqFrame: 8 VDDM
 SG_ VddmToIgmPropDiagReqNpdu : 7|64@0+ (1,0) [0|0] "" IGM

BO_ 1854 VddmToIsgmPropDiagReqFrame: 8 VDDM
 SG_ VddmToIsgmPropDiagReqNpdu : 7|64@0+ (1,0) [0|0] "" ISGM

BO_ 1841 VddmToMgmPropDiagReqFrame1: 8 VDDM
 SG_ VddmToMgmPropDiagReqNpdu : 7|64@0+ (1,0) [0|0] "" Vector_XXX

BO_ 1874 VddmToMvbmPropDiagReqFrame: 8 VDDM
 SG_ VddmToMvbmPropDiagReqNpdu : 7|64@0+ (1,0) [0|0] "" MVBM

BO_ 1853 VddmToMvcmPropDiagReqFrame: 8 VDDM
 SG_ VddmToMvcmPropDiagReqNpdu : 7|64@0+ (1,0) [0|0] "" MVCM

BO_ 1873 VddmToMvemPropDiagReqFrame1: 8 VDDM
 SG_ VddmToMvemPropDiagReqNpdu : 7|64@0+ (1,0) [0|0] "" MVEM

BO_ 1844 VddmToObcPropDiagReqFrame: 8 VDDM
 SG_ VddmToObcPropDiagReqNpdu : 7|64@0+ (1,0) [0|0] "" OBC

BO_ 1852 VddmToTacmPropDiagReqFrame: 8 VDDM
 SG_ VddmToTacmPropDiagReqNpdu : 7|64@0+ (1,0) [0|0] "" TACM

BO_ 1842 VddmToTcmPropDiagReqFrame: 8 VDDM
 SG_ VddmToTcmPropDiagReqNpdu : 7|64@0+ (1,0) [0|0] "" TCM

BO_ 2030 VddmToVgmJ1979OBDPropDiagResFrame11: 8 VDDM
 SG_ VddmToVgmJ1979OBDPropDiagResNpdu11 : 7|64@0+ (1,0) [0|0] "" VGM

BO_ 1324 VgmPropNmPdu1: 8 VGM
 SG_ PNC22_VGM : 22|1@0+ (1,0) [0|0] "" VDDM
 SG_ PNC23_VGM : 23|1@0+ (1,0) [0|0] "" VDDM
 SG_ PNC25_VGM : 25|1@0+ (1,0) [0|0] "" VDDM
 SG_ PNC26_VGM : 26|1@0+ (1,0) [0|0] "" VDDM
 SG_ PNC27_VGM : 27|1@0+ (1,0) [0|0] "" VDDM
 SG_ PNC29_VGM : 29|1@0+ (1,0) [0|0] "" VDDM
 SG_ PNC30_VGM : 30|1@0+ (1,0) [0|0] "" VDDM
 SG_ PNC16_VGM : 16|1@0+ (1,0) [0|0] "" VDDM
 SG_ PNC17_VGM : 17|1@0+ (1,0) [0|0] "" VDDM
 SG_ PNC24_VGM : 24|1@0+ (1,0) [0|0] "" VDDM
 SG_ PNC20_VGM : 20|1@0+ (1,0) [0|0] "" VDDM
 SG_ PNC19_VGM : 19|1@0+ (1,0) [0|0] "" VDDM
 SG_ PNC18_VGM : 18|1@0+ (1,0) [0|0] "" VDDM
 SG_ PNC33_VGM : 33|1@0+ (1,0) [0|0] "" VDDM
 SG_ PNC34_VGM : 34|1@0+ (1,0) [0|0] "" VDDM
 SG_ PNC39_VGM : 39|1@0+ (1,0) [0|0] "" VDDM
 SG_ PNC37_VGM : 37|1@0+ (1,0) [0|0] "" VDDM
 SG_ NM_PNI_VGM : 14|1@0+ (1,0) [0|0] "" VDDM
 SG_ NM_AW_VGM : 12|1@0+ (1,0) [0|0] "" VDDM
 SG_ NM_CS_VGM : 11|1@0+ (1,0) [0|0] "" VDDM
 SG_ NM_RMR_VGM : 8|1@0+ (1,0) [0|0] "" VDDM
 SG_ NM_NodeID_VGM : 7|8@0+ (1,0) [0|0] "" VDDM

BO_ 2015 VgmToAllJ1979OBDPropCanReqFrame11: 8 VGM
 SG_ VgmToAllFuncJ1979OBDPropCanReqNpdu11 : 7|64@0+ (1,0) [0|0] "" BECM, ECM, IEM, IGM, ISGM, MVBM, MVEM, OBC, TCM, VDDM

BO_ 2018 VgmToBecmJ1979OBDPropCanReqFrame11: 8 VGM
 SG_ VgmToBecmJ1979OBDPropCanReqNpdu11 : 7|64@0+ (1,0) [0|0] "" BECM

BO_ 2021 VgmToCddJ1979OBDPropCanReqFrame11: 8 VGM
 SG_ VgmToCddJ1979OBDPropCanReqNpdu11 : 7|64@0+ (1,0) [0|0] "" Vector_XXX

BO_ 2016 VgmToEcmJ1979OBDPropCanReqFrame11: 8 VGM
 SG_ VgmToEcmJ1979OBDPropCanReqNpdu11 : 7|64@0+ (1,0) [0|0] "" ECM

BO_ 2019 VgmToIemJ1979OBDPropCanReqFrame11: 8 VGM
 SG_ VgmToIemJ1979OBDPropCanReqNpdu11 : 7|64@0+ (1,0) [0|0] "" IEM

BO_ 2020 VgmToIgmJ1979OBDPropCanReqFrame11: 8 VGM
 SG_ VgmToIgmJ1979OBDPropCanReqNpdu11 : 7|64@0+ (1,0) [0|0] "" IGM

BO_ 2020 VgmToIsgmJ1979OBDPropCanReqFrame11: 8 VGM
 SG_ VgmToIsgmJ1979OBDPropCanReqNpdu11 : 7|64@0+ (1,0) [0|0] "" ISGM

BO_ 2020 VgmToMgmJ1979OBDPropCanReqFrame11: 8 VGM
 SG_ VgmToMgmJ1979OBDPropCanReqNpdu11 : 7|64@0+ (1,0) [0|0] "" Vector_XXX

BO_ 2018 VgmToMvbmJ1979OBDPropCanReqFrame11: 8 VGM
 SG_ VgmToMvbmJ1979OBDPropCanReqNpdu11 : 7|64@0+ (1,0) [0|0] "" MVBM

BO_ 2019 VgmToMvemJ1979OBDPropCanReqFrame11: 8 VGM
 SG_ VgmToMvemJ1979OBDPropCanReqNpdu11 : 7|64@0+ (1,0) [0|0] "" MVEM

BO_ 2021 VgmToObcJ1979OBDPropCanReqFrame11: 8 VGM
 SG_ VgmToObcJ1979OBDPropCanReqNpdu11 : 7|64@0+ (1,0) [0|0] "" OBC

BO_ 2033 VgmToSrsISO26021PropDiagResFrame11: 8 VGM
 SG_ VgmToSrsISO26021PropCanReqNpdu11 : 7|64@0+ (1,0) [0|0] "" SRS

BO_ 2017 VgmToTcmJ1979OBDPropCanReqFrame11: 8 VGM
 SG_ VgmToTcmJ1979OBDPropCanReqNpdu11 : 7|64@0+ (1,0) [0|0] "" TCM

BO_ 2022 VgmToVddmJ1979OBDPropCanReqFrame11: 8 VGM
 SG_ VgmToVddmJ1979OBDPropCanReqNpdu11 : 7|64@0+ (1,0) [0|0] "" VDDM

CM_ SG_ 1458 MVCMdevelpsignalgrouprespFunctiondevpsignalgroup1 "develop signal group response";
CM_ SG_ 1458 MVCMdevelpsignalgrouprespFunctiondevpsignalgroup2 "develop signal group response";
CM_ SG_ 1458 MVCMdevelpsignalgrouprespFunctiondevpsignalgroup3 "develop signal group response";
CM_ SG_ 1458 MVCMdevelpsignalgrouprespFunctiondevpsignalgroup4 "develop signal group response";
CM_ SG_ 1458 MVCMdevelpsignalgrouprespFunctiondevpsignalgroup5 "develop signal group response";
CM_ SG_ 1458 MVCMdevelpsignalgrouprespFunctiondevpsignalgroup6 "develop signal group response";
CM_ SG_ 1458 MVCMdevelpsignalgrouprespFunctiondevpsignalgroup7 "develop signal group response";
CM_ SG_ 1458 MVCMdevelpsignalgrouprespFunctiondevpsignalgroup8 "develop signal group response";
CM_ SG_ 93 MvDcDcModSts "The mode the DcDc is currently in";
CM_ SG_ 93 MvIDcDcActHiSide "Actual current measured at the high voltage side";
CM_ SG_ 93 MvIDcDcAvlMaxLoSide "Maximum available current at the low voltage side.";
CM_ SG_ 93 MvUDcDcActHiSide "Actual voltage measured at the high voltage side.";
CM_ SG_ 108 MvIDcDcActLoSideChks "This signal is ASIL-B classified End to End Checksum.";
CM_ SG_ 108 MvIDcDcActLoSideCntr "This signal is ASIL-B classified End to End Counter";
CM_ SG_ 108 MvIDcDcActLoSideMvIDcDcActLoSide "Actual current measured at the low voltage side.";
CM_ SG_ 108 MVPrecStsDcDc "Precharge status";
CM_ SG_ 108 MvTDcDc "Actual temperature of the DcDc";
CM_ SG_ 108 MvUDcDcActLoSideChks "This signal is ASIL-B classified End to End Checksum.";
CM_ SG_ 108 MvUDcDcActLoSideCntr "This signal is ASIL-B classified End to End Counter";
CM_ SG_ 108 MvUDcDcActLoSideMvUDcDcActLoSide "Voltage measured by the converter at LV terminals";
CM_ SG_ 395 MvFltDcDcBoostModeFlt "Bit 9 Boost mode Fault";
CM_ SG_ 395 MvFltDcDcBuckModeFlt "Bit 8 Buck mode Fault";
CM_ SG_ 395 MvFltDcDcCANLoss "Bit 10 CAN loss";
CM_ SG_ 395 MvFltDcDcHwFlt "Bit 14 Hardware Fault";
CM_ SG_ 395 MvFltDcDcLVSideOpenLoad "Bit 12 LV side OpenLoad";
CM_ SG_ 395 MvFltDcDcLVSideOverCurrent "Bit 2 LV side Over Current";
CM_ SG_ 395 MvFltDcDcLVSideOverVoltage "Bit 0 LV side Over Voltage";
CM_ SG_ 395 MvFltDcDcLVSideUnderVoltage "Bit 1 LV side Under Voltage";
CM_ SG_ 395 MvFltDcDcMVSideOverCurrent "Bit 5 MV side Over Current";
CM_ SG_ 395 MvFltDcDcMVSideOverVoltage "Bit 3 MV Side Over Voltage";
CM_ SG_ 395 MvFltDcDcMVSideUnderVoltage "Bit 4 MV Side Under Voltage";
CM_ SG_ 395 MvFltDcDcPCBOverTemp "Bit 6 PCB Over Temperature";
CM_ SG_ 395 MvFltDcDcPreChargeFlt "Bit 7 PreCharge Fault";
CM_ SG_ 395 MvFltDcDcPwrGndLoss "Bit 13 Power GND Loss";
CM_ SG_ 395 MvFltDcDcSecBuckModeFault "Bit 5 Buck mode fault";
CM_ SG_ 395 MvFltDcDcSecHwFlt "Bit 9 Hw Flt";
CM_ SG_ 395 MvFltDcDcSecLVSideOpenLoad "Bit 7 LV side OpenLoad";
CM_ SG_ 395 MvFltDcDcSecLVSideOverCurrent "Bit 2 LV side Over Current";
CM_ SG_ 395 MvFltDcDcSecLVSideOverVoltage "Bit 0 LV side Over Voltage";
CM_ SG_ 395 MvFltDcDcSecLVSideUnderVoltage "Bit 1 LV side Under Voltage";
CM_ SG_ 395 MvFltDcDcSecMVSideOverCurrent "Bit 3 MV side Over Current";
CM_ SG_ 395 MvFltDcDcSecPCBOverTemperature "Bit 4 PCB Over Temperature";
CM_ SG_ 395 MvFltDcDcSecPowerGNDLoss "Bit 8 Power GND Loss";
CM_ SG_ 395 MvFltDcDcSecSensorFault "bit 10 Sensor fault";
CM_ SG_ 395 MvFltDcDcSecSupplyVoltageCmpFlt "Bit 6 Supply Voltage Cmp Flt";
CM_ SG_ 395 MvFltDcDcSensorFlt "Bit 15 Sensor fault";
CM_ SG_ 395 MvFltDcDcSupplyVoltageCmpFlt "Bit 11 Supply Voltage compare Fault";
CM_ SG_ 395 MvLimnIndcnDcDcChks "CheckSum";
CM_ SG_ 395 MvLimnIndcnDcDcCntr "Counter";
CM_ SG_ 395 MvLimnIndcnDcDcMvLimnIndcnDcDc "Faults in medium voltage DcDc

Bit 0  Power derating
Bit 1  Permanent failure
Bit 2  Secondary derating
Bit 3  Secondary fault
Bit 4  Reserved
Bit 5  Reserved
Bit 6  Reserved
Bit 7  Reserved
Bit 8  Reserved
Bit 9  Reserved
Bit 10  Reserved
Bit 11  Reserved
Bit 12  Reserved
Bit 13  Reserved
Bit 14  Reserved
Bit 15  Reserved";
CM_ SG_ 530 MvIDcDcActLoSideSecChks "CheckSum";
CM_ SG_ 530 MvIDcDcActLoSideSecCntr "Counter";
CM_ SG_ 530 MvIDcDcActLoSideSecMvIDcDcActLoSide "Secondary actual current measured at the low voltage side.";
CM_ SG_ 530 MvUDcDcActLoSideSecChks "CheckSum";
CM_ SG_ 530 MvUDcDcActLoSideSecCntr "Counter";
CM_ SG_ 530 MvUDcDcActLoSideSecMvUDcDcActLoSide "Secondary output voltage at LV side";
CM_ SG_ 97 MvDcDcModStsSec "The mode the secondary DcDc is currently in";
CM_ SG_ 97 MvlDcDcActHiSideSec "Actual voltage measured at the high voltage side from the Secondary DcDc.";
CM_ SG_ 97 MvlDcDcAvlMaxLoSideSec "Maximum available current at the low voltage side in the secondary DcDc output.";
CM_ SG_ 1154 MvTDcDcSec "Actual temperature of the DcDc Secondary.";
CM_ SG_ 1429 OBCdevelpsignalgrouprespFunctiondevpsignalgroup1 "develop signal group response";
CM_ SG_ 1429 OBCdevelpsignalgrouprespFunctiondevpsignalgroup2 "develop signal group response";
CM_ SG_ 1429 OBCdevelpsignalgrouprespFunctiondevpsignalgroup3 "develop signal group response";
CM_ SG_ 1429 OBCdevelpsignalgrouprespFunctiondevpsignalgroup4 "develop signal group response";
CM_ SG_ 1429 OBCdevelpsignalgrouprespFunctiondevpsignalgroup5 "develop signal group response";
CM_ SG_ 1429 OBCdevelpsignalgrouprespFunctiondevpsignalgroup6 "develop signal group response";
CM_ SG_ 1429 OBCdevelpsignalgrouprespFunctiondevpsignalgroup7 "develop signal group response";
CM_ SG_ 1429 OBCdevelpsignalgrouprespFunctiondevpsignalgroup8 "develop signal group response";
CM_ SG_ 1362 VFCVectorOBCBlockID "Block Identifier";
CM_ SG_ 1362 VFCVectorOBCVFCid0 "AdjustableDriveControls";
CM_ SG_ 1362 VFCVectorOBCVFCid1 "ParkingDrivingClimatization";
CM_ SG_ 1362 VFCVectorOBCVFCid10 "ExteriorLighting";
CM_ SG_ 1362 VFCVectorOBCVFCid11 "Reserved";
CM_ SG_ 1362 VFCVectorOBCVFCid12 "Alarm";
CM_ SG_ 1362 VFCVectorOBCVFCid13 "Reserved";
CM_ SG_ 1362 VFCVectorOBCVFCid14 "InteriorLighting";
CM_ SG_ 1362 VFCVectorOBCVFCid15 "InteriorLightingEntrance";
CM_ SG_ 1362 VFCVectorOBCVFCid16 "Locking";
CM_ SG_ 1362 VFCVectorOBCVFCid17 "RemoteKey";
CM_ SG_ 1362 VFCVectorOBCVFCid18 "PropulsionStart";
CM_ SG_ 1362 VFCVectorOBCVFCid19 "PassiveSafetyAndRestraints";
CM_ SG_ 1362 VFCVectorOBCVFCid2 "PostClimatisation";
CM_ SG_ 1362 VFCVectorOBCVFCid20 "Reserved";
CM_ SG_ 1362 VFCVectorOBCVFCid21 "PowerOperatedTailgate";
CM_ SG_ 1362 VFCVectorOBCVFCid22 "VehicleDriving";
CM_ SG_ 1362 VFCVectorOBCVFCid23 "Reserved";
CM_ SG_ 1362 VFCVectorOBCVFCid24 "UserProfileInput";
CM_ SG_ 1362 VFCVectorOBCVFCid25 "SeatComfortFunctions";
CM_ SG_ 1362 VFCVectorOBCVFCid26 "Brake";
CM_ SG_ 1362 VFCVectorOBCVFCid27 "InformationPoll";
CM_ SG_ 1362 VFCVectorOBCVFCid28 "HVEnergyStorage";
CM_ SG_ 1362 VFCVectorOBCVFCid29 "Reserved";
CM_ SG_ 1362 VFCVectorOBCVFCid3 "PowertrainParkingClimatization";
CM_ SG_ 1362 VFCVectorOBCVFCid30 "TelematicsConnectivity";
CM_ SG_ 1362 VFCVectorOBCVFCid31 "Reserved";
CM_ SG_ 1362 VFCVectorOBCVFCid32 "Entertainment";
CM_ SG_ 1362 VFCVectorOBCVFCid33 "Diagnostics";
CM_ SG_ 1362 VFCVectorOBCVFCid34 "AllECUs";
CM_ SG_ 1362 VFCVectorOBCVFCid35 "TrailerCaravanFunctions";
CM_ SG_ 1362 VFCVectorOBCVFCid36 "Immobilizer";
CM_ SG_ 1362 VFCVectorOBCVFCid37 "Windows";
CM_ SG_ 1362 VFCVectorOBCVFCid38 "Visibility";
CM_ SG_ 1362 VFCVectorOBCVFCid39 "WarningSounds";
CM_ SG_ 1362 VFCVectorOBCVFCid4 "Reserved";
CM_ SG_ 1362 VFCVectorOBCVFCid40 "Entrance";
CM_ SG_ 1362 VFCVectorOBCVFCid41 "InfotainmentPush";
CM_ SG_ 1362 VFCVectorOBCVFCid42 "ChargingHV";
CM_ SG_ 1362 VFCVectorOBCVFCid43 "BodyPreClimatisation";
CM_ SG_ 1362 VFCVectorOBCVFCid44 "Crash";
CM_ SG_ 1362 VFCVectorOBCVFCid45 "GlobalShortDuration";
CM_ SG_ 1362 VFCVectorOBCVFCid46 "Hazard";
CM_ SG_ 1362 VFCVectorOBCVFCid47 "Reserved";
CM_ SG_ 1362 VFCVectorOBCVFCid48 "DoorOpenWarning";
CM_ SG_ 1362 VFCVectorOBCVFCid49 "ChargingInit";
CM_ SG_ 1362 VFCVectorOBCVFCid5 "Reserved";
CM_ SG_ 1362 VFCVectorOBCVFCid50 "Reserved";
CM_ SG_ 1362 VFCVectorOBCVFCid51 "Reserved";
CM_ SG_ 1362 VFCVectorOBCVFCid52 "ThermalRunaway";
CM_ SG_ 1362 VFCVectorOBCVFCid53 "Reserved";
CM_ SG_ 1362 VFCVectorOBCVFCid54 "Reserved";
CM_ SG_ 1362 VFCVectorOBCVFCid55 "Reserved";
CM_ SG_ 1362 VFCVectorOBCVFCid56 "Reserved";
CM_ SG_ 1362 VFCVectorOBCVFCid57 "Reserved";
CM_ SG_ 1362 VFCVectorOBCVFCid58 "Reserved";
CM_ SG_ 1362 VFCVectorOBCVFCid59 "Reserved";
CM_ SG_ 1362 VFCVectorOBCVFCid6 "UserInputSettings";
CM_ SG_ 1362 VFCVectorOBCVFCid60 "Reserved";
CM_ SG_ 1362 VFCVectorOBCVFCid61 "Reserved";
CM_ SG_ 1362 VFCVectorOBCVFCid7 "Reserved";
CM_ SG_ 1362 VFCVectorOBCVFCid8 "VehicleAPI";
CM_ SG_ 1362 VFCVectorOBCVFCid9 "IPWakeup";
CM_ SG_ 1456 SRSdevelpsignalgroupTXFunctiondevpsignalgroup1 "SRS development signal";
CM_ SG_ 1456 SRSdevelpsignalgroupTXFunctiondevpsignalgroup2 "SRS development signal";
CM_ SG_ 1456 SRSdevelpsignalgroupTXFunctiondevpsignalgroup3 "SRS development signal";
CM_ SG_ 1456 SRSdevelpsignalgroupTXFunctiondevpsignalgroup4 "SRS development signal";
CM_ SG_ 1456 SRSdevelpsignalgroupTXFunctiondevpsignalgroup5 "SRS development signal";
CM_ SG_ 1456 SRSdevelpsignalgroupTXFunctiondevpsignalgroup6 "SRS development signal";
CM_ SG_ 1456 SRSdevelpsignalgroupTXFunctiondevpsignalgroup7 "SRS development signal";
CM_ SG_ 1456 SRSdevelpsignalgroupTXFunctiondevpsignalgroup8 "SRS development signal";
CM_ SG_ 53 CrashStsSafeChks "Checksum for E2E";
CM_ SG_ 53 CrashStsSafeCntr "Counter for E2E";
CM_ SG_ 53 CrashStsSafeSts "Information if a crash has been detected by SRS.";
CM_ SG_ 343 TrsmActrSnsrPosnChks "Transmission actuator (PRND) position feedback. Valid for Shift-By-Wire system. If no position can be determined undefined value will be taken. Transmission actuator sensor position Checksum";
CM_ SG_ 343 TrsmActrSnsrPosnCntr "Transmission actuator (PRND) position feedback. Valid for Shift-By-Wire system. If no position can be determined undefined value will be taken. Transmission actuator sensor position Counter";
CM_ SG_ 343 TrsmActrSnsrPosnTrsmActrSnsrPosn "Transmission actuator (PRND) position feedback. Valid for shift-By-Wire system. If no position can be determined undefined value will be taken. Transmission actuator sensor position";
CM_ SG_ 343 TrsmActrUnitSts "Signal is used to inform ECM of Transmissions Actuator fault status for vehicles equipped with the Shift-By-Wire koncept.";
CM_ SG_ 273 TrsmCluTqMaxDlyEstimn "Transmission clutch tourqe maxmum delay estimation. Maximum clutch tourqe estimation, delayed, sent by transmission supplier in Nm.";
CM_ SG_ 273 TrsmGearAct "Transmission Gear Actual. Actual gear engaged sent by transmission supplier.";
CM_ SG_ 273 TrsmNChks "Input shaft revolution speed of gearbox. Output shaft revolution speed of gearbox";
CM_ SG_ 273 TrsmNCntr "Input shaft revolution speed of gearbox. Output shaft revolution speed of gearbox";
CM_ SG_ 273 TrsmNInp "Input shaft revolution speed of gearbox. Output shaft revolution speed of gearbox";
CM_ SG_ 273 TrsmNInpOk "Input shaft revolution speed of gearbox. Output shaft revolution speed of gearbox";
CM_ SG_ 273 TrsmNOutp "Input shaft revolution speed of gearbox. Output shaft revolution speed of gearbox";
CM_ SG_ 273 TrsmNOutpOk "Input shaft revolution speed of gearbox. Output shaft revolution speed of gearbox";
CM_ SG_ 385 EngRunngReqByTrsm "Engine running request from transmission. Supplier request engine running to prevent stalling when transmisson is disengaged. 2 bit signal. 0 - Default, 1 - Inhibit Stop, 2 - Running Requested, 3 - Reserved.";
CM_ SG_ 385 TrsmGearRatTar "Transmission gear ratio target. Target gear ratio for fix lock-up and current gear.";
CM_ SG_ 385 TrsmGearTar " Transmission gear target. Target gear recieved by transmission supplier. 0 - neutral disengaged, 1-13 - gear 1-13, 14 - unknown, 15 - reverse.";
CM_ SG_ 385 TrsmLockUpStAct "Transmission Lock Up State Actual. Lock up state signal. Sent by transmission supplier.  0 - open 1 - slip, 2 - microslip,  3 - fixed.";
CM_ SG_ 385 TrsmNeutFailr "Transmission Neutral Failiure. Neutral not possible flag. 0 - Neutral possible, 1 - Neutral not possible. ";
CM_ SG_ 385 TrsmPLockUp "Transmission Pressure Lock Up. Transmission LockUp pressure from transmission supplier. Unit - gf per cm2";
CM_ SG_ 385 TrsmShiftInhb "Transmission Shift Inhibit. Block shifting request signal sent from transmission supplier. 0 - shift inhibit not active, 1 - Shift inhibit active.";
CM_ SG_ 385 TrsmVehSpd "Vehicle speed measured by transmission";
CM_ SG_ 389 TrsmActrPosnSafeTrsmActrPosn "Describes the transmission position (P, R, N, D). Can also take intermediate positions (PR, RN, ND). If error are detected on position sensors undefined is set. Transmission measured gear lever position";
CM_ SG_ 389 TrsmActrPosnSafeTrsmActrPosnChks "Describes the transmission position (P, R, N, D). Can also take intermediate positions (PR, RN, ND). If error are detected on position sensors undefined is set. Transmission measured gear lever position";
CM_ SG_ 389 TrsmActrPosnSafeTrsmActrPosnCntr "Describes the transmission position (P, R, N, D). Can also take intermediate positions (PR, RN, ND). If error are detected on position sensors undefined is set. Transmission measured gear lever position";
CM_ SG_ 389 TrsmGearRat "Transmission gear ratio. Ratio between rotational speed on ingoing shaft and outgoing shaft.";
CM_ SG_ 389 TrsmOilT "Transmission oil temperature";
CM_ SG_ 389 TrsmSelfLrngMod "Transmission Self Learning Mode.";
CM_ SG_ 389 TrsmSelfLrngModAtPwrDwn "Transmission Self learning Mode At Power Down.";
CM_ SG_ 339 TrsmToPrpsnNReqRecAuxTrsmNReqCtrl "Transmission To Propulsion eNgine speed Request Record. Unit: Rpm";
CM_ SG_ 339 TrsmToPrpsnNReqRecAuxTrsmNReqMax "Transmission To Propulsion eNgine speed Request Record. Unit: Rpm";
CM_ SG_ 339 TrsmToPrpsnNReqRecAuxTrsmNReqMin "Transmission To Propulsion eNgine speed Request Record. Unit: Rpm";
CM_ SG_ 98 ChrgHndlStrtEna "This data element is written by HV system to indicate a charge request to UsgModMgr.";
CM_ SG_ 98 IncSpdIdleElecReq "Request to increase idle speed for greater alternator output.";
CM_ SG_ 98 PtTqAtAxleFrntMaxReq "Maximum allowed powertrain applied torque on the front axle. Positive value indicates limitation of powertrain torque in the desired driving direction of the driver. The signal shall not be compensated for powertrain inertia.";
CM_ SG_ 98 PtTqAtAxleFrntMinReqChks "Minimum allowed powertrain applied torque on the front axle Checksum";
CM_ SG_ 98 PtTqAtAxleFrntMinReqCntr "Minimum allowed powertrain applied torque on the front axle Counter";
CM_ SG_ 98 PtTqAtAxleFrntMinReqPtTqAtAxleFrntMinReq "Minimum allowed powertrain applied torque on the front axle Minimum allowed powertrain applied torque on the front axle";
CM_ SG_ 98 RoadSgnInfoSts "Indicates the TSR function status.";
CM_ SG_ 98 WhlAFrntMax "Acceleration of the fastest wheel on the front axle.";
CM_ SG_ 134 WhlSpdCircumlFrntChks "Individual wheel speed from front wheel speed sensors. Checksum";
CM_ SG_ 134 WhlSpdCircumlFrntCntr "Individual wheel speed from front wheel speed sensors. Counter";
CM_ SG_ 134 WhlSpdCircumlFrntLe "Individual wheel speed from front wheel speed sensors. Wheel speed from front left wheel speed sensor using nominal value of wheel radius.";
CM_ SG_ 134 WhlSpdCircumlFrntLeQf "Individual wheel speed from front wheel speed sensors. Qf for wheel speed sensor";
CM_ SG_ 134 WhlSpdCircumlFrntRi "Individual wheel speed from front wheel speed sensors. Wheel speed from front right wheel speed sensor using nominal value of wheel radius";
CM_ SG_ 134 WhlSpdCircumlFrntRiQf "Individual wheel speed from front wheel speed sensors. Qf for wheel speed sensor";
CM_ SG_ 118 BrkPedlPsdBrkPedlNotPsdSafe "Set to 1 if brake pedal is not pressed, otherwise 0";
CM_ SG_ 118 BrkPedlPsdBrkPedlPsd "Set to 1 if brake pedal is pressed, otherwise 0";
CM_ SG_ 118 BrkPedlPsdChks "Checksum";
CM_ SG_ 118 BrkPedlPsdCntr "Counter";
CM_ SG_ 118 BrkPedlPsdQf "Quality factor";
CM_ SG_ 118 VehMtnStChks "Vehicle motion state information based on wheel speed sensors. Provides information about vehicle stand still and vehicle rolling direction. Checksum for vehicle motion state";
CM_ SG_ 118 VehMtnStCntr "Vehicle motion state information based on wheel speed sensors. Provides information about vehicle stand still and vehicle rolling direction. Counter for vehicle motion state";
CM_ SG_ 118 VehMtnStVehMtnSt "Vehicle motion state information based on wheel speed sensors. Provides information about vehicle stand still and vehicle rolling direction. Vehicle motion state";
CM_ SG_ 118 VehSpdLgtChks "Vehicle speed longitudinal based on wheel speed sensors and longitudinal acceleration.
end2endprotection=profile1A dataid=12345 Checksum for vehicle speed longitudinal";
CM_ SG_ 118 VehSpdLgtCntr "Vehicle speed longitudinal based on wheel speed sensors and longitudinal acceleration.
end2endprotection=profile1A dataid= 12345 Counter for vehicle speed longitudinal checksum calculation";
CM_ SG_ 118 VehSpdLgtQf "Vehicle speed longitudinal based on wheel speed sensors and longitudinal acceleration.
end2endprotection=profile1A dataid= 12345 Qf for vehicle speed longitudinal";
CM_ SG_ 118 VehSpdLgtVehSpdLgt "Vehicle speed longitudinal based on wheel speed sensors and longitudinal acceleration.
end2endprotection=profile1A dataid= 12345 Vehicle speed longitudinal";
CM_ SG_ 565 VehCfgPrmBlkIDBytePosn1 "signal block counter.";
CM_ SG_ 565 VehCfgPrmCCPBytePosn2 " (BlockID-1)*7 + 1. ";
CM_ SG_ 565 VehCfgPrmCCPBytePosn3 " (BlockID-1)*7 + 2. ";
CM_ SG_ 565 VehCfgPrmCCPBytePosn4 " (BlockID-1)*7 + 3. ";
CM_ SG_ 565 VehCfgPrmCCPBytePosn5 " (BlockID-1)*7 + 4. ";
CM_ SG_ 565 VehCfgPrmCCPBytePosn6 " (BlockID-1)*7 + 5. ";
CM_ SG_ 565 VehCfgPrmCCPBytePosn7 " (BlockID-1)*7 + 6. ";
CM_ SG_ 565 VehCfgPrmCCPBytePosn8 " (BlockID-1)*7 + 7. ";
CM_ SG_ 113 AxleSlipRelAct "Wheel slip difference between front and rear axle. Slip difference = front slip - rear slip (independent of vehicle direction which needs to be considered by subscriber). Compensated for variation of tire radius
";
CM_ SG_ 113 WhlSpdCircumlReChks "Individual wheel speed from rear wheel speed sensors. Checksum";
CM_ SG_ 113 WhlSpdCircumlReCntr "Individual wheel speed from rear wheel speed sensors. Counter";
CM_ SG_ 113 WhlSpdCircumlReLe "Individual wheel speed from rear wheel speed sensors. Wheel speed from rear left wheel speed sensor using nominal value of wheel radius.";
CM_ SG_ 113 WhlSpdCircumlReLeQf "Individual wheel speed from rear wheel speed sensors. Qf for wheel speed sensor";
CM_ SG_ 113 WhlSpdCircumlReRi "Individual wheel speed from rear wheel speed sensors. Wheel speed from rear right wheel speed sensor using nominal value of wheel radius.";
CM_ SG_ 113 WhlSpdCircumlReRiQf "Individual wheel speed from rear wheel speed sensors. Qf for wheel speed sensor";
CM_ SG_ 65 BrkTqAtWhlsReq "Contains driver requested brake torque and driver support system requested brake torque. The signal is always positive and acts in opposite vehicle motion direction.";
CM_ SG_ 65 PtTqAtAxleReMaxReq "Maximum allowed powertrain applied torque on the rear axle. Positive value indicates limitation of powertrain torque in the desired driving direction of the driver. The signal shall not be compensated for powertrain inertia.";
CM_ SG_ 65 PtTqAtAxleReMinReqChks "Minimum allowed powertrain applied torque on the rear axle. Checksum";
CM_ SG_ 65 PtTqAtAxleReMinReqCntr "Minimum allowed powertrain applied torque on the rear axle. Counter";
CM_ SG_ 65 PtTqAtAxleReMinReqPtTqAtAxleReMinReq "Minimum allowed powertrain applied torque on the rear axle. 
";
CM_ SG_ 129 ADataRawSafeALat "IMU acceleration data Lateral acceleration";
CM_ SG_ 129 ADataRawSafeALat1Qf "IMU acceleration data Quality factor for Lateral acceleration signal";
CM_ SG_ 129 ADataRawSafeALgt "IMU acceleration data Longitudinal acceleration";
CM_ SG_ 129 ADataRawSafeALgt1Qf "IMU acceleration data Quality factor for Longitudinal acceleration";
CM_ SG_ 129 ADataRawSafeAVert "IMU acceleration data Vertical acceleration";
CM_ SG_ 129 ADataRawSafeAVertQf "IMU acceleration data Quality factor for Vertical acceleration";
CM_ SG_ 129 ADataRawSafeChks "IMU acceleration data Check sum";
CM_ SG_ 129 ADataRawSafeCntr "IMU acceleration data Counter";
CM_ SG_ 357 BrkFricTqAtWhlActBrkFricTqAtWhlFrntLeAct "Actual service brake torque for each wheel. Brake torque acting on the front left wheel. Based on nominal brake parameters (e.g. constant pads friction) and (estimated) brake pressures (clamp forces). Not included: parking brake torque or regenerative brake torque.";
CM_ SG_ 357 BrkFricTqAtWhlActBrkFricTqAtWhlFrntRiAct "Actual service brake torque for each wheel. Brake torque acting on the front right wheel. Based on nominal brake parameters (e.g. constant pads friction) and (estimated) brake pressures (clamp forces). Not included: parking brake torque or regenerative brake torque.";
CM_ SG_ 357 BrkFricTqAtWhlActBrkFricTqAtWhlReLeAct "Actual service brake torque for each wheel. Brake torque acting on the rear left wheel. Based on nominal brake parameters (e.g. constant pads friction) and (estimated) brake pressures (clamp forces). Not included: parking brake torque or regenerative brake torque.";
CM_ SG_ 357 BrkFricTqAtWhlActBrkFricTqAtWhlReRiAct "Actual service brake torque for each wheel. Brake torque acting on the rear right wheel. Based on nominal brake parameters (e.g. constant pads friction) and (estimated) brake pressures (clamp forces). Not included: parking brake torque or regenerative brake torque.";
CM_ SG_ 357 EngTracCtrlActvFrntMax "Engine traction control intervention is active on front axle.";
CM_ SG_ 369 BrkFricTqTotAtWhlsActBrkFricTqTotAtWhlsAct "Total actual friction brake toque at all four wheels.";
CM_ SG_ 369 BrkFricTqTotAtWhlsActChks "Total actual friction brake toque at all four wheels. Checksum";
CM_ SG_ 369 BrkFricTqTotAtWhlsActCntr "Total actual friction brake toque at all four wheels. Counter";
CM_ SG_ 369 LockgCenStsLockSt "Signal LockgCenSts provides central locking status to other subsystems.
Signal is a record with three items
- LockSt (Lock State)
- TrigSrc (Trig Source)
- UpdEve (Will be set to TRUE during one second at each new central locking or unlocking event)";
CM_ SG_ 369 LockgCenStsTrigSrc "Signal LockgCenSts provides central locking status to other subsystems.
Signal is a record with three items
- LockSt (Lock State)
- TrigSrc (Trig Source)
- UpdEve (Will be set to TRUE during one second at each new central locking or unlocking event)";
CM_ SG_ 369 LockgCenStsUpdEve "Signal LockgCenSts provides central locking status to other subsystems.
Signal is a record with three items
- LockSt (Lock State)
- TrigSrc (Trig Source)
- UpdEve (Will be set to TRUE during one second at each new central locking or unlocking event)";
CM_ SG_ 369 SpdRotlForWhlsAtAxleRe "Average angular velocity of rear wheels.";
CM_ SG_ 369 YawStabyCtrlActv "Indicates InCtrl if AYC or ARP is requesting wheel torque for control of vehicle yaw movement.";
CM_ SG_ 353 AgDataRawSafeChks "IMU angular rate data. Check summa";
CM_ SG_ 353 AgDataRawSafeCntr "IMU angular rate data. Counter";
CM_ SG_ 353 AgDataRawSafeRollRate "IMU angular rate data. Roll Rate";
CM_ SG_ 353 AgDataRawSafeRollRateQf "IMU angular rate data. Quality factor for Roll Rate";
CM_ SG_ 353 AgDataRawSafeYawRate "IMU angular rate data. Yaw Rate";
CM_ SG_ 353 AgDataRawSafeYawRateQf "IMU angular rate data. Quality Factor for Yaw Rate";
CM_ SG_ 561 CluPedl "System signal indicating if the clutch pedal is pressed or not On or Off";
CM_ SG_ 561 LimForDecelChks "Vehicle deceleration limit monitor information Checksum";
CM_ SG_ 561 LimForDecelCntr "Vehicle deceleration limit monitor information Counter";
CM_ SG_ 561 LimForDecelNotExcd "Vehicle deceleration limit monitor information Information will be set to YES as long as the vehicle deceleration limit is not exceeded";
CM_ SG_ 561 SpprtBattOkForCrkCold "Support battery OK for crank";
CM_ SG_ 561 TelmPreClimaPrio "Energy prioritization mode for pre-climatization";
CM_ SG_ 561 TiDrvgCycOff "Timer since engine was deactivated";
CM_ SG_ 561 TrlrPrsnt "TrlrNotPrsnt - Trailer caravan is not connected to the vehicle.
TrlrPrsnt - Trailer caravan is connected to the vehicle.";
CM_ SG_ 561 WhlCircum "Wheel circumference in millimeters. Invalid value indicated by 4095.";
CM_ SG_ 609 ImobEngMgrReq3ImobEngDataMgrReq0 "Command from CEM to IGM with desired immo status and 7 bytes of response Byte 0";
CM_ SG_ 609 ImobEngMgrReq3ImobEngDataMgrReq1 "Command from CEM to IGM with desired immo status and 7 bytes of response Byte 1";
CM_ SG_ 609 ImobEngMgrReq3ImobEngDataMgrReq2 "Command from CEM to IGM with desired immo status and 7 bytes of response Byte 2";
CM_ SG_ 609 ImobEngMgrReq3ImobEngDataMgrReq3 "Command from CEM to IGM with desired immo status and 7 bytes of response Byte 3";
CM_ SG_ 609 ImobEngMgrReq3ImobEngDataMgrReq4 "Command from CEM to IGM with desired immo status and 7 bytes of response Byte 4";
CM_ SG_ 609 ImobEngMgrReq3ImobEngDataMgrReq5 "Command from CEM to IGM with desired immo status and 7 bytes of response Byte 5";
CM_ SG_ 609 ImobEngMgrReq3ImobEngDataMgrReq6 "Command from CEM to IGM with desired immo status and 7 bytes of response Byte 6";
CM_ SG_ 609 ImobEngMgrReq3ImobEngMgrCmdTar1 "Command from CEM to IGM with desired immo status and 7 bytes of response Command from CEM";
CM_ SG_ 609 MaintainBattTCtrl "on/off signal to control the function of maintaining the battery temperature ";
CM_ SG_ 597 ImobEngMgrReq2ImobEngDataMgrReq0 "Command from CEM to IEM with desired immo status and 7 bytes of response Byte 0";
CM_ SG_ 597 ImobEngMgrReq2ImobEngDataMgrReq1 "Command from CEM to IEM with desired immo status and 7 bytes of response Byte 1";
CM_ SG_ 597 ImobEngMgrReq2ImobEngDataMgrReq2 "Command from CEM to IEM with desired immo status and 7 bytes of response Byte 2";
CM_ SG_ 597 ImobEngMgrReq2ImobEngDataMgrReq3 "Command from CEM to IEM with desired immo status and 7 bytes of response Byte 3";
CM_ SG_ 597 ImobEngMgrReq2ImobEngDataMgrReq4 "Command from CEM to IEM with desired immo status and 7 bytes of response Byte 4";
CM_ SG_ 597 ImobEngMgrReq2ImobEngDataMgrReq5 "Command from CEM to IEM with desired immo status and 7 bytes of response Byte 5";
CM_ SG_ 597 ImobEngMgrReq2ImobEngDataMgrReq6 "Command from CEM to IEM with desired immo status and 7 bytes of response Byte 6";
CM_ SG_ 597 ImobEngMgrReq2ImobEngMgrCmdTar1 "Command from CEM to IEM with desired immo status and 7 bytes of response Command from CEM";
CM_ SG_ 641 CarTiGlb "Presents a tiime value that shall be used by all ECUs to time-stamp diagnsotic trouble codes (DTC) according to the requirements for Global DTC snapshot data.";
CM_ SG_ 641 ChrgModReq "Charge mode request";
CM_ SG_ 641 CmptmtAirTEstimdExtdComptmtT "Estimated compartment temperature with quality flag Estimated compartment Temperature";
CM_ SG_ 641 CmptmtAirTEstimdExtdQlyFlg "Estimated compartment temperature with quality flag Quality flag ";
CM_ SG_ 641 URateUpRampMax "Maximum ramp rate for alternator

Range: 0 - 10
Resolution: 0.5
Unit: V/s";
CM_ SG_ 86 ChrgnUReq "Requested Charging voltage from Voltage Control";
CM_ SG_ 86 IntrBriSts "Rheostat setting. Set by user through rheostat wheel situated on MyCar Module.";
CM_ SG_ 86 TwliBriSts "Day or night status signal. Lux value (not this signal) sent from SUS to CEM and CEM sets day or night signal.";
CM_ SG_ 86 VehModMngtGlbSafe1CarModSts1 "CarMode Status";
CM_ SG_ 86 VehModMngtGlbSafe1CarModSubtypWdCarModSubtyp "CarMode substate status";
CM_ SG_ 86 VehModMngtGlbSafe1Chks "Checksum";
CM_ SG_ 86 VehModMngtGlbSafe1Cntr "Counter";
CM_ SG_ 86 VehModMngtGlbSafe1EgyLvlElecMai "Main energy level in the vehicle.";
CM_ SG_ 86 VehModMngtGlbSafe1EgyLvlElecSubtyp "Substate of the energy level in the vehicle.";
CM_ SG_ 86 VehModMngtGlbSafe1FltEgyCnsWdSts "High quiescent current detected by CEM via BMS.";
CM_ SG_ 86 VehModMngtGlbSafe1PwrLvlElecMai "Main Power level in the vehicle.";
CM_ SG_ 86 VehModMngtGlbSafe1PwrLvlElecSubtyp "Substate of the power level in the vehicle.";
CM_ SG_ 86 VehModMngtGlbSafe1UsgModSts "UsageMode Status";
CM_ SG_ 645 AbsClrRdyReq "Readiness Clear Signal";
CM_ SG_ 645 AmbTRawAmbTVal "Unfiltered ambient temp raw data in deg C. Ambient temp value";
CM_ SG_ 645 AmbTRawQly "Unfiltered ambient temp raw data in deg C. Quality Factor of the ambient temp";
CM_ SG_ 645 BkpOfDstTrvld "total traveled distance.";
CM_ SG_ 645 VehBattUSysU "Vehicle System Voltage At 12V side";
CM_ SG_ 645 VehBattUSysUQf "Present vehicle voltage measured by CEM with QF";
CM_ SG_ 344 DrvrBrkTqAtWhlsReqdChks "Checksum for E2E";
CM_ SG_ 344 DrvrBrkTqAtWhlsReqdCntr "Counter for E2E";
CM_ SG_ 344 DrvrBrkTqAtWhlsReqdDrvrBrkTqAtWhlsReqd "Driver requested brake torque at wheels.";
CM_ SG_ 344 DrvrBrkTqAtWhlsReqdQf "Quality factor of driver requested brake torque at wheels ";
CM_ SG_ 344 EpbStsChks "Electrical Park Brake system status information Status for the rear wheel park actuator";
CM_ SG_ 344 EpbStsCntr "Electrical Park Brake system status information Counter for EPB status";
CM_ SG_ 344 EpbStsEpbSts "Electrical Park Brake system status information Status for the rear wheel park actuator";
CM_ SG_ 566 VehCfgPrmExtBlkIDBytePosn1 "CarConfigExtended BlockID";
CM_ SG_ 566 VehCfgPrmExtCCPBytePosn2 "CarConfigExtended BytePos2";
CM_ SG_ 566 VehCfgPrmExtCCPBytePosn3 "CarConfigExtended BytePos3";
CM_ SG_ 566 VehCfgPrmExtCCPBytePosn4 "CarConfigExtended BytePos4";
CM_ SG_ 566 VehCfgPrmExtCCPBytePosn5 "CarConfigExtended BytePos5";
CM_ SG_ 566 VehCfgPrmExtCCPBytePosn6 "CarConfigExtended BytePos6";
CM_ SG_ 566 VehCfgPrmExtCCPBytePosn7 "CarConfigExtended BytePos7";
CM_ SG_ 566 VehCfgPrmExtCCPBytePosn8 "CarConfigExtended BytePos8";
CM_ SG_ 667 ChrgLidFrntSts "ChrgLidFrntSts - Front Charge Lid status
Ukwn - Unknown status
Opend - Opened
Clsd - Closed";
CM_ SG_ 667 DrvModReq "drive mode";
CM_ SG_ 667 MaxAcInpCurrentSet "set the input current";
CM_ SG_ 667 OnBdDiagLostCom "The signal is a heartbeat between the node connected to the OBD connector and the OBD Master.";
CM_ SG_ 667 SoundExtActvSts "Sound external active status";
CM_ SG_ 49 AccrOvrdnAllwdForAutDrvChks "checksum";
CM_ SG_ 49 AccrOvrdnAllwdForAutDrvCntr "counter";
CM_ SG_ 49 AccrOvrdnAllwdForAutDrvYesNo1 "allwd driver to override ";
CM_ SG_ 49 ChrgLidRearSts "ChrgLidRearSts - Rear Charge Lid status
Ukwn - Unknown status
Opend - Opened
Clsd - Closed";
CM_ SG_ 49 SteerWhlSnsrChks "Checksum for steering wheel sensor data.";
CM_ SG_ 49 SteerWhlSnsrCntr "Counter value for steering wheel sensor data.";
CM_ SG_ 49 SteerWhlSnsrQf "Qf for steering wheel sensor information";
CM_ SG_ 49 SteerWhlSnsrSteerWhlAg "Actual steering wheel angle from the actual centre position of the steering wheel. ";
CM_ SG_ 49 SteerWhlSnsrSteerWhlAgSpd "Actual steering wheel angle from the actual centre position of the steering wheel. Steering angle speed with steering wheel rotation direction.  ";
CM_ SG_ 324 BattSftySigChks "Check Sum";
CM_ SG_ 324 BattSftySigCntr "Counter";
CM_ SG_ 324 BattSftySigSysSaftyBattI "System Safety Battery Current";
CM_ SG_ 324 BattSftySigSysSaftyBattU "System Safety Battery Voltage";
CM_ SG_ 1051 BattThermMngtInFuturePwrAtTime "power allowed  at time in the future";
CM_ SG_ 1051 BattThermMngtInFutureSequenceNo "sequence number";
CM_ SG_ 1051 BattThermMngtInFutureTempAtTime "target temperature at time in the future";
CM_ SG_ 1051 BattThermMngtInFutureThermModAtTime "target thermalmode at time in the future";
CM_ SG_ 1051 BattThermMngtInFutureTime "time in the future";
CM_ SG_ 1051 BattThermMngtInFutureVersionNo "version number";
CM_ SG_ 1042 ClimateCtrlInFuturePwrAtTime "power allowed  at time in the future";
CM_ SG_ 1042 ClimateCtrlInFutureSequenceNo "sequence number";
CM_ SG_ 1042 ClimateCtrlInFutureTempAtTime "climate control temperature at time in the future";
CM_ SG_ 1042 ClimateCtrlInFutureThermModAtTime "target thermalmode at time in the future";
CM_ SG_ 1042 ClimateCtrlInFutureTime "time in the future";
CM_ SG_ 1042 ClimateCtrlInFutureVersionNo "version number";
CM_ SG_ 1375 VFCInfoEna "VFCVectorFrame enable and disable setting";
CM_ SG_ 1518 VDDMPropCANInternalDevRespMesgFunctiondevpsignalgroup1 "develop signal group response";
CM_ SG_ 1518 VDDMPropCANInternalDevRespMesgFunctiondevpsignalgroup2 "develop signal group response";
CM_ SG_ 1518 VDDMPropCANInternalDevRespMesgFunctiondevpsignalgroup3 "develop signal group response";
CM_ SG_ 1518 VDDMPropCANInternalDevRespMesgFunctiondevpsignalgroup4 "develop signal group response";
CM_ SG_ 1518 VDDMPropCANInternalDevRespMesgFunctiondevpsignalgroup5 "develop signal group response";
CM_ SG_ 1518 VDDMPropCANInternalDevRespMesgFunctiondevpsignalgroup6 "develop signal group response";
CM_ SG_ 1518 VDDMPropCANInternalDevRespMesgFunctiondevpsignalgroup7 "develop signal group response";
CM_ SG_ 1518 VDDMPropCANInternalDevRespMesgFunctiondevpsignalgroup8 "develop signal group response";
BA_DEF_ BO_ "GenMsgSendType" ENUM "cyclic", "spontaneous", "not-used", "not-used", "not-used", "cyclicAndSpontaneous", "not-used", "cyclicIfActive", "NoMsgSendType"; // [us]
BA_DEF_ BO_ "GenMsgCycleTime" INT 0 65536; // [ms]
BA_DEF_ BO_ "GenMsgStartDelayTime" INT 0 65536; // [ms]
BA_DEF_ BO_ "GenMsgDelayTime" INT 0 65536; // [ms]
BA_DEF_ SG_ "GenSigSendType" ENUM "Cyclic","OnWrite","OnWriteWithRepetition","OnChange","OnChangeWithRepetition","IfActive","IfActiveWithRepetition","NoSigSendType";
BA_DEF_ SG_ "GenSigStartValue" HEX 0 80000000;
BA_DEF_ BO_ "GenMsgILSupport" ENUM "No","Yes";
BA_DEF_ BO_ "NmAsrMessage" ENUM "No","Yes";
BA_DEF_ SG_ "GenSigFuncType" ENUM "NoFunction","n/a","n/a","n/a","n/a","n/a","n/a","n/a","n/a","n/a","n/a","n/a","n/a","n/a","n/a","CHK","CNTR","n/a","n/a","n/a","CNTR_AR_01","CRC_AR_01_BOTH","CRC_AR_01_ALT","CRC_AR_01_LOW","CRC_AR_01_NIBBLE","CNTR_AR_04","CRC_AR_04A","CNTR_AR_05","CRC_AR_05";
BA_DEF_ SG_ "GenSigDataID" STRING;

BA_DEF_DEF_ "GenSigStartValue" 0;
BA_DEF_DEF_ "GenSigSendType" "NoSigSendType";
BA_DEF_DEF_ "GenMsgCycleTime" 0;
BA_DEF_DEF_ "GenMsgDelayTime" 0;
BA_DEF_DEF_ "GenMsgStartDelayTime" 0;
BA_DEF_DEF_ "GenMsgSendType" "NoMsgSendType";
BA_DEF_DEF_ "GenMsgILSupport" "Yes";
BA_DEF_DEF_ "NmAsrMessage" "No";
BA_DEF_DEF_ "GenSigFuncType" "NoFunction";
BA_DEF_DEF_ "GenSigDataID" "";
// Frame: MvcmPropDevFr01
BA_ "GenMsgSendType" BO_ 1458 1;
BA_ "GenMsgDelayTime" BO_ 1458 100.000;
BA_ "GenSigSendType" SG_ 1458 MVCMdevelpsignalgrouprespFunctiondevpsignalgroup1 1;
BA_ "GenSigSendType" SG_ 1458 MVCMdevelpsignalgrouprespFunctiondevpsignalgroup2 1;
BA_ "GenSigSendType" SG_ 1458 MVCMdevelpsignalgrouprespFunctiondevpsignalgroup3 1;
BA_ "GenSigSendType" SG_ 1458 MVCMdevelpsignalgrouprespFunctiondevpsignalgroup4 1;
BA_ "GenSigSendType" SG_ 1458 MVCMdevelpsignalgrouprespFunctiondevpsignalgroup5 1;
BA_ "GenSigSendType" SG_ 1458 MVCMdevelpsignalgrouprespFunctiondevpsignalgroup6 1;
BA_ "GenSigSendType" SG_ 1458 MVCMdevelpsignalgrouprespFunctiondevpsignalgroup7 1;
BA_ "GenSigSendType" SG_ 1458 MVCMdevelpsignalgrouprespFunctiondevpsignalgroup8 1;
// Frame: MvcmPropFr03
BA_ "GenMsgSendType" BO_ 93 0;
BA_ "GenMsgCycleTime" BO_ 93 20.000;
BA_ "GenSigStartValue" SG_ 93 MvDcDcModSts 2;
BA_ "GenSigSendType" SG_ 93 MvDcDcModSts 0;
BA_ "GenSigStartValue" SG_ 93 MvIDcDcActHiSide 2048;
BA_ "GenSigSendType" SG_ 93 MvIDcDcActHiSide 0;
BA_ "GenSigSendType" SG_ 93 MvIDcDcAvlMaxLoSide 0;
BA_ "GenSigSendType" SG_ 93 MvUDcDcActHiSide 0;
// Frame: MvcmPropFr04
BA_ "GenMsgSendType" BO_ 108 0;
BA_ "GenMsgCycleTime" BO_ 108 50.000;
BA_ "GenSigSendType" SG_ 108 MvIDcDcActLoSideChks 0;
BA_ "GenSigFuncType" SG_ 108 MvIDcDcActLoSideChks 15;
BA_ "GenSigDataID" SG_ 108 MvIDcDcActLoSideChks "0x04";
BA_ "GenSigSendType" SG_ 108 MvIDcDcActLoSideCntr 0;
BA_ "GenSigFuncType" SG_ 108 MvIDcDcActLoSideCntr 16;
BA_ "GenSigStartValue" SG_ 108 MvIDcDcActLoSideMvIDcDcActLoSide 4096;
BA_ "GenSigSendType" SG_ 108 MvIDcDcActLoSideMvIDcDcActLoSide 0;
BA_ "GenSigStartValue" SG_ 108 MVPrecStsDcDc 2;
BA_ "GenSigSendType" SG_ 108 MVPrecStsDcDc 0;
BA_ "GenSigStartValue" SG_ 108 MvTDcDc 50;
BA_ "GenSigSendType" SG_ 108 MvTDcDc 0;
BA_ "GenSigSendType" SG_ 108 MvUDcDcActLoSideChks 0;
BA_ "GenSigFuncType" SG_ 108 MvUDcDcActLoSideChks 15;
BA_ "GenSigDataID" SG_ 108 MvUDcDcActLoSideChks "0x07";
BA_ "GenSigSendType" SG_ 108 MvUDcDcActLoSideCntr 0;
BA_ "GenSigFuncType" SG_ 108 MvUDcDcActLoSideCntr 16;
BA_ "GenSigStartValue" SG_ 108 MvUDcDcActLoSideMvUDcDcActLoSide 140;
BA_ "GenSigSendType" SG_ 108 MvUDcDcActLoSideMvUDcDcActLoSide 0;
// Frame: MvcmPropFr05
BA_ "GenMsgSendType" BO_ 395 0;
BA_ "GenMsgCycleTime" BO_ 395 50.000;
BA_ "GenSigSendType" SG_ 395 MvFltDcDcBoostModeFlt 0;
BA_ "GenSigSendType" SG_ 395 MvFltDcDcBuckModeFlt 0;
BA_ "GenSigSendType" SG_ 395 MvFltDcDcCANLoss 0;
BA_ "GenSigSendType" SG_ 395 MvFltDcDcHwFlt 0;
BA_ "GenSigSendType" SG_ 395 MvFltDcDcLVSideOpenLoad 0;
BA_ "GenSigSendType" SG_ 395 MvFltDcDcLVSideOverCurrent 0;
BA_ "GenSigSendType" SG_ 395 MvFltDcDcLVSideOverVoltage 0;
BA_ "GenSigSendType" SG_ 395 MvFltDcDcLVSideUnderVoltage 0;
BA_ "GenSigSendType" SG_ 395 MvFltDcDcMVSideOverCurrent 0;
BA_ "GenSigSendType" SG_ 395 MvFltDcDcMVSideOverVoltage 0;
BA_ "GenSigSendType" SG_ 395 MvFltDcDcMVSideUnderVoltage 0;
BA_ "GenSigSendType" SG_ 395 MvFltDcDcPCBOverTemp 0;
BA_ "GenSigSendType" SG_ 395 MvFltDcDcPreChargeFlt 0;
BA_ "GenSigSendType" SG_ 395 MvFltDcDcPwrGndLoss 0;
BA_ "GenSigSendType" SG_ 395 MvFltDcDcSecBuckModeFault 0;
BA_ "GenSigSendType" SG_ 395 MvFltDcDcSecHwFlt 0;
BA_ "GenSigSendType" SG_ 395 MvFltDcDcSecLVSideOpenLoad 0;
BA_ "GenSigSendType" SG_ 395 MvFltDcDcSecLVSideOverCurrent 0;
BA_ "GenSigSendType" SG_ 395 MvFltDcDcSecLVSideOverVoltage 0;
BA_ "GenSigSendType" SG_ 395 MvFltDcDcSecLVSideUnderVoltage 0;
BA_ "GenSigSendType" SG_ 395 MvFltDcDcSecMVSideOverCurrent 0;
BA_ "GenSigSendType" SG_ 395 MvFltDcDcSecPCBOverTemperature 0;
BA_ "GenSigSendType" SG_ 395 MvFltDcDcSecPowerGNDLoss 0;
BA_ "GenSigSendType" SG_ 395 MvFltDcDcSecSensorFault 0;
BA_ "GenSigSendType" SG_ 395 MvFltDcDcSecSupplyVoltageCmpFlt 0;
BA_ "GenSigSendType" SG_ 395 MvFltDcDcSensorFlt 0;
BA_ "GenSigSendType" SG_ 395 MvFltDcDcSupplyVoltageCmpFlt 0;
BA_ "GenSigSendType" SG_ 395 MvLimnIndcnDcDcChks 0;
BA_ "GenSigFuncType" SG_ 395 MvLimnIndcnDcDcChks 15;
BA_ "GenSigDataID" SG_ 395 MvLimnIndcnDcDcChks "0x413";
BA_ "GenSigSendType" SG_ 395 MvLimnIndcnDcDcCntr 0;
BA_ "GenSigFuncType" SG_ 395 MvLimnIndcnDcDcCntr 16;
BA_ "GenSigSendType" SG_ 395 MvLimnIndcnDcDcMvLimnIndcnDcDc 0;
// Frame: MvcmPropFr06
BA_ "GenMsgSendType" BO_ 530 0;
BA_ "GenMsgCycleTime" BO_ 530 50.000;
BA_ "GenSigSendType" SG_ 530 MvIDcDcActLoSideSecChks 0;
BA_ "GenSigFuncType" SG_ 530 MvIDcDcActLoSideSecChks 15;
BA_ "GenSigDataID" SG_ 530 MvIDcDcActLoSideSecChks "0x41C";
BA_ "GenSigSendType" SG_ 530 MvIDcDcActLoSideSecCntr 0;
BA_ "GenSigFuncType" SG_ 530 MvIDcDcActLoSideSecCntr 16;
BA_ "GenSigStartValue" SG_ 530 MvIDcDcActLoSideSecMvIDcDcActLoSide 4096;
BA_ "GenSigSendType" SG_ 530 MvIDcDcActLoSideSecMvIDcDcActLoSide 0;
BA_ "GenSigSendType" SG_ 530 MvUDcDcActLoSideSecChks 0;
BA_ "GenSigFuncType" SG_ 530 MvUDcDcActLoSideSecChks 15;
BA_ "GenSigDataID" SG_ 530 MvUDcDcActLoSideSecChks "0x41B";
BA_ "GenSigSendType" SG_ 530 MvUDcDcActLoSideSecCntr 0;
BA_ "GenSigFuncType" SG_ 530 MvUDcDcActLoSideSecCntr 16;
BA_ "GenSigSendType" SG_ 530 MvUDcDcActLoSideSecMvUDcDcActLoSide 0;
// Frame: MvcmPropFr07
BA_ "GenMsgSendType" BO_ 97 0;
BA_ "GenMsgCycleTime" BO_ 97 25.000;
BA_ "GenSigSendType" SG_ 97 MvDcDcModStsSec 0;
BA_ "GenSigSendType" SG_ 97 MvlDcDcActHiSideSec 0;
BA_ "GenSigSendType" SG_ 97 MvlDcDcAvlMaxLoSideSec 0;
// Frame: MvcmPropFr08
BA_ "GenMsgSendType" BO_ 1154 0;
BA_ "GenMsgCycleTime" BO_ 1154 800.000;
BA_ "GenSigStartValue" SG_ 1154 MvTDcDcSec 50;
BA_ "GenSigSendType" SG_ 1154 MvTDcDcSec 0;
// Frame: MvcmPropNMFr
BA_ "GenMsgSendType" BO_ 1315 1;
BA_ "GenMsgDelayTime" BO_ 1315 20.000;
BA_ "GenMsgILSupport" BO_ 1315 0;
BA_ "NmAsrMessage" BO_ 1315 1;
// Frame: MvcmToVddmPropDiagResFrame
BA_ "GenMsgSendType" BO_ 1597 1;
BA_ "GenMsgDelayTime" BO_ 1597 5.000;
// Frame: MvemToVddmPropDiagResFrame1
BA_ "GenMsgSendType" BO_ 1617 1;
BA_ "GenMsgDelayTime" BO_ 1617 5.000;
// Frame: ObcPropDevFr01
BA_ "GenMsgSendType" BO_ 1429 1;
BA_ "GenMsgDelayTime" BO_ 1429 100.000;
BA_ "GenSigSendType" SG_ 1429 OBCdevelpsignalgrouprespFunctiondevpsignalgroup1 1;
BA_ "GenSigSendType" SG_ 1429 OBCdevelpsignalgrouprespFunctiondevpsignalgroup2 1;
BA_ "GenSigSendType" SG_ 1429 OBCdevelpsignalgrouprespFunctiondevpsignalgroup3 1;
BA_ "GenSigSendType" SG_ 1429 OBCdevelpsignalgrouprespFunctiondevpsignalgroup4 1;
BA_ "GenSigSendType" SG_ 1429 OBCdevelpsignalgrouprespFunctiondevpsignalgroup5 1;
BA_ "GenSigSendType" SG_ 1429 OBCdevelpsignalgrouprespFunctiondevpsignalgroup6 1;
BA_ "GenSigSendType" SG_ 1429 OBCdevelpsignalgrouprespFunctiondevpsignalgroup7 1;
BA_ "GenSigSendType" SG_ 1429 OBCdevelpsignalgrouprespFunctiondevpsignalgroup8 1;
// Frame: ObcPropNMFr
BA_ "GenMsgSendType" BO_ 1304 1;
BA_ "GenMsgDelayTime" BO_ 1304 20.000;
BA_ "GenMsgILSupport" BO_ 1304 0;
BA_ "NmAsrMessage" BO_ 1304 1;
// Frame: ObcPropVFCVectorFr
BA_ "GenMsgSendType" BO_ 1362 1;
BA_ "GenMsgDelayTime" BO_ 1362 495.000;
BA_ "GenSigSendType" SG_ 1362 VFCVectorOBCBlockID 1;
BA_ "GenSigSendType" SG_ 1362 VFCVectorOBCVFCid0 1;
BA_ "GenSigSendType" SG_ 1362 VFCVectorOBCVFCid1 1;
BA_ "GenSigSendType" SG_ 1362 VFCVectorOBCVFCid10 1;
BA_ "GenSigSendType" SG_ 1362 VFCVectorOBCVFCid11 1;
BA_ "GenSigSendType" SG_ 1362 VFCVectorOBCVFCid12 1;
BA_ "GenSigSendType" SG_ 1362 VFCVectorOBCVFCid13 1;
BA_ "GenSigSendType" SG_ 1362 VFCVectorOBCVFCid14 1;
BA_ "GenSigSendType" SG_ 1362 VFCVectorOBCVFCid15 1;
BA_ "GenSigSendType" SG_ 1362 VFCVectorOBCVFCid16 1;
BA_ "GenSigSendType" SG_ 1362 VFCVectorOBCVFCid17 1;
BA_ "GenSigSendType" SG_ 1362 VFCVectorOBCVFCid18 1;
BA_ "GenSigSendType" SG_ 1362 VFCVectorOBCVFCid19 1;
BA_ "GenSigSendType" SG_ 1362 VFCVectorOBCVFCid2 1;
BA_ "GenSigSendType" SG_ 1362 VFCVectorOBCVFCid20 1;
BA_ "GenSigSendType" SG_ 1362 VFCVectorOBCVFCid21 1;
BA_ "GenSigSendType" SG_ 1362 VFCVectorOBCVFCid22 1;
BA_ "GenSigSendType" SG_ 1362 VFCVectorOBCVFCid23 1;
BA_ "GenSigSendType" SG_ 1362 VFCVectorOBCVFCid24 1;
BA_ "GenSigSendType" SG_ 1362 VFCVectorOBCVFCid25 1;
BA_ "GenSigSendType" SG_ 1362 VFCVectorOBCVFCid26 1;
BA_ "GenSigSendType" SG_ 1362 VFCVectorOBCVFCid27 1;
BA_ "GenSigSendType" SG_ 1362 VFCVectorOBCVFCid28 1;
BA_ "GenSigSendType" SG_ 1362 VFCVectorOBCVFCid29 1;
BA_ "GenSigSendType" SG_ 1362 VFCVectorOBCVFCid3 1;
BA_ "GenSigSendType" SG_ 1362 VFCVectorOBCVFCid30 1;
BA_ "GenSigSendType" SG_ 1362 VFCVectorOBCVFCid31 1;
BA_ "GenSigSendType" SG_ 1362 VFCVectorOBCVFCid32 1;
BA_ "GenSigSendType" SG_ 1362 VFCVectorOBCVFCid33 1;
BA_ "GenSigSendType" SG_ 1362 VFCVectorOBCVFCid34 1;
BA_ "GenSigSendType" SG_ 1362 VFCVectorOBCVFCid35 1;
BA_ "GenSigSendType" SG_ 1362 VFCVectorOBCVFCid36 1;
BA_ "GenSigSendType" SG_ 1362 VFCVectorOBCVFCid37 1;
BA_ "GenSigSendType" SG_ 1362 VFCVectorOBCVFCid38 1;
BA_ "GenSigSendType" SG_ 1362 VFCVectorOBCVFCid39 1;
BA_ "GenSigSendType" SG_ 1362 VFCVectorOBCVFCid4 1;
BA_ "GenSigSendType" SG_ 1362 VFCVectorOBCVFCid40 1;
BA_ "GenSigSendType" SG_ 1362 VFCVectorOBCVFCid41 1;
BA_ "GenSigSendType" SG_ 1362 VFCVectorOBCVFCid42 1;
BA_ "GenSigSendType" SG_ 1362 VFCVectorOBCVFCid43 1;
BA_ "GenSigSendType" SG_ 1362 VFCVectorOBCVFCid44 1;
BA_ "GenSigSendType" SG_ 1362 VFCVectorOBCVFCid45 1;
BA_ "GenSigSendType" SG_ 1362 VFCVectorOBCVFCid46 1;
BA_ "GenSigSendType" SG_ 1362 VFCVectorOBCVFCid47 1;
BA_ "GenSigSendType" SG_ 1362 VFCVectorOBCVFCid48 1;
BA_ "GenSigSendType" SG_ 1362 VFCVectorOBCVFCid49 1;
BA_ "GenSigSendType" SG_ 1362 VFCVectorOBCVFCid5 1;
BA_ "GenSigSendType" SG_ 1362 VFCVectorOBCVFCid50 1;
BA_ "GenSigSendType" SG_ 1362 VFCVectorOBCVFCid51 1;
BA_ "GenSigSendType" SG_ 1362 VFCVectorOBCVFCid52 1;
BA_ "GenSigSendType" SG_ 1362 VFCVectorOBCVFCid53 1;
BA_ "GenSigSendType" SG_ 1362 VFCVectorOBCVFCid54 1;
BA_ "GenSigSendType" SG_ 1362 VFCVectorOBCVFCid55 1;
BA_ "GenSigSendType" SG_ 1362 VFCVectorOBCVFCid56 1;
BA_ "GenSigSendType" SG_ 1362 VFCVectorOBCVFCid57 1;
BA_ "GenSigSendType" SG_ 1362 VFCVectorOBCVFCid58 1;
BA_ "GenSigSendType" SG_ 1362 VFCVectorOBCVFCid59 1;
BA_ "GenSigSendType" SG_ 1362 VFCVectorOBCVFCid6 1;
BA_ "GenSigSendType" SG_ 1362 VFCVectorOBCVFCid60 1;
BA_ "GenSigSendType" SG_ 1362 VFCVectorOBCVFCid61 1;
BA_ "GenSigSendType" SG_ 1362 VFCVectorOBCVFCid7 1;
BA_ "GenSigSendType" SG_ 1362 VFCVectorOBCVFCid8 1;
BA_ "GenSigSendType" SG_ 1362 VFCVectorOBCVFCid9 1;
// Frame: ObcToVddmPropDiagResFrame
BA_ "GenMsgSendType" BO_ 1588 1;
BA_ "GenMsgDelayTime" BO_ 1588 5.000;
// Frame: ObcToVgmJ1979OBDPropCanResFrame11
BA_ "GenMsgSendType" BO_ 2029 1;
BA_ "GenMsgDelayTime" BO_ 2029 5.000;
// Frame: SrsEtcPropDevFr01
BA_ "GenMsgSendType" BO_ 1456 1;
BA_ "GenMsgDelayTime" BO_ 1456 100.000;
BA_ "GenSigSendType" SG_ 1456 SRSdevelpsignalgroupTXFunctiondevpsignalgroup1 1;
BA_ "GenSigSendType" SG_ 1456 SRSdevelpsignalgroupTXFunctiondevpsignalgroup2 1;
BA_ "GenSigSendType" SG_ 1456 SRSdevelpsignalgroupTXFunctiondevpsignalgroup3 1;
BA_ "GenSigSendType" SG_ 1456 SRSdevelpsignalgroupTXFunctiondevpsignalgroup4 1;
BA_ "GenSigSendType" SG_ 1456 SRSdevelpsignalgroupTXFunctiondevpsignalgroup5 1;
BA_ "GenSigSendType" SG_ 1456 SRSdevelpsignalgroupTXFunctiondevpsignalgroup6 1;
BA_ "GenSigSendType" SG_ 1456 SRSdevelpsignalgroupTXFunctiondevpsignalgroup7 1;
BA_ "GenSigSendType" SG_ 1456 SRSdevelpsignalgroupTXFunctiondevpsignalgroup8 1;
// Frame: SrsPropFr02
BA_ "GenMsgSendType" BO_ 53 5;
BA_ "GenMsgCycleTime" BO_ 53 200.000;
BA_ "GenMsgDelayTime" BO_ 53 10.000;
BA_ "GenSigStartValue" SG_ 53 CrashStsSafeChks 255;
BA_ "GenSigSendType" SG_ 53 CrashStsSafeChks 1;
BA_ "GenSigFuncType" SG_ 53 CrashStsSafeChks 15;
BA_ "GenSigDataID" SG_ 53 CrashStsSafeChks "0x40B";
BA_ "GenSigSendType" SG_ 53 CrashStsSafeCntr 1;
BA_ "GenSigFuncType" SG_ 53 CrashStsSafeCntr 16;
BA_ "GenSigSendType" SG_ 53 CrashStsSafeSts 1;
// Frame: SrsPropNMFr
BA_ "GenMsgSendType" BO_ 1306 1;
BA_ "GenMsgDelayTime" BO_ 1306 20.000;
BA_ "GenMsgILSupport" BO_ 1306 0;
BA_ "NmAsrMessage" BO_ 1306 1;
// Frame: SrsToVgmISO26021PropDiagResFrame11
BA_ "GenMsgSendType" BO_ 2041 1;
BA_ "GenMsgDelayTime" BO_ 2041 5.000;
// Frame: TacmPropFr01
BA_ "GenMsgSendType" BO_ 343 0;
BA_ "GenMsgCycleTime" BO_ 343 25.000;
BA_ "GenSigSendType" SG_ 343 TrsmActrSnsrPosnChks 0;
BA_ "GenSigFuncType" SG_ 343 TrsmActrSnsrPosnChks 15;
BA_ "GenSigDataID" SG_ 343 TrsmActrSnsrPosnChks "0x64";
BA_ "GenSigSendType" SG_ 343 TrsmActrSnsrPosnCntr 0;
BA_ "GenSigFuncType" SG_ 343 TrsmActrSnsrPosnCntr 16;
BA_ "GenSigSendType" SG_ 343 TrsmActrSnsrPosnTrsmActrSnsrPosn 0;
BA_ "GenSigSendType" SG_ 343 TrsmActrUnitSts 0;
// Frame: TacmPropNMFr
BA_ "GenMsgSendType" BO_ 1323 1;
BA_ "GenMsgDelayTime" BO_ 1323 20.000;
BA_ "GenMsgILSupport" BO_ 1323 0;
BA_ "NmAsrMessage" BO_ 1323 1;
// Frame: TACMtoETCXcpFr01
BA_ "GenMsgSendType" BO_ 1425 1;
BA_ "GenMsgDelayTime" BO_ 1425 10.000;
// Frame: TACMtoETCXcpFr02
BA_ "GenMsgSendType" BO_ 1426 1;
BA_ "GenMsgDelayTime" BO_ 1426 10.000;
// Frame: TACMtoETCXcpFr03
BA_ "GenMsgSendType" BO_ 1427 1;
BA_ "GenMsgDelayTime" BO_ 1427 10.000;
// Frame: TacmToVddmPropDiagResFrame
BA_ "GenMsgSendType" BO_ 1596 1;
BA_ "GenMsgDelayTime" BO_ 1596 5.000;
// Frame: TcmPropFr02
BA_ "GenMsgSendType" BO_ 273 0;
BA_ "GenMsgCycleTime" BO_ 273 15.000;
BA_ "GenSigStartValue" SG_ 273 TrsmCluTqMaxDlyEstimn 1024;
BA_ "GenSigSendType" SG_ 273 TrsmCluTqMaxDlyEstimn 0;
BA_ "GenSigSendType" SG_ 273 TrsmGearAct 0;
BA_ "GenSigSendType" SG_ 273 TrsmNChks 0;
BA_ "GenSigFuncType" SG_ 273 TrsmNChks 15;
BA_ "GenSigDataID" SG_ 273 TrsmNChks "0x6D";
BA_ "GenSigSendType" SG_ 273 TrsmNCntr 0;
BA_ "GenSigFuncType" SG_ 273 TrsmNCntr 16;
BA_ "GenSigSendType" SG_ 273 TrsmNInp 0;
BA_ "GenSigSendType" SG_ 273 TrsmNInpOk 0;
BA_ "GenSigSendType" SG_ 273 TrsmNOutp 0;
BA_ "GenSigSendType" SG_ 273 TrsmNOutpOk 0;
// Frame: TcmPropFr04
BA_ "GenMsgSendType" BO_ 385 0;
BA_ "GenMsgCycleTime" BO_ 385 25.000;
BA_ "GenSigSendType" SG_ 385 EngRunngReqByTrsm 0;
BA_ "GenSigSendType" SG_ 385 TrsmGearRatTar 0;
BA_ "GenSigSendType" SG_ 385 TrsmGearTar 0;
BA_ "GenSigSendType" SG_ 385 TrsmLockUpStAct 0;
BA_ "GenSigSendType" SG_ 385 TrsmNeutFailr 0;
BA_ "GenSigSendType" SG_ 385 TrsmPLockUp 0;
BA_ "GenSigSendType" SG_ 385 TrsmShiftInhb 0;
BA_ "GenSigSendType" SG_ 385 TrsmVehSpd 0;
// Frame: TcmPropFr05
BA_ "GenMsgSendType" BO_ 389 0;
BA_ "GenMsgCycleTime" BO_ 389 25.000;
BA_ "GenSigStartValue" SG_ 389 TrsmActrPosnSafeTrsmActrPosn 7;
BA_ "GenSigSendType" SG_ 389 TrsmActrPosnSafeTrsmActrPosn 0;
BA_ "GenSigSendType" SG_ 389 TrsmActrPosnSafeTrsmActrPosnChks 0;
BA_ "GenSigFuncType" SG_ 389 TrsmActrPosnSafeTrsmActrPosnChks 15;
BA_ "GenSigDataID" SG_ 389 TrsmActrPosnSafeTrsmActrPosnChks "0x40";
BA_ "GenSigSendType" SG_ 389 TrsmActrPosnSafeTrsmActrPosnCntr 0;
BA_ "GenSigFuncType" SG_ 389 TrsmActrPosnSafeTrsmActrPosnCntr 16;
BA_ "GenSigSendType" SG_ 389 TrsmGearRat 0;
BA_ "GenSigStartValue" SG_ 389 TrsmOilT 60;
BA_ "GenSigSendType" SG_ 389 TrsmOilT 0;
BA_ "GenSigSendType" SG_ 389 TrsmSelfLrngMod 0;
BA_ "GenSigSendType" SG_ 389 TrsmSelfLrngModAtPwrDwn 0;
// Frame: TcmPropFr09
BA_ "GenMsgSendType" BO_ 339 0;
BA_ "GenMsgCycleTime" BO_ 339 20.000;
BA_ "GenSigSendType" SG_ 339 TrsmToPrpsnNReqRecAuxTrsmNReqCtrl 0;
BA_ "GenSigStartValue" SG_ 339 TrsmToPrpsnNReqRecAuxTrsmNReqMax 12767;
BA_ "GenSigSendType" SG_ 339 TrsmToPrpsnNReqRecAuxTrsmNReqMax 0;
BA_ "GenSigSendType" SG_ 339 TrsmToPrpsnNReqRecAuxTrsmNReqMin 0;
// Frame: TcmPropNMFr
BA_ "GenMsgSendType" BO_ 1303 1;
BA_ "GenMsgDelayTime" BO_ 1303 20.000;
BA_ "GenMsgILSupport" BO_ 1303 0;
BA_ "NmAsrMessage" BO_ 1303 1;
// Frame: TcmToVddmPropDiagResFrame
BA_ "GenMsgSendType" BO_ 1586 1;
BA_ "GenMsgDelayTime" BO_ 1586 5.000;
// Frame: TcmToVgmJ1979OBDPropCanResFrame11
BA_ "GenMsgSendType" BO_ 2025 1;
BA_ "GenMsgDelayTime" BO_ 2025 5.000;
// Frame: UudtBecmFr01
BA_ "GenMsgSendType" BO_ 1772 1;
BA_ "GenMsgDelayTime" BO_ 1772 5.000;
// Frame: UudtBecmFr02
BA_ "GenMsgSendType" BO_ 1773 1;
BA_ "GenMsgDelayTime" BO_ 1773 5.000;
// Frame: UudtBecmFr03
BA_ "GenMsgSendType" BO_ 1774 1;
BA_ "GenMsgDelayTime" BO_ 1774 5.000;
// Frame: UudtBecmFr04
BA_ "GenMsgSendType" BO_ 1775 1;
BA_ "GenMsgDelayTime" BO_ 1775 5.000;
// Frame: UudtBecmFr05
BA_ "GenMsgSendType" BO_ 1764 1;
BA_ "GenMsgDelayTime" BO_ 1764 5.000;
// Frame: UudtDemFr01
BA_ "GenMsgSendType" BO_ 1791 1;
BA_ "GenMsgDelayTime" BO_ 1791 5.000;
// Frame: UudtDemFr02
BA_ "GenMsgSendType" BO_ 1790 1;
BA_ "GenMsgDelayTime" BO_ 1790 5.000;
// Frame: UudtEcmFr01
BA_ "GenMsgSendType" BO_ 1789 1;
BA_ "GenMsgDelayTime" BO_ 1789 5.000;
// Frame: UudtEcmFr02
BA_ "GenMsgSendType" BO_ 1788 1;
BA_ "GenMsgDelayTime" BO_ 1788 5.000;
// Frame: UudtEcmFr03
BA_ "GenMsgSendType" BO_ 1787 1;
BA_ "GenMsgDelayTime" BO_ 1787 5.000;
// Frame: UudtEcmFr04
BA_ "GenMsgSendType" BO_ 1786 1;
BA_ "GenMsgDelayTime" BO_ 1786 5.000;
// Frame: UudtEgsmFr01
BA_ "GenMsgSendType" BO_ 1770 1;
BA_ "GenMsgDelayTime" BO_ 1770 5.000;
// Frame: UudtEgsmFr02
BA_ "GenMsgSendType" BO_ 1771 1;
BA_ "GenMsgDelayTime" BO_ 1771 5.000;
// Frame: UudtIemFr01
BA_ "GenMsgSendType" BO_ 1776 1;
BA_ "GenMsgDelayTime" BO_ 1776 5.000;
// Frame: UudtIemFr02
BA_ "GenMsgSendType" BO_ 1777 1;
BA_ "GenMsgDelayTime" BO_ 1777 5.000;
// Frame: UudtIemFr03
BA_ "GenMsgSendType" BO_ 1778 1;
BA_ "GenMsgDelayTime" BO_ 1778 5.000;
// Frame: UudtIgmFr01
BA_ "GenMsgSendType" BO_ 1779 1;
BA_ "GenMsgDelayTime" BO_ 1779 5.000;
// Frame: UudtIgmFr02
BA_ "GenMsgSendType" BO_ 1780 1;
BA_ "GenMsgDelayTime" BO_ 1780 5.000;
// Frame: UudtIgmFr03
BA_ "GenMsgSendType" BO_ 1781 1;
BA_ "GenMsgDelayTime" BO_ 1781 5.000;
// Frame: UudtTcmFr01
BA_ "GenMsgSendType" BO_ 1785 1;
BA_ "GenMsgDelayTime" BO_ 1785 5.000;
// Frame: UudtTcmFr02
BA_ "GenMsgSendType" BO_ 1784 1;
BA_ "GenMsgDelayTime" BO_ 1784 5.000;
// Frame: UudtTcmFr03
BA_ "GenMsgSendType" BO_ 1783 1;
BA_ "GenMsgDelayTime" BO_ 1783 5.000;
// Frame: UudtTcmFr04
BA_ "GenMsgSendType" BO_ 1782 1;
BA_ "GenMsgDelayTime" BO_ 1782 5.000;
// Frame: VddmPropFr02
BA_ "GenMsgSendType" BO_ 98 0;
BA_ "GenMsgCycleTime" BO_ 98 15.000;
BA_ "GenSigSendType" SG_ 98 ChrgHndlStrtEna 0;
BA_ "GenSigSendType" SG_ 98 IncSpdIdleElecReq 0;
BA_ "GenSigStartValue" SG_ 98 PtTqAtAxleFrntMaxReq 20000;
BA_ "GenSigSendType" SG_ 98 PtTqAtAxleFrntMaxReq 0;
BA_ "GenSigSendType" SG_ 98 PtTqAtAxleFrntMinReqChks 0;
BA_ "GenSigFuncType" SG_ 98 PtTqAtAxleFrntMinReqChks 15;
BA_ "GenSigDataID" SG_ 98 PtTqAtAxleFrntMinReqChks "0x51";
BA_ "GenSigSendType" SG_ 98 PtTqAtAxleFrntMinReqCntr 0;
BA_ "GenSigFuncType" SG_ 98 PtTqAtAxleFrntMinReqCntr 16;
BA_ "GenSigStartValue" SG_ 98 PtTqAtAxleFrntMinReqPtTqAtAxleFrntMinReq -20000;
BA_ "GenSigSendType" SG_ 98 PtTqAtAxleFrntMinReqPtTqAtAxleFrntMinReq 0;
BA_ "GenSigSendType" SG_ 98 RoadSgnInfoSts 0;
BA_ "GenSigSendType" SG_ 98 WhlAFrntMax 0;
// Frame: VddmPropFr03
BA_ "GenMsgSendType" BO_ 134 0;
BA_ "GenMsgCycleTime" BO_ 134 15.000;
BA_ "GenSigSendType" SG_ 134 WhlSpdCircumlFrntChks 0;
BA_ "GenSigFuncType" SG_ 134 WhlSpdCircumlFrntChks 15;
BA_ "GenSigDataID" SG_ 134 WhlSpdCircumlFrntChks "0x6F";
BA_ "GenSigSendType" SG_ 134 WhlSpdCircumlFrntCntr 0;
BA_ "GenSigFuncType" SG_ 134 WhlSpdCircumlFrntCntr 16;
BA_ "GenSigSendType" SG_ 134 WhlSpdCircumlFrntLe 0;
BA_ "GenSigStartValue" SG_ 134 WhlSpdCircumlFrntLeQf 1;
BA_ "GenSigSendType" SG_ 134 WhlSpdCircumlFrntLeQf 0;
BA_ "GenSigSendType" SG_ 134 WhlSpdCircumlFrntRi 0;
BA_ "GenSigStartValue" SG_ 134 WhlSpdCircumlFrntRiQf 1;
BA_ "GenSigSendType" SG_ 134 WhlSpdCircumlFrntRiQf 0;
// Frame: VddmPropFr05
BA_ "GenMsgSendType" BO_ 118 0;
BA_ "GenMsgCycleTime" BO_ 118 15.000;
BA_ "GenSigSendType" SG_ 118 BrkPedlPsdBrkPedlNotPsdSafe 0;
BA_ "GenSigSendType" SG_ 118 BrkPedlPsdBrkPedlPsd 0;
BA_ "GenSigSendType" SG_ 118 BrkPedlPsdChks 0;
BA_ "GenSigFuncType" SG_ 118 BrkPedlPsdChks 15;
BA_ "GenSigDataID" SG_ 118 BrkPedlPsdChks "0x38";
BA_ "GenSigSendType" SG_ 118 BrkPedlPsdCntr 0;
BA_ "GenSigFuncType" SG_ 118 BrkPedlPsdCntr 16;
BA_ "GenSigSendType" SG_ 118 BrkPedlPsdQf 0;
BA_ "GenSigSendType" SG_ 118 VehMtnStChks 0;
BA_ "GenSigFuncType" SG_ 118 VehMtnStChks 15;
BA_ "GenSigDataID" SG_ 118 VehMtnStChks "0x36";
BA_ "GenSigSendType" SG_ 118 VehMtnStCntr 0;
BA_ "GenSigFuncType" SG_ 118 VehMtnStCntr 16;
BA_ "GenSigSendType" SG_ 118 VehMtnStVehMtnSt 0;
BA_ "GenSigSendType" SG_ 118 VehSpdLgtChks 0;
BA_ "GenSigFuncType" SG_ 118 VehSpdLgtChks 15;
BA_ "GenSigDataID" SG_ 118 VehSpdLgtChks "0x37";
BA_ "GenSigSendType" SG_ 118 VehSpdLgtCntr 0;
BA_ "GenSigFuncType" SG_ 118 VehSpdLgtCntr 16;
BA_ "GenSigStartValue" SG_ 118 VehSpdLgtQf 1;
BA_ "GenSigSendType" SG_ 118 VehSpdLgtQf 0;
BA_ "GenSigSendType" SG_ 118 VehSpdLgtVehSpdLgt 0;
// Frame: VddmPropFr06
BA_ "GenMsgSendType" BO_ 565 1;
BA_ "GenMsgDelayTime" BO_ 565 120.000;
BA_ "GenSigSendType" SG_ 565 VehCfgPrmBlkIDBytePosn1 1;
BA_ "GenSigSendType" SG_ 565 VehCfgPrmCCPBytePosn2 1;
BA_ "GenSigSendType" SG_ 565 VehCfgPrmCCPBytePosn3 1;
BA_ "GenSigSendType" SG_ 565 VehCfgPrmCCPBytePosn4 1;
BA_ "GenSigSendType" SG_ 565 VehCfgPrmCCPBytePosn5 1;
BA_ "GenSigSendType" SG_ 565 VehCfgPrmCCPBytePosn6 1;
BA_ "GenSigSendType" SG_ 565 VehCfgPrmCCPBytePosn7 1;
BA_ "GenSigSendType" SG_ 565 VehCfgPrmCCPBytePosn8 1;
// Frame: VddmPropFr07
BA_ "GenMsgSendType" BO_ 113 0;
BA_ "GenMsgCycleTime" BO_ 113 15.000;
BA_ "GenSigSendType" SG_ 113 AxleSlipRelAct 0;
BA_ "GenSigSendType" SG_ 113 WhlSpdCircumlReChks 0;
BA_ "GenSigFuncType" SG_ 113 WhlSpdCircumlReChks 15;
BA_ "GenSigDataID" SG_ 113 WhlSpdCircumlReChks "0x7C";
BA_ "GenSigSendType" SG_ 113 WhlSpdCircumlReCntr 0;
BA_ "GenSigFuncType" SG_ 113 WhlSpdCircumlReCntr 16;
BA_ "GenSigSendType" SG_ 113 WhlSpdCircumlReLe 0;
BA_ "GenSigStartValue" SG_ 113 WhlSpdCircumlReLeQf 1;
BA_ "GenSigSendType" SG_ 113 WhlSpdCircumlReLeQf 0;
BA_ "GenSigSendType" SG_ 113 WhlSpdCircumlReRi 0;
BA_ "GenSigStartValue" SG_ 113 WhlSpdCircumlReRiQf 1;
BA_ "GenSigSendType" SG_ 113 WhlSpdCircumlReRiQf 0;
// Frame: VddmPropFr08
BA_ "GenMsgSendType" BO_ 65 0;
BA_ "GenMsgCycleTime" BO_ 65 10.000;
BA_ "GenSigSendType" SG_ 65 BrkTqAtWhlsReq 0;
BA_ "GenSigStartValue" SG_ 65 PtTqAtAxleReMaxReq 20000;
BA_ "GenSigSendType" SG_ 65 PtTqAtAxleReMaxReq 0;
BA_ "GenSigSendType" SG_ 65 PtTqAtAxleReMinReqChks 0;
BA_ "GenSigFuncType" SG_ 65 PtTqAtAxleReMinReqChks 15;
BA_ "GenSigDataID" SG_ 65 PtTqAtAxleReMinReqChks "0x57";
BA_ "GenSigSendType" SG_ 65 PtTqAtAxleReMinReqCntr 0;
BA_ "GenSigFuncType" SG_ 65 PtTqAtAxleReMinReqCntr 16;
BA_ "GenSigStartValue" SG_ 65 PtTqAtAxleReMinReqPtTqAtAxleReMinReq -20000;
BA_ "GenSigSendType" SG_ 65 PtTqAtAxleReMinReqPtTqAtAxleReMinReq 0;
// Frame: VddmPropFr09
BA_ "GenMsgSendType" BO_ 129 0;
BA_ "GenMsgCycleTime" BO_ 129 15.000;
BA_ "GenSigSendType" SG_ 129 ADataRawSafeALat 0;
BA_ "GenSigStartValue" SG_ 129 ADataRawSafeALat1Qf 1;
BA_ "GenSigSendType" SG_ 129 ADataRawSafeALat1Qf 0;
BA_ "GenSigSendType" SG_ 129 ADataRawSafeALgt 0;
BA_ "GenSigStartValue" SG_ 129 ADataRawSafeALgt1Qf 1;
BA_ "GenSigSendType" SG_ 129 ADataRawSafeALgt1Qf 0;
BA_ "GenSigStartValue" SG_ 129 ADataRawSafeAVert 1155.059;
BA_ "GenSigSendType" SG_ 129 ADataRawSafeAVert 0;
BA_ "GenSigStartValue" SG_ 129 ADataRawSafeAVertQf 1;
BA_ "GenSigSendType" SG_ 129 ADataRawSafeAVertQf 0;
BA_ "GenSigStartValue" SG_ 129 ADataRawSafeChks 255;
BA_ "GenSigSendType" SG_ 129 ADataRawSafeChks 0;
BA_ "GenSigFuncType" SG_ 129 ADataRawSafeChks 15;
BA_ "GenSigDataID" SG_ 129 ADataRawSafeChks "0x22";
BA_ "GenSigSendType" SG_ 129 ADataRawSafeCntr 0;
BA_ "GenSigFuncType" SG_ 129 ADataRawSafeCntr 16;
// Frame: VddmPropFr10
BA_ "GenMsgSendType" BO_ 357 0;
BA_ "GenMsgCycleTime" BO_ 357 25.000;
BA_ "GenSigSendType" SG_ 357 BrkFricTqAtWhlActBrkFricTqAtWhlFrntLeAct 0;
BA_ "GenSigSendType" SG_ 357 BrkFricTqAtWhlActBrkFricTqAtWhlFrntRiAct 0;
BA_ "GenSigSendType" SG_ 357 BrkFricTqAtWhlActBrkFricTqAtWhlReLeAct 0;
BA_ "GenSigSendType" SG_ 357 BrkFricTqAtWhlActBrkFricTqAtWhlReRiAct 0;
BA_ "GenSigSendType" SG_ 357 EngTracCtrlActvFrntMax 0;
// Frame: VddmPropFr11
BA_ "GenMsgSendType" BO_ 369 0;
BA_ "GenMsgCycleTime" BO_ 369 25.000;
BA_ "GenSigSendType" SG_ 369 BrkFricTqTotAtWhlsActBrkFricTqTotAtWhlsAct 0;
BA_ "GenSigSendType" SG_ 369 BrkFricTqTotAtWhlsActChks 0;
BA_ "GenSigFuncType" SG_ 369 BrkFricTqTotAtWhlsActChks 15;
BA_ "GenSigDataID" SG_ 369 BrkFricTqTotAtWhlsActChks "0x7B";
BA_ "GenSigSendType" SG_ 369 BrkFricTqTotAtWhlsActCntr 0;
BA_ "GenSigFuncType" SG_ 369 BrkFricTqTotAtWhlsActCntr 16;
BA_ "GenSigSendType" SG_ 369 LockgCenStsLockSt 0;
BA_ "GenSigSendType" SG_ 369 LockgCenStsTrigSrc 0;
BA_ "GenSigSendType" SG_ 369 LockgCenStsUpdEve 0;
BA_ "GenSigSendType" SG_ 369 SpdRotlForWhlsAtAxleRe 0;
BA_ "GenSigSendType" SG_ 369 YawStabyCtrlActv 0;
// Frame: VddmPropFr12
BA_ "GenMsgSendType" BO_ 353 0;
BA_ "GenMsgCycleTime" BO_ 353 25.000;
BA_ "GenSigStartValue" SG_ 353 AgDataRawSafeChks 255;
BA_ "GenSigSendType" SG_ 353 AgDataRawSafeChks 0;
BA_ "GenSigFuncType" SG_ 353 AgDataRawSafeChks 15;
BA_ "GenSigDataID" SG_ 353 AgDataRawSafeChks "0x23";
BA_ "GenSigSendType" SG_ 353 AgDataRawSafeCntr 0;
BA_ "GenSigFuncType" SG_ 353 AgDataRawSafeCntr 16;
BA_ "GenSigSendType" SG_ 353 AgDataRawSafeRollRate 0;
BA_ "GenSigStartValue" SG_ 353 AgDataRawSafeRollRateQf 1;
BA_ "GenSigSendType" SG_ 353 AgDataRawSafeRollRateQf 0;
BA_ "GenSigSendType" SG_ 353 AgDataRawSafeYawRate 0;
BA_ "GenSigStartValue" SG_ 353 AgDataRawSafeYawRateQf 1;
BA_ "GenSigSendType" SG_ 353 AgDataRawSafeYawRateQf 0;
// Frame: VddmPropFr14
BA_ "GenMsgSendType" BO_ 561 0;
BA_ "GenMsgCycleTime" BO_ 561 50.000;
BA_ "GenSigSendType" SG_ 561 CluPedl 0;
BA_ "GenSigSendType" SG_ 561 LimForDecelChks 0;
BA_ "GenSigFuncType" SG_ 561 LimForDecelChks 15;
BA_ "GenSigDataID" SG_ 561 LimForDecelChks "0x8B";
BA_ "GenSigSendType" SG_ 561 LimForDecelCntr 0;
BA_ "GenSigFuncType" SG_ 561 LimForDecelCntr 16;
BA_ "GenSigStartValue" SG_ 561 LimForDecelNotExcd 1;
BA_ "GenSigSendType" SG_ 561 LimForDecelNotExcd 0;
BA_ "GenSigSendType" SG_ 561 SpprtBattOkForCrkCold 0;
BA_ "GenSigStartValue" SG_ 561 TelmPreClimaPrio 2;
BA_ "GenSigSendType" SG_ 561 TelmPreClimaPrio 1;
BA_ "GenSigSendType" SG_ 561 TiDrvgCycOff 0;
BA_ "GenSigSendType" SG_ 561 TrlrPrsnt 0;
BA_ "GenSigSendType" SG_ 561 WhlCircum 0;
// Frame: VddmPropFr15
BA_ "GenMsgSendType" BO_ 609 0;
BA_ "GenMsgCycleTime" BO_ 609 80.000;
BA_ "GenSigSendType" SG_ 609 ImobEngMgrReq3ImobEngDataMgrReq0 0;
BA_ "GenSigSendType" SG_ 609 ImobEngMgrReq3ImobEngDataMgrReq1 0;
BA_ "GenSigSendType" SG_ 609 ImobEngMgrReq3ImobEngDataMgrReq2 0;
BA_ "GenSigSendType" SG_ 609 ImobEngMgrReq3ImobEngDataMgrReq3 0;
BA_ "GenSigSendType" SG_ 609 ImobEngMgrReq3ImobEngDataMgrReq4 0;
BA_ "GenSigSendType" SG_ 609 ImobEngMgrReq3ImobEngDataMgrReq5 0;
BA_ "GenSigSendType" SG_ 609 ImobEngMgrReq3ImobEngDataMgrReq6 0;
BA_ "GenSigSendType" SG_ 609 ImobEngMgrReq3ImobEngMgrCmdTar1 0;
BA_ "GenSigSendType" SG_ 609 MaintainBattTCtrl 1;
// Frame: VddmPropFr16
BA_ "GenMsgSendType" BO_ 597 0;
BA_ "GenMsgCycleTime" BO_ 597 80.000;
BA_ "GenSigSendType" SG_ 597 ImobEngMgrReq2ImobEngDataMgrReq0 0;
BA_ "GenSigSendType" SG_ 597 ImobEngMgrReq2ImobEngDataMgrReq1 0;
BA_ "GenSigSendType" SG_ 597 ImobEngMgrReq2ImobEngDataMgrReq2 0;
BA_ "GenSigSendType" SG_ 597 ImobEngMgrReq2ImobEngDataMgrReq3 0;
BA_ "GenSigSendType" SG_ 597 ImobEngMgrReq2ImobEngDataMgrReq4 0;
BA_ "GenSigSendType" SG_ 597 ImobEngMgrReq2ImobEngDataMgrReq5 0;
BA_ "GenSigSendType" SG_ 597 ImobEngMgrReq2ImobEngDataMgrReq6 0;
BA_ "GenSigSendType" SG_ 597 ImobEngMgrReq2ImobEngMgrCmdTar1 0;
// Frame: VddmPropFr17
BA_ "GenMsgSendType" BO_ 641 0;
BA_ "GenMsgCycleTime" BO_ 641 50.000;
BA_ "GenSigSendType" SG_ 641 CarTiGlb 0;
BA_ "GenSigSendType" SG_ 641 ChrgModReq 0;
BA_ "GenSigStartValue" SG_ 641 CmptmtAirTEstimdExtdComptmtT 600;
BA_ "GenSigSendType" SG_ 641 CmptmtAirTEstimdExtdComptmtT 0;
BA_ "GenSigSendType" SG_ 641 CmptmtAirTEstimdExtdQlyFlg 0;
BA_ "GenSigSendType" SG_ 641 URateUpRampMax 0;
// Frame: VddmPropFr18
BA_ "GenMsgSendType" BO_ 86 0;
BA_ "GenMsgCycleTime" BO_ 86 15.000;
BA_ "GenSigSendType" SG_ 86 ChrgnUReq 0;
BA_ "GenSigSendType" SG_ 86 IntrBriSts 0;
BA_ "GenSigSendType" SG_ 86 TwliBriSts 0;
BA_ "GenSigSendType" SG_ 86 VehModMngtGlbSafe1CarModSts1 0;
BA_ "GenSigSendType" SG_ 86 VehModMngtGlbSafe1CarModSubtypWdCarModSubtyp 0;
BA_ "GenSigSendType" SG_ 86 VehModMngtGlbSafe1Chks 0;
BA_ "GenSigFuncType" SG_ 86 VehModMngtGlbSafe1Chks 15;
BA_ "GenSigDataID" SG_ 86 VehModMngtGlbSafe1Chks "0x74";
BA_ "GenSigSendType" SG_ 86 VehModMngtGlbSafe1Cntr 0;
BA_ "GenSigFuncType" SG_ 86 VehModMngtGlbSafe1Cntr 16;
BA_ "GenSigSendType" SG_ 86 VehModMngtGlbSafe1EgyLvlElecMai 0;
BA_ "GenSigSendType" SG_ 86 VehModMngtGlbSafe1EgyLvlElecSubtyp 0;
BA_ "GenSigStartValue" SG_ 86 VehModMngtGlbSafe1FltEgyCnsWdSts 1;
BA_ "GenSigSendType" SG_ 86 VehModMngtGlbSafe1FltEgyCnsWdSts 0;
BA_ "GenSigSendType" SG_ 86 VehModMngtGlbSafe1PwrLvlElecMai 0;
BA_ "GenSigSendType" SG_ 86 VehModMngtGlbSafe1PwrLvlElecSubtyp 0;
BA_ "GenSigStartValue" SG_ 86 VehModMngtGlbSafe1UsgModSts 1;
BA_ "GenSigSendType" SG_ 86 VehModMngtGlbSafe1UsgModSts 0;
// Frame: VddmPropFr19
BA_ "GenMsgSendType" BO_ 645 0;
BA_ "GenMsgCycleTime" BO_ 645 200.000;
BA_ "GenSigSendType" SG_ 645 AbsClrRdyReq 0;
BA_ "GenSigStartValue" SG_ 645 AmbTRawAmbTVal 700;
BA_ "GenSigSendType" SG_ 645 AmbTRawAmbTVal 0;
BA_ "GenSigSendType" SG_ 645 AmbTRawQly 0;
BA_ "GenSigSendType" SG_ 645 BkpOfDstTrvld 0;
BA_ "GenSigSendType" SG_ 645 VehBattUSysU 0;
BA_ "GenSigStartValue" SG_ 645 VehBattUSysUQf 1;
BA_ "GenSigSendType" SG_ 645 VehBattUSysUQf 0;
// Frame: VddmPropFr21
BA_ "GenMsgSendType" BO_ 344 0;
BA_ "GenMsgCycleTime" BO_ 344 25.000;
BA_ "GenSigSendType" SG_ 344 DrvrBrkTqAtWhlsReqdChks 0;
BA_ "GenSigFuncType" SG_ 344 DrvrBrkTqAtWhlsReqdChks 15;
BA_ "GenSigDataID" SG_ 344 DrvrBrkTqAtWhlsReqdChks "0x7A";
BA_ "GenSigSendType" SG_ 344 DrvrBrkTqAtWhlsReqdCntr 0;
BA_ "GenSigFuncType" SG_ 344 DrvrBrkTqAtWhlsReqdCntr 16;
BA_ "GenSigSendType" SG_ 344 DrvrBrkTqAtWhlsReqdDrvrBrkTqAtWhlsReqd 0;
BA_ "GenSigStartValue" SG_ 344 DrvrBrkTqAtWhlsReqdQf 1;
BA_ "GenSigSendType" SG_ 344 DrvrBrkTqAtWhlsReqdQf 0;
BA_ "GenSigSendType" SG_ 344 EpbStsChks 0;
BA_ "GenSigFuncType" SG_ 344 EpbStsChks 15;
BA_ "GenSigDataID" SG_ 344 EpbStsChks "0x84";
BA_ "GenSigSendType" SG_ 344 EpbStsCntr 0;
BA_ "GenSigFuncType" SG_ 344 EpbStsCntr 16;
BA_ "GenSigSendType" SG_ 344 EpbStsEpbSts 0;
// Frame: VddmPropFr26
BA_ "GenMsgSendType" BO_ 566 1;
BA_ "GenMsgDelayTime" BO_ 566 120.000;
BA_ "GenSigSendType" SG_ 566 VehCfgPrmExtBlkIDBytePosn1 1;
BA_ "GenSigSendType" SG_ 566 VehCfgPrmExtCCPBytePosn2 1;
BA_ "GenSigSendType" SG_ 566 VehCfgPrmExtCCPBytePosn3 1;
BA_ "GenSigSendType" SG_ 566 VehCfgPrmExtCCPBytePosn4 1;
BA_ "GenSigSendType" SG_ 566 VehCfgPrmExtCCPBytePosn5 1;
BA_ "GenSigSendType" SG_ 566 VehCfgPrmExtCCPBytePosn6 1;
BA_ "GenSigSendType" SG_ 566 VehCfgPrmExtCCPBytePosn7 1;
BA_ "GenSigSendType" SG_ 566 VehCfgPrmExtCCPBytePosn8 1;
// Frame: VddmPropFr28
BA_ "GenMsgSendType" BO_ 667 0;
BA_ "GenMsgCycleTime" BO_ 667 200.000;
BA_ "GenSigSendType" SG_ 667 ChrgLidFrntSts 0;
BA_ "GenSigSendType" SG_ 667 DrvModReq 0;
BA_ "GenSigStartValue" SG_ 667 MaxAcInpCurrentSet 32;
BA_ "GenSigSendType" SG_ 667 MaxAcInpCurrentSet 1;
BA_ "GenSigSendType" SG_ 667 OnBdDiagLostCom 0;
BA_ "GenSigSendType" SG_ 667 SoundExtActvSts 1;
// Frame: VddmPropFr29
BA_ "GenMsgSendType" BO_ 49 0;
BA_ "GenMsgCycleTime" BO_ 49 15.000;
BA_ "GenSigSendType" SG_ 49 AccrOvrdnAllwdForAutDrvChks 0;
BA_ "GenSigSendType" SG_ 49 AccrOvrdnAllwdForAutDrvCntr 0;
BA_ "GenSigSendType" SG_ 49 AccrOvrdnAllwdForAutDrvYesNo1 0;
BA_ "GenSigSendType" SG_ 49 ChrgLidRearSts 0;
BA_ "GenSigSendType" SG_ 49 SteerWhlSnsrChks 0;
BA_ "GenSigFuncType" SG_ 49 SteerWhlSnsrChks 15;
BA_ "GenSigDataID" SG_ 49 SteerWhlSnsrChks "0x33";
BA_ "GenSigSendType" SG_ 49 SteerWhlSnsrCntr 0;
BA_ "GenSigFuncType" SG_ 49 SteerWhlSnsrCntr 16;
BA_ "GenSigStartValue" SG_ 49 SteerWhlSnsrQf 1;
BA_ "GenSigSendType" SG_ 49 SteerWhlSnsrQf 0;
BA_ "GenSigSendType" SG_ 49 SteerWhlSnsrSteerWhlAg 0;
BA_ "GenSigSendType" SG_ 49 SteerWhlSnsrSteerWhlAgSpd 0;
// Frame: VddmPropFr30
BA_ "GenMsgSendType" BO_ 324 0;
BA_ "GenMsgCycleTime" BO_ 324 50.000;
BA_ "GenSigSendType" SG_ 324 BattSftySigChks 0;
BA_ "GenSigFuncType" SG_ 324 BattSftySigChks 15;
BA_ "GenSigDataID" SG_ 324 BattSftySigChks "0x09";
BA_ "GenSigSendType" SG_ 324 BattSftySigCntr 0;
BA_ "GenSigFuncType" SG_ 324 BattSftySigCntr 16;
BA_ "GenSigStartValue" SG_ 324 BattSftySigSysSaftyBattI 32768;
BA_ "GenSigSendType" SG_ 324 BattSftySigSysSaftyBattI 0;
BA_ "GenSigSendType" SG_ 324 BattSftySigSysSaftyBattU 0;
// Frame: VddmPropFr31
BA_ "GenMsgSendType" BO_ 1051 0;
BA_ "GenMsgCycleTime" BO_ 1051 500.000;
BA_ "GenSigStartValue" SG_ 1051 BattThermMngtInFuturePwrAtTime 500;
BA_ "GenSigSendType" SG_ 1051 BattThermMngtInFuturePwrAtTime 0;
BA_ "GenSigSendType" SG_ 1051 BattThermMngtInFutureSequenceNo 0;
BA_ "GenSigStartValue" SG_ 1051 BattThermMngtInFutureTempAtTime 50;
BA_ "GenSigSendType" SG_ 1051 BattThermMngtInFutureTempAtTime 0;
BA_ "GenSigSendType" SG_ 1051 BattThermMngtInFutureThermModAtTime 0;
BA_ "GenSigSendType" SG_ 1051 BattThermMngtInFutureTime 0;
BA_ "GenSigSendType" SG_ 1051 BattThermMngtInFutureVersionNo 0;
// Frame: VddmPropFr32
BA_ "GenMsgSendType" BO_ 1042 0;
BA_ "GenMsgCycleTime" BO_ 1042 500.000;
BA_ "GenSigStartValue" SG_ 1042 ClimateCtrlInFuturePwrAtTime 500;
BA_ "GenSigSendType" SG_ 1042 ClimateCtrlInFuturePwrAtTime 0;
BA_ "GenSigSendType" SG_ 1042 ClimateCtrlInFutureSequenceNo 0;
BA_ "GenSigStartValue" SG_ 1042 ClimateCtrlInFutureTempAtTime 50;
BA_ "GenSigSendType" SG_ 1042 ClimateCtrlInFutureTempAtTime 0;
BA_ "GenSigSendType" SG_ 1042 ClimateCtrlInFutureThermModAtTime 0;
BA_ "GenSigSendType" SG_ 1042 ClimateCtrlInFutureTime 0;
BA_ "GenSigSendType" SG_ 1042 ClimateCtrlInFutureVersionNo 0;
// Frame: VddmPropNMfr
BA_ "GenMsgSendType" BO_ 1318 1;
BA_ "GenMsgDelayTime" BO_ 1318 20.000;
BA_ "GenMsgILSupport" BO_ 1318 0;
BA_ "NmAsrMessage" BO_ 1318 1;
// Frame: VddmPropVFCInfoEnaFr
BA_ "GenMsgSendType" BO_ 1375 1;
BA_ "GenMsgDelayTime" BO_ 1375 495.000;
BA_ "GenSigSendType" SG_ 1375 VFCInfoEna 1;
// Frame: VddmToAllFuncPropDiagReqFrame
BA_ "GenMsgSendType" BO_ 2047 1;
BA_ "GenMsgDelayTime" BO_ 2047 5.000;
// Frame: VddmToBecmPropDiagReqFrame
BA_ "GenMsgSendType" BO_ 1845 1;
BA_ "GenMsgDelayTime" BO_ 1845 5.000;
// Frame: VddmToCddPropDiagReqFrame1
BA_ "GenMsgSendType" BO_ 1872 1;
BA_ "GenMsgDelayTime" BO_ 1872 5.000;
// Frame: VddmToDemPropDiagReqFrame
BA_ "GenMsgSendType" BO_ 1848 1;
BA_ "GenMsgDelayTime" BO_ 1848 5.000;
// Frame: VddmToEcmPropDiagReqFrame
BA_ "GenMsgSendType" BO_ 1840 1;
BA_ "GenMsgDelayTime" BO_ 1840 5.000;
// Frame: VddmToEgsmPropDiagReqFrame
BA_ "GenMsgSendType" BO_ 1843 1;
BA_ "GenMsgDelayTime" BO_ 1843 5.000;
// Frame: VddmToEsmPropDiagReqFrame
BA_ "GenMsgSendType" BO_ 1850 1;
BA_ "GenMsgDelayTime" BO_ 1850 5.000;
// Frame: VddmToEtcDevelFr
BA_ "GenMsgSendType" BO_ 1518 1;
BA_ "GenMsgDelayTime" BO_ 1518 95.000;
BA_ "GenSigSendType" SG_ 1518 VDDMPropCANInternalDevRespMesgFunctiondevpsignalgroup1 1;
BA_ "GenSigSendType" SG_ 1518 VDDMPropCANInternalDevRespMesgFunctiondevpsignalgroup2 1;
BA_ "GenSigSendType" SG_ 1518 VDDMPropCANInternalDevRespMesgFunctiondevpsignalgroup3 1;
BA_ "GenSigSendType" SG_ 1518 VDDMPropCANInternalDevRespMesgFunctiondevpsignalgroup4 1;
BA_ "GenSigSendType" SG_ 1518 VDDMPropCANInternalDevRespMesgFunctiondevpsignalgroup5 1;
BA_ "GenSigSendType" SG_ 1518 VDDMPropCANInternalDevRespMesgFunctiondevpsignalgroup6 1;
BA_ "GenSigSendType" SG_ 1518 VDDMPropCANInternalDevRespMesgFunctiondevpsignalgroup7 1;
BA_ "GenSigSendType" SG_ 1518 VDDMPropCANInternalDevRespMesgFunctiondevpsignalgroup8 1;
// Frame: VddmToIemPropDiagReqFrame
BA_ "GenMsgSendType" BO_ 1847 1;
BA_ "GenMsgDelayTime" BO_ 1847 5.000;
// Frame: VddmToIgmPropDiagReqFrame
BA_ "GenMsgSendType" BO_ 1846 1;
BA_ "GenMsgDelayTime" BO_ 1846 5.000;
// Frame: VddmToIsgmPropDiagReqFrame
BA_ "GenMsgSendType" BO_ 1854 1;
BA_ "GenMsgDelayTime" BO_ 1854 5.000;
// Frame: VddmToMgmPropDiagReqFrame1
BA_ "GenMsgSendType" BO_ 1841 1;
BA_ "GenMsgDelayTime" BO_ 1841 5.000;
// Frame: VddmToMvbmPropDiagReqFrame
BA_ "GenMsgSendType" BO_ 1874 1;
BA_ "GenMsgDelayTime" BO_ 1874 5.000;
// Frame: VddmToMvcmPropDiagReqFrame
BA_ "GenMsgSendType" BO_ 1853 1;
BA_ "GenMsgDelayTime" BO_ 1853 5.000;
// Frame: VddmToMvemPropDiagReqFrame1
BA_ "GenMsgSendType" BO_ 1873 1;
BA_ "GenMsgDelayTime" BO_ 1873 5.000;
// Frame: VddmToObcPropDiagReqFrame
BA_ "GenMsgSendType" BO_ 1844 1;
BA_ "GenMsgDelayTime" BO_ 1844 5.000;
// Frame: VddmToTacmPropDiagReqFrame
BA_ "GenMsgSendType" BO_ 1852 1;
BA_ "GenMsgDelayTime" BO_ 1852 5.000;
// Frame: VddmToTcmPropDiagReqFrame
BA_ "GenMsgSendType" BO_ 1842 1;
BA_ "GenMsgDelayTime" BO_ 1842 5.000;
// Frame: VddmToVgmJ1979OBDPropDiagResFrame11
BA_ "GenMsgSendType" BO_ 2030 1;
BA_ "GenMsgDelayTime" BO_ 2030 5.000;
// Frame: VgmPropNmPdu1
BA_ "GenMsgSendType" BO_ 1324 1;
BA_ "GenMsgDelayTime" BO_ 1324 20.000;
BA_ "GenMsgILSupport" BO_ 1324 0;
BA_ "NmAsrMessage" BO_ 1324 1;
// Frame: VgmToAllJ1979OBDPropCanReqFrame11
BA_ "GenMsgSendType" BO_ 2015 1;
BA_ "GenMsgDelayTime" BO_ 2015 5.000;
// Frame: VgmToBecmJ1979OBDPropCanReqFrame11
BA_ "GenMsgSendType" BO_ 2018 1;
BA_ "GenMsgDelayTime" BO_ 2018 5.000;
// Frame: VgmToCddJ1979OBDPropCanReqFrame11
BA_ "GenMsgSendType" BO_ 2021 1;
BA_ "GenMsgDelayTime" BO_ 2021 5.000;
// Frame: VgmToEcmJ1979OBDPropCanReqFrame11
BA_ "GenMsgSendType" BO_ 2016 1;
BA_ "GenMsgDelayTime" BO_ 2016 5.000;
// Frame: VgmToIemJ1979OBDPropCanReqFrame11
BA_ "GenMsgSendType" BO_ 2019 1;
BA_ "GenMsgDelayTime" BO_ 2019 5.000;
// Frame: VgmToIgmJ1979OBDPropCanReqFrame11
BA_ "GenMsgSendType" BO_ 2020 1;
BA_ "GenMsgDelayTime" BO_ 2020 5.000;
// Frame: VgmToIsgmJ1979OBDPropCanReqFrame11
BA_ "GenMsgSendType" BO_ 2020 1;
BA_ "GenMsgDelayTime" BO_ 2020 5.000;
// Frame: VgmToMgmJ1979OBDPropCanReqFrame11
BA_ "GenMsgSendType" BO_ 2020 1;
BA_ "GenMsgDelayTime" BO_ 2020 5.000;
// Frame: VgmToMvbmJ1979OBDPropCanReqFrame11
BA_ "GenMsgSendType" BO_ 2018 1;
BA_ "GenMsgDelayTime" BO_ 2018 5.000;
// Frame: VgmToMvemJ1979OBDPropCanReqFrame11
BA_ "GenMsgSendType" BO_ 2019 1;
BA_ "GenMsgDelayTime" BO_ 2019 5.000;
// Frame: VgmToObcJ1979OBDPropCanReqFrame11
BA_ "GenMsgSendType" BO_ 2021 1;
BA_ "GenMsgDelayTime" BO_ 2021 5.000;
// Frame: VgmToSrsISO26021PropDiagResFrame11
BA_ "GenMsgSendType" BO_ 2033 1;
BA_ "GenMsgDelayTime" BO_ 2033 5.000;
// Frame: VgmToTcmJ1979OBDPropCanReqFrame11
BA_ "GenMsgSendType" BO_ 2017 1;
BA_ "GenMsgDelayTime" BO_ 2017 5.000;
// Frame: VgmToVddmJ1979OBDPropCanReqFrame11
BA_ "GenMsgSendType" BO_ 2022 1;
BA_ "GenMsgDelayTime" BO_ 2022 5.000;
VAL_ 93 MvDcDcModSts 2 "MvDcDcModSts1_Reserved" 3 "MvDcDcModSts1_StbBy" 4 "MvDcDcModSts1_Fwd" 5 "MvDcDcModSts1_Rvs" 10 "MvDcDcModSts1_IninInProgs" 11 "MvDcDcModSts1_ShutDwnInProgs" 13 "MvDcDcModSts1_AutoMod" 15 "MvDcDcModSts1_Invalid";
VAL_ 108 MVPrecStsDcDc 0 "DcDcPrecSts_Reserved" 1 "DcDcPrecSts_PrechargeInProcess" 2 "DcDcPrecSts_PrechargeNotInProcess" 3 "DcDcPrecSts_Invalid";
VAL_ 395 MvFltDcDcBoostModeFlt 0 "Flt_NoFault" 1 "Flt_Fault";
VAL_ 395 MvFltDcDcBuckModeFlt 0 "Flt_NoFault" 1 "Flt_Fault";
VAL_ 395 MvFltDcDcCANLoss 0 "Flt_NoFault" 1 "Flt_Fault";
VAL_ 395 MvFltDcDcHwFlt 0 "Flt_NoFault" 1 "Flt_Fault";
VAL_ 395 MvFltDcDcLVSideOpenLoad 0 "Flt_NoFault" 1 "Flt_Fault";
VAL_ 395 MvFltDcDcLVSideOverCurrent 0 "Flt_NoFault" 1 "Flt_Fault";
VAL_ 395 MvFltDcDcLVSideOverVoltage 0 "Flt_NoFault" 1 "Flt_Fault";
VAL_ 395 MvFltDcDcLVSideUnderVoltage 0 "Flt_NoFault" 1 "Flt_Fault";
VAL_ 395 MvFltDcDcMVSideOverCurrent 0 "Flt_NoFault" 1 "Flt_Fault";
VAL_ 395 MvFltDcDcMVSideOverVoltage 0 "Flt_NoFault" 1 "Flt_Fault";
VAL_ 395 MvFltDcDcMVSideUnderVoltage 0 "Flt_NoFault" 1 "Flt_Fault";
VAL_ 395 MvFltDcDcPCBOverTemp 0 "Flt_NoFault" 1 "Flt_Fault";
VAL_ 395 MvFltDcDcPreChargeFlt 0 "Flt_NoFault" 1 "Flt_Fault";
VAL_ 395 MvFltDcDcPwrGndLoss 0 "Flt_NoFault" 1 "Flt_Fault";
VAL_ 395 MvFltDcDcSecBuckModeFault 0 "Flt_NoFault" 1 "Flt_Fault";
VAL_ 395 MvFltDcDcSecHwFlt 0 "Flt_NoFault" 1 "Flt_Fault";
VAL_ 395 MvFltDcDcSecLVSideOpenLoad 0 "Flt_NoFault" 1 "Flt_Fault";
VAL_ 395 MvFltDcDcSecLVSideOverCurrent 0 "Flt_NoFault" 1 "Flt_Fault";
VAL_ 395 MvFltDcDcSecLVSideOverVoltage 0 "Flt_NoFault" 1 "Flt_Fault";
VAL_ 395 MvFltDcDcSecLVSideUnderVoltage 0 "Flt_NoFault" 1 "Flt_Fault";
VAL_ 395 MvFltDcDcSecMVSideOverCurrent 0 "Flt_NoFault" 1 "Flt_Fault";
VAL_ 395 MvFltDcDcSecPCBOverTemperature 0 "Flt_NoFault" 1 "Flt_Fault";
VAL_ 395 MvFltDcDcSecPowerGNDLoss 0 "Flt_NoFault" 1 "Flt_Fault";
VAL_ 395 MvFltDcDcSecSensorFault 0 "Flt_NoFault" 1 "Flt_Fault";
VAL_ 395 MvFltDcDcSecSupplyVoltageCmpFlt 0 "Flt_NoFault" 1 "Flt_Fault";
VAL_ 395 MvFltDcDcSensorFlt 0 "Flt_NoFault" 1 "Flt_Fault";
VAL_ 395 MvFltDcDcSupplyVoltageCmpFlt 0 "Flt_NoFault" 1 "Flt_Fault";
VAL_ 97 MvDcDcModStsSec 0 "MvDcDcModSts2_StdBy" 1 "MvDcDcModSts2_Fwd" 2 "MvDcDcModSts2_IninInProgs" 3 "MvDcDcModSts2_ShutDownInProgs" 4 "MvDcDcModSts2_Derating" 5 "MvDcDcModSts2_AutoMod" 6 "MvDcDcModSts2_Invalid";
VAL_ 1362 VFCVectorOBCVFCid0 0 "VFCOnOff_Off" 1 "VFCOnOff_On";
VAL_ 1362 VFCVectorOBCVFCid1 0 "VFCOnOff_Off" 1 "VFCOnOff_On";
VAL_ 1362 VFCVectorOBCVFCid10 0 "VFCOnOff_Off" 1 "VFCOnOff_On";
VAL_ 1362 VFCVectorOBCVFCid11 0 "VFCOnOff_Off" 1 "VFCOnOff_On";
VAL_ 1362 VFCVectorOBCVFCid12 0 "VFCOnOff_Off" 1 "VFCOnOff_On";
VAL_ 1362 VFCVectorOBCVFCid13 0 "VFCOnOff_Off" 1 "VFCOnOff_On";
VAL_ 1362 VFCVectorOBCVFCid14 0 "VFCOnOff_Off" 1 "VFCOnOff_On";
VAL_ 1362 VFCVectorOBCVFCid15 0 "VFCOnOff_Off" 1 "VFCOnOff_On";
VAL_ 1362 VFCVectorOBCVFCid16 0 "VFCOnOff_Off" 1 "VFCOnOff_On";
VAL_ 1362 VFCVectorOBCVFCid17 0 "VFCOnOff_Off" 1 "VFCOnOff_On";
VAL_ 1362 VFCVectorOBCVFCid18 0 "VFCOnOff_Off" 1 "VFCOnOff_On";
VAL_ 1362 VFCVectorOBCVFCid19 0 "VFCOnOff_Off" 1 "VFCOnOff_On";
VAL_ 1362 VFCVectorOBCVFCid2 0 "VFCOnOff_Off" 1 "VFCOnOff_On";
VAL_ 1362 VFCVectorOBCVFCid20 0 "VFCOnOff_Off" 1 "VFCOnOff_On";
VAL_ 1362 VFCVectorOBCVFCid21 0 "VFCOnOff_Off" 1 "VFCOnOff_On";
VAL_ 1362 VFCVectorOBCVFCid22 0 "VFCOnOff_Off" 1 "VFCOnOff_On";
VAL_ 1362 VFCVectorOBCVFCid23 0 "VFCOnOff_Off" 1 "VFCOnOff_On";
VAL_ 1362 VFCVectorOBCVFCid24 0 "VFCOnOff_Off" 1 "VFCOnOff_On";
VAL_ 1362 VFCVectorOBCVFCid25 0 "VFCOnOff_Off" 1 "VFCOnOff_On";
VAL_ 1362 VFCVectorOBCVFCid26 0 "VFCOnOff_Off" 1 "VFCOnOff_On";
VAL_ 1362 VFCVectorOBCVFCid27 0 "VFCOnOff_Off" 1 "VFCOnOff_On";
VAL_ 1362 VFCVectorOBCVFCid28 0 "VFCOnOff_Off" 1 "VFCOnOff_On";
VAL_ 1362 VFCVectorOBCVFCid29 0 "VFCOnOff_Off" 1 "VFCOnOff_On";
VAL_ 1362 VFCVectorOBCVFCid3 0 "VFCOnOff_Off" 1 "VFCOnOff_On";
VAL_ 1362 VFCVectorOBCVFCid30 0 "VFCOnOff_Off" 1 "VFCOnOff_On";
VAL_ 1362 VFCVectorOBCVFCid31 0 "VFCOnOff_Off" 1 "VFCOnOff_On";
VAL_ 1362 VFCVectorOBCVFCid32 0 "VFCOnOff_Off" 1 "VFCOnOff_On";
VAL_ 1362 VFCVectorOBCVFCid33 0 "VFCOnOff_Off" 1 "VFCOnOff_On";
VAL_ 1362 VFCVectorOBCVFCid34 0 "VFCOnOff_Off" 1 "VFCOnOff_On";
VAL_ 1362 VFCVectorOBCVFCid35 0 "VFCOnOff_Off" 1 "VFCOnOff_On";
VAL_ 1362 VFCVectorOBCVFCid36 0 "VFCOnOff_Off" 1 "VFCOnOff_On";
VAL_ 1362 VFCVectorOBCVFCid37 0 "VFCOnOff_Off" 1 "VFCOnOff_On";
VAL_ 1362 VFCVectorOBCVFCid38 0 "VFCOnOff_Off" 1 "VFCOnOff_On";
VAL_ 1362 VFCVectorOBCVFCid39 0 "VFCOnOff_Off" 1 "VFCOnOff_On";
VAL_ 1362 VFCVectorOBCVFCid4 0 "VFCOnOff_Off" 1 "VFCOnOff_On";
VAL_ 1362 VFCVectorOBCVFCid40 0 "VFCOnOff_Off" 1 "VFCOnOff_On";
VAL_ 1362 VFCVectorOBCVFCid41 0 "VFCOnOff_Off" 1 "VFCOnOff_On";
VAL_ 1362 VFCVectorOBCVFCid42 0 "VFCOnOff_Off" 1 "VFCOnOff_On";
VAL_ 1362 VFCVectorOBCVFCid43 0 "VFCOnOff_Off" 1 "VFCOnOff_On";
VAL_ 1362 VFCVectorOBCVFCid44 0 "VFCOnOff_Off" 1 "VFCOnOff_On";
VAL_ 1362 VFCVectorOBCVFCid45 0 "VFCOnOff_Off" 1 "VFCOnOff_On";
VAL_ 1362 VFCVectorOBCVFCid46 0 "VFCOnOff_Off" 1 "VFCOnOff_On";
VAL_ 1362 VFCVectorOBCVFCid47 0 "VFCOnOff_Off" 1 "VFCOnOff_On";
VAL_ 1362 VFCVectorOBCVFCid48 0 "VFCOnOff_Off" 1 "VFCOnOff_On";
VAL_ 1362 VFCVectorOBCVFCid49 0 "VFCOnOff_Off" 1 "VFCOnOff_On";
VAL_ 1362 VFCVectorOBCVFCid5 0 "VFCOnOff_Off" 1 "VFCOnOff_On";
VAL_ 1362 VFCVectorOBCVFCid50 0 "VFCOnOff_Off" 1 "VFCOnOff_On";
VAL_ 1362 VFCVectorOBCVFCid51 0 "VFCOnOff_Off" 1 "VFCOnOff_On";
VAL_ 1362 VFCVectorOBCVFCid52 0 "VFCOnOff_Off" 1 "VFCOnOff_On";
VAL_ 1362 VFCVectorOBCVFCid53 0 "VFCOnOff_Off" 1 "VFCOnOff_On";
VAL_ 1362 VFCVectorOBCVFCid54 0 "VFCOnOff_Off" 1 "VFCOnOff_On";
VAL_ 1362 VFCVectorOBCVFCid55 0 "VFCOnOff_Off" 1 "VFCOnOff_On";
VAL_ 1362 VFCVectorOBCVFCid56 0 "VFCOnOff_Off" 1 "VFCOnOff_On";
VAL_ 1362 VFCVectorOBCVFCid57 0 "VFCOnOff_Off" 1 "VFCOnOff_On";
VAL_ 1362 VFCVectorOBCVFCid58 0 "VFCOnOff_Off" 1 "VFCOnOff_On";
VAL_ 1362 VFCVectorOBCVFCid59 0 "VFCOnOff_Off" 1 "VFCOnOff_On";
VAL_ 1362 VFCVectorOBCVFCid6 0 "VFCOnOff_Off" 1 "VFCOnOff_On";
VAL_ 1362 VFCVectorOBCVFCid60 0 "VFCOnOff_Off" 1 "VFCOnOff_On";
VAL_ 1362 VFCVectorOBCVFCid61 0 "VFCOnOff_Off" 1 "VFCOnOff_On";
VAL_ 1362 VFCVectorOBCVFCid7 0 "VFCOnOff_Off" 1 "VFCOnOff_On";
VAL_ 1362 VFCVectorOBCVFCid8 0 "VFCOnOff_Off" 1 "VFCOnOff_On";
VAL_ 1362 VFCVectorOBCVFCid9 0 "VFCOnOff_Off" 1 "VFCOnOff_On";
VAL_ 53 CrashStsSafeSts 0 "CrashSts2_NoCrash" 1 "CrashSts2_Crash";
VAL_ 343 TrsmActrSnsrPosnTrsmActrSnsrPosn 0 "TrsmActrSnsrPosn1_Undefd" 1 "TrsmActrSnsrPosn1_Drv" 2 "TrsmActrSnsrPosn1_NeutDrv" 3 "TrsmActrSnsrPosn1_Neut" 4 "TrsmActrSnsrPosn1_RvsNeut" 5 "TrsmActrSnsrPosn1_Rvs" 6 "TrsmActrSnsrPosn1_ParkRvs" 7 "TrsmActrSnsrPosn1_Park";
VAL_ 343 TrsmActrUnitSts 0 "TrsmActrUnitSts1_NoFlt" 1 "TrsmActrUnitSts1_ActrMovmtNoPsbl" 2 "TrsmActrUnitSts1_SrvRqrd" 3 "TrsmActrUnitSts1_ActrFlt";
VAL_ 273 TrsmGearAct 0 "PtGearAct1_Neut" 1 "PtGearAct1_Gear1" 2 "PtGearAct1_Gear2" 3 "PtGearAct1_Gear3" 4 "PtGearAct1_Gear4" 5 "PtGearAct1_Gear5" 6 "PtGearAct1_Gear6" 7 "PtGearAct1_Gear7" 8 "PtGearAct1_Gear8" 9 "PtGearAct1_Gear9" 10 "PtGearAct1_Gear10" 11 "PtGearAct1_Gear11" 12 "PtGearAct1_Gear12" 13 "PtGearAct1_Drv" 14 "PtGearAct1_Ukwn" 15 "PtGearAct1_Rvs";
VAL_ 273 TrsmNInpOk 0 "NoYes1_No" 1 "NoYes1_Yes";
VAL_ 273 TrsmNOutpOk 0 "NoYes1_No" 1 "NoYes1_Yes";
VAL_ 385 EngRunngReqByTrsm 0 "EngRunngReq_Dft" 1 "EngRunngReq_StopInhb" 2 "EngRunngReq_RunReq" 3 "EngRunngReq_Resd";
VAL_ 385 TrsmGearTar 0 "PtGearAct1_Neut" 1 "PtGearAct1_Gear1" 2 "PtGearAct1_Gear2" 3 "PtGearAct1_Gear3" 4 "PtGearAct1_Gear4" 5 "PtGearAct1_Gear5" 6 "PtGearAct1_Gear6" 7 "PtGearAct1_Gear7" 8 "PtGearAct1_Gear8" 9 "PtGearAct1_Gear9" 10 "PtGearAct1_Gear10" 11 "PtGearAct1_Gear11" 12 "PtGearAct1_Gear12" 13 "PtGearAct1_Drv" 14 "PtGearAct1_Ukwn" 15 "PtGearAct1_Rvs";
VAL_ 385 TrsmLockUpStAct 0 "PtLockUpType_OpenLockUp" 1 "PtLockUpType_SlipLockUp" 2 "PtLockUpType_MicroSlipLockUp" 3 "PtLockUpType_LockUpLockd";
VAL_ 385 TrsmNeutFailr 0 "TrsmNeutFailr1_NeutPsbl" 1 "TrsmNeutFailr1_NeutNotPsbl";
VAL_ 385 TrsmShiftInhb 0 "TrsmShiftInhb1_TrsmShiftInhbNotActv" 1 "TrsmShiftInhb1_TrsmShiftInhbActv";
VAL_ 389 TrsmActrPosnSafeTrsmActrPosn 0 "TrsmActrPosn1_Park" 1 "TrsmActrPosn1_ParkRvs" 2 "TrsmActrPosn1_Rvs" 3 "TrsmActrPosn1_RvsNeut" 4 "TrsmActrPosn1_Neut" 5 "TrsmActrPosn1_NeutDrv" 6 "TrsmActrPosn1_Drv" 7 "TrsmActrPosn1_Undefd";
VAL_ 339 TrsmToPrpsnNReqRecAuxTrsmNReqCtrl 0 "OnOff1_Off" 1 "OnOff1_On";
VAL_ 98 ChrgHndlStrtEna 0 "ChrgHndlStrtEna_PwrUpNotEna" 1 "ChrgHndlStrtEna_PwrUpEna";
VAL_ 98 IncSpdIdleElecReq 0 "ReqSts1_NotReqd" 1 "ReqSts1_Reqd";
VAL_ 98 RoadSgnInfoSts 0 "TrfcSgnInfoSts_TSIUnknown" 1 "TrfcSgnInfoSts_TSIOff" 2 "TrfcSgnInfoSts_TSIOn_fusion" 3 "TrfcSgnInfoSts_TSIOn_visiononlymode" 4 "TrfcSgnInfoSts_TSIOn_navigationonlymode" 5 "TrfcSgnInfoSts_TSIUnavailable" 6 "TrfcSgnInfoSts_TSIServicerequired" 7 "TrfcSgnInfoSts_Reserved";
VAL_ 134 WhlSpdCircumlFrntLeQf 0 "GenQf1_UndefindDataAccur" 1 "GenQf1_TmpUndefdData" 2 "GenQf1_DataAccurNotWithinSpcn" 3 "GenQf1_AccurData";
VAL_ 134 WhlSpdCircumlFrntRiQf 0 "GenQf1_UndefindDataAccur" 1 "GenQf1_TmpUndefdData" 2 "GenQf1_DataAccurNotWithinSpcn" 3 "GenQf1_AccurData";
VAL_ 118 BrkPedlPsdBrkPedlNotPsdSafe 0 "NoYes1_No" 1 "NoYes1_Yes";
VAL_ 118 BrkPedlPsdBrkPedlPsd 0 "NoYes1_No" 1 "NoYes1_Yes";
VAL_ 118 BrkPedlPsdQf 0 "GenQf1_UndefindDataAccur" 1 "GenQf1_TmpUndefdData" 2 "GenQf1_DataAccurNotWithinSpcn" 3 "GenQf1_AccurData";
VAL_ 118 VehMtnStVehMtnSt 0 "VehMtnSt2_Ukwn" 1 "VehMtnSt2_StandStillVal1" 2 "VehMtnSt2_StandStillVal2" 3 "VehMtnSt2_StandStillVal3" 4 "VehMtnSt2_RollgFwdVal1" 5 "VehMtnSt2_RollgFwdVal2" 6 "VehMtnSt2_RollgBackwVal1" 7 "VehMtnSt2_RollgBackwVal2";
VAL_ 118 VehSpdLgtQf 0 "GenQf1_UndefindDataAccur" 1 "GenQf1_TmpUndefdData" 2 "GenQf1_DataAccurNotWithinSpcn" 3 "GenQf1_AccurData";
VAL_ 113 WhlSpdCircumlReLeQf 0 "GenQf1_UndefindDataAccur" 1 "GenQf1_TmpUndefdData" 2 "GenQf1_DataAccurNotWithinSpcn" 3 "GenQf1_AccurData";
VAL_ 113 WhlSpdCircumlReRiQf 0 "GenQf1_UndefindDataAccur" 1 "GenQf1_TmpUndefdData" 2 "GenQf1_DataAccurNotWithinSpcn" 3 "GenQf1_AccurData";
VAL_ 129 ADataRawSafeALat1Qf 0 "Qf1_DevOfDataUndefd" 1 "Qf1_DataTmpUndefdAndEvlnInProgs" 2 "Qf1_DevOfDataNotWithinRngAllwd" 3 "Qf1_DataCalcdWithDevDefd";
VAL_ 129 ADataRawSafeALgt1Qf 0 "Qf1_DevOfDataUndefd" 1 "Qf1_DataTmpUndefdAndEvlnInProgs" 2 "Qf1_DevOfDataNotWithinRngAllwd" 3 "Qf1_DataCalcdWithDevDefd";
VAL_ 129 ADataRawSafeAVertQf 0 "Qf1_DevOfDataUndefd" 1 "Qf1_DataTmpUndefdAndEvlnInProgs" 2 "Qf1_DevOfDataNotWithinRngAllwd" 3 "Qf1_DataCalcdWithDevDefd";
VAL_ 357 EngTracCtrlActvFrntMax 0 "CtrlSts1_NoCtrl" 1 "CtrlSts1_InCtrl";
VAL_ 369 LockgCenStsLockSt 0 "LockSt3_LockUndefd" 1 "LockSt3_LockUnlckd" 2 "LockSt3_LockTrUnlckd" 3 "LockSt3_LockLockd";
VAL_ 369 LockgCenStsTrigSrc 0 "LockTrigSrc2_NoTrigSrc" 1 "LockTrigSrc2_KeyRem" 2 "LockTrigSrc2_Keyls" 3 "LockTrigSrc2_IntrSwt" 4 "LockTrigSrc2_SpdAut" 5 "LockTrigSrc2_TmrAut" 6 "LockTrigSrc2_Slam" 7 "LockTrigSrc2_Telm" 8 "LockTrigSrc2_Crash";
VAL_ 369 LockgCenStsUpdEve 0 "Boolean_FALSE" 1 "Boolean_TRUE";
VAL_ 369 YawStabyCtrlActv 0 "CtrlSts1_NoCtrl" 1 "CtrlSts1_InCtrl";
VAL_ 353 AgDataRawSafeRollRateQf 0 "Qf1_DevOfDataUndefd" 1 "Qf1_DataTmpUndefdAndEvlnInProgs" 2 "Qf1_DevOfDataNotWithinRngAllwd" 3 "Qf1_DataCalcdWithDevDefd";
VAL_ 353 AgDataRawSafeYawRateQf 0 "Qf1_DevOfDataUndefd" 1 "Qf1_DataTmpUndefdAndEvlnInProgs" 2 "Qf1_DevOfDataNotWithinRngAllwd" 3 "Qf1_DataCalcdWithDevDefd";
VAL_ 561 CluPedl 0 "OnOff1_Off" 1 "OnOff1_On";
VAL_ 561 LimForDecelNotExcd 0 "NoYes1_No" 1 "NoYes1_Yes";
VAL_ 561 SpprtBattOkForCrkCold 0 "AvlSts2_NotAvl" 1 "AvlSts2_Avl";
VAL_ 561 TelmPreClimaPrio 0 "PreClimaPrio_Range" 1 "PreClimaPrio_KeepSOC" 2 "PreClimaPrio_Comfort" 3 "PreClimaPrio_Reserved";
VAL_ 561 TrlrPrsnt 0 "TrlrPrsntSts_TrlrNotPrsnt" 1 "TrlrPrsntSts_TrlrPrsnt";
VAL_ 609 ImobEngMgrReq3ImobEngMgrCmdTar1 0 "ImobEngMgrReqCmd_ImobEngCmdTarIdle" 1 "ImobEngMgrReqCmd_ImobEngMtnStrtReqCmd" 2 "ImobEngMgrReqCmd_ImobEngNoMtnStrtReqCmd" 3 "ImobEngMgrReqCmd_ImobEngTurnOffCmd";
VAL_ 609 MaintainBattTCtrl 0 "OnOff1_Off" 1 "OnOff1_On";
VAL_ 597 ImobEngMgrReq2ImobEngMgrCmdTar1 0 "ImobEngMgrReqCmd_ImobEngCmdTarIdle" 1 "ImobEngMgrReqCmd_ImobEngMtnStrtReqCmd" 2 "ImobEngMgrReqCmd_ImobEngNoMtnStrtReqCmd" 3 "ImobEngMgrReqCmd_ImobEngTurnOffCmd";
VAL_ 641 ChrgModReq 0 "ChrgMod_Conventional" 1 "ChrgMod_Discharge" 2 "ChrgMod_Maintain" 3 "ChrgMod_Spare1" 4 "ChrgMod_Spare2" 5 "ChrgMod_Spare3";
VAL_ 641 CmptmtAirTEstimdExtdQlyFlg 0 "GenQf1_UndefindDataAccur" 1 "GenQf1_TmpUndefdData" 2 "GenQf1_DataAccurNotWithinSpcn" 3 "GenQf1_AccurData";
VAL_ 86 TwliBriSts 0 "TwliBriSts1_Night" 1 "TwliBriSts1_Day";
VAL_ 86 VehModMngtGlbSafe1CarModSts1 0 "CarModSts1_CarModNorm" 1 "CarModSts1_CarModTrnsp" 2 "CarModSts1_CarModFcy" 3 "CarModSts1_CarModCrash" 5 "CarModSts1_CarModDyno";
VAL_ 86 VehModMngtGlbSafe1FltEgyCnsWdSts 0 "FltEgyCns1_NoFlt" 1 "FltEgyCns1_Flt";
VAL_ 86 VehModMngtGlbSafe1UsgModSts 0 "UsgModSts1_UsgModAbdnd" 1 "UsgModSts1_UsgModInActv" 2 "UsgModSts1_UsgModCnvinc" 11 "UsgModSts1_UsgModActv" 13 "UsgModSts1_UsgModDrvg";
VAL_ 645 AbsClrRdyReq 0 "OnOff1_Off" 1 "OnOff1_On";
VAL_ 645 AmbTRawQly 0 "GenQf1_UndefindDataAccur" 1 "GenQf1_TmpUndefdData" 2 "GenQf1_DataAccurNotWithinSpcn" 3 "GenQf1_AccurData";
VAL_ 645 VehBattUSysUQf 0 "GenQf1_UndefindDataAccur" 1 "GenQf1_TmpUndefdData" 2 "GenQf1_DataAccurNotWithinSpcn" 3 "GenQf1_AccurData";
VAL_ 344 DrvrBrkTqAtWhlsReqdQf 0 "GenQf1_UndefindDataAccur" 1 "GenQf1_TmpUndefdData" 2 "GenQf1_DataAccurNotWithinSpcn" 3 "GenQf1_AccurData";
VAL_ 344 EpbStsEpbSts 0 "EpbSts_Resd0" 1 "EpbSts_Resd1" 2 "EpbSts_Resd2" 3 "EpbSts_AllAppld" 4 "EpbSts_Resd4" 5 "EpbSts_AllInTran" 6 "EpbSts_BrkgDynByActr" 7 "EpbSts_Resd7" 8 "EpbSts_Resd8" 9 "EpbSts_ActrAllReld" 10 "EpbSts_BrkgDynDegraded" 11 "EpbSts_Resd11" 12 "EpbSts_BrkgDyn" 13 "EpbSts_Resd13" 14 "EpbSts_Resd14" 15 "EpbSts_Err";
VAL_ 667 ChrgLidFrntSts 0 "DoorSts2_Ukwn" 1 "DoorSts2_Opend" 2 "DoorSts2_Clsd";
VAL_ 667 DrvModReq 0 "DrvModReqType1_Undefd" 1 "DrvModReqType1_ECO" 2 "DrvModReqType1_Comfort_Normal" 3 "DrvModReqType1_Dynamic_Sport" 4 "DrvModReqType1_Individual" 5 "DrvModReqType1_Offroad_CrossTerrain" 6 "DrvModReqType1_AWD" 7 "DrvModReqType1_Save" 8 "DrvModReqType1_Pure_EV" 9 "DrvModReqType1_Hybird" 10 "DrvModReqType1_Power" 11 "DrvModReqType1_Snow" 12 "DrvModReqType1_SportAdd" 13 "DrvModReqType1_Reserved1" 14 "DrvModReqType1_Reserved2" 15 "DrvModReqType1_Err";
VAL_ 667 SoundExtActvSts 0 "OnOff1_Off" 1 "OnOff1_On";
VAL_ 49 AccrOvrdnAllwdForAutDrvYesNo1 0 "YesNo1_Yes" 1 "YesNo1_No";
VAL_ 49 ChrgLidRearSts 0 "DoorSts2_Ukwn" 1 "DoorSts2_Opend" 2 "DoorSts2_Clsd";
VAL_ 49 SteerWhlSnsrQf 0 "GenQf1_UndefindDataAccur" 1 "GenQf1_TmpUndefdData" 2 "GenQf1_DataAccurNotWithinSpcn" 3 "GenQf1_AccurData";
VAL_ 1051 BattThermMngtInFutureThermModAtTime 0 "Idle" 1 "ThermalBalancing" 2 "PassiveHeating" 3 "ActiveHeating" 4 "PassiveCooling" 5 "ActiveCooling" 6 "CombinedCooling" 7 "Reserved";
VAL_ 1042 ClimateCtrlInFutureThermModAtTime 0 "Idle" 1 "ThermalBalancing" 2 "PassiveHeating" 3 "ActiveHeating" 4 "PassiveCooling" 5 "ActiveCooling" 6 "CombinedCooling" 7 "Reserved";
VAL_ 1375 VFCInfoEna 0 "EnableDisableCoding_Disabled" 1 "EnableDisableCoding_Enabled";
SIG_GROUP_ 49 AccrOvrdnAllwdForAutDrv 1 : AccrOvrdnAllwdForAutDrvChks AccrOvrdnAllwdForAutDrvCntr AccrOvrdnAllwdForAutDrvYesNo1;
SIG_GROUP_ 129 ADataRawSafe 1 : ADataRawSafeALat ADataRawSafeALat1Qf ADataRawSafeALgt ADataRawSafeALgt1Qf ADataRawSafeAVert ADataRawSafeAVertQf ADataRawSafeChks ADataRawSafeCntr;
SIG_GROUP_ 353 AgDataRawSafe 1 : AgDataRawSafeChks AgDataRawSafeCntr AgDataRawSafeRollRate AgDataRawSafeRollRateQf AgDataRawSafeYawRate AgDataRawSafeYawRateQf;
SIG_GROUP_ 645 AmbTRaw 1 : AmbTRawAmbTVal AmbTRawQly;
SIG_GROUP_ 324 BattSftySig 1 : BattSftySigChks BattSftySigCntr BattSftySigSysSaftyBattI BattSftySigSysSaftyBattU;
SIG_GROUP_ 1051 BattThermMngtInFuture 1 : BattThermMngtInFuturePwrAtTime BattThermMngtInFutureSequenceNo BattThermMngtInFutureTempAtTime BattThermMngtInFutureThermModAtTime BattThermMngtInFutureTime BattThermMngtInFutureVersionNo;
SIG_GROUP_ 357 BrkFricTqAtWhlAct 1 : BrkFricTqAtWhlActBrkFricTqAtWhlFrntLeAct BrkFricTqAtWhlActBrkFricTqAtWhlFrntRiAct BrkFricTqAtWhlActBrkFricTqAtWhlReLeAct BrkFricTqAtWhlActBrkFricTqAtWhlReRiAct;
SIG_GROUP_ 369 BrkFricTqTotAtWhlsAct 1 : BrkFricTqTotAtWhlsActBrkFricTqTotAtWhlsAct BrkFricTqTotAtWhlsActChks BrkFricTqTotAtWhlsActCntr;
SIG_GROUP_ 118 BrkPedlPsd 1 : BrkPedlPsdBrkPedlNotPsdSafe BrkPedlPsdBrkPedlPsd BrkPedlPsdChks BrkPedlPsdCntr BrkPedlPsdQf;
SIG_GROUP_ 1042 ClimateCtrlInFuture 1 : ClimateCtrlInFuturePwrAtTime ClimateCtrlInFutureSequenceNo ClimateCtrlInFutureTempAtTime ClimateCtrlInFutureThermModAtTime ClimateCtrlInFutureTime ClimateCtrlInFutureVersionNo;
SIG_GROUP_ 641 CmptmtAirTEstimdExtd 1 : CmptmtAirTEstimdExtdComptmtT CmptmtAirTEstimdExtdQlyFlg;
SIG_GROUP_ 53 CrashStsSafe 1 : CrashStsSafeChks CrashStsSafeCntr CrashStsSafeSts;
SIG_GROUP_ 344 DrvrBrkTqAtWhlsReqd 1 : DrvrBrkTqAtWhlsReqdChks DrvrBrkTqAtWhlsReqdCntr DrvrBrkTqAtWhlsReqdDrvrBrkTqAtWhlsReqd DrvrBrkTqAtWhlsReqdQf;
SIG_GROUP_ 344 EpbSts 1 : EpbStsChks EpbStsCntr EpbStsEpbSts;
SIG_GROUP_ 597 ImobEngMgrReq2 1 : ImobEngMgrReq2ImobEngDataMgrReq0 ImobEngMgrReq2ImobEngDataMgrReq1 ImobEngMgrReq2ImobEngDataMgrReq2 ImobEngMgrReq2ImobEngDataMgrReq3 ImobEngMgrReq2ImobEngDataMgrReq4 ImobEngMgrReq2ImobEngDataMgrReq5 ImobEngMgrReq2ImobEngDataMgrReq6 ImobEngMgrReq2ImobEngMgrCmdTar1;
SIG_GROUP_ 609 ImobEngMgrReq3 1 : ImobEngMgrReq3ImobEngDataMgrReq0 ImobEngMgrReq3ImobEngDataMgrReq1 ImobEngMgrReq3ImobEngDataMgrReq2 ImobEngMgrReq3ImobEngDataMgrReq3 ImobEngMgrReq3ImobEngDataMgrReq4 ImobEngMgrReq3ImobEngDataMgrReq5 ImobEngMgrReq3ImobEngDataMgrReq6 ImobEngMgrReq3ImobEngMgrCmdTar1;
SIG_GROUP_ 561 LimForDecel 1 : LimForDecelChks LimForDecelCntr LimForDecelNotExcd;
SIG_GROUP_ 369 LockgCenSts 1 : LockgCenStsLockSt LockgCenStsTrigSrc LockgCenStsUpdEve;
SIG_GROUP_ 1458 MVCMdevelpsignalgroupresp 1 : MVCMdevelpsignalgrouprespFunctiondevpsignalgroup1 MVCMdevelpsignalgrouprespFunctiondevpsignalgroup2 MVCMdevelpsignalgrouprespFunctiondevpsignalgroup3 MVCMdevelpsignalgrouprespFunctiondevpsignalgroup4 MVCMdevelpsignalgrouprespFunctiondevpsignalgroup5 MVCMdevelpsignalgrouprespFunctiondevpsignalgroup6 MVCMdevelpsignalgrouprespFunctiondevpsignalgroup7 MVCMdevelpsignalgrouprespFunctiondevpsignalgroup8;
SIG_GROUP_ 395 MvFltDcDc 1 : MvFltDcDcBoostModeFlt MvFltDcDcBuckModeFlt MvFltDcDcCANLoss MvFltDcDcHwFlt MvFltDcDcLVSideOpenLoad MvFltDcDcLVSideOverCurrent MvFltDcDcLVSideOverVoltage MvFltDcDcLVSideUnderVoltage MvFltDcDcMVSideOverCurrent MvFltDcDcMVSideOverVoltage MvFltDcDcMVSideUnderVoltage MvFltDcDcPCBOverTemp MvFltDcDcPreChargeFlt MvFltDcDcPwrGndLoss MvFltDcDcSensorFlt MvFltDcDcSupplyVoltageCmpFlt;
SIG_GROUP_ 395 MvFltDcDcSec 1 : MvFltDcDcSecBuckModeFault MvFltDcDcSecHwFlt MvFltDcDcSecLVSideOpenLoad MvFltDcDcSecLVSideOverCurrent MvFltDcDcSecLVSideOverVoltage MvFltDcDcSecLVSideUnderVoltage MvFltDcDcSecMVSideOverCurrent MvFltDcDcSecPCBOverTemperature MvFltDcDcSecPowerGNDLoss MvFltDcDcSecSensorFault MvFltDcDcSecSupplyVoltageCmpFlt;
SIG_GROUP_ 108 MvIDcDcActLoSide 1 : MvIDcDcActLoSideChks MvIDcDcActLoSideCntr MvIDcDcActLoSideMvIDcDcActLoSide;
SIG_GROUP_ 530 MvIDcDcActLoSideSec 1 : MvIDcDcActLoSideSecChks MvIDcDcActLoSideSecCntr MvIDcDcActLoSideSecMvIDcDcActLoSide;
SIG_GROUP_ 395 MvLimnIndcnDcDc 1 : MvLimnIndcnDcDcChks MvLimnIndcnDcDcCntr MvLimnIndcnDcDcMvLimnIndcnDcDc;
SIG_GROUP_ 108 MvUDcDcActLoSide 1 : MvUDcDcActLoSideChks MvUDcDcActLoSideCntr MvUDcDcActLoSideMvUDcDcActLoSide;
SIG_GROUP_ 530 MvUDcDcActLoSideSec 1 : MvUDcDcActLoSideSecChks MvUDcDcActLoSideSecCntr MvUDcDcActLoSideSecMvUDcDcActLoSide;
SIG_GROUP_ 1429 OBCdevelpsignalgroupresp 1 : OBCdevelpsignalgrouprespFunctiondevpsignalgroup1 OBCdevelpsignalgrouprespFunctiondevpsignalgroup2 OBCdevelpsignalgrouprespFunctiondevpsignalgroup3 OBCdevelpsignalgrouprespFunctiondevpsignalgroup4 OBCdevelpsignalgrouprespFunctiondevpsignalgroup5 OBCdevelpsignalgrouprespFunctiondevpsignalgroup6 OBCdevelpsignalgrouprespFunctiondevpsignalgroup7 OBCdevelpsignalgrouprespFunctiondevpsignalgroup8;
SIG_GROUP_ 98 PtTqAtAxleFrntMinReq 1 : PtTqAtAxleFrntMinReqChks PtTqAtAxleFrntMinReqCntr PtTqAtAxleFrntMinReqPtTqAtAxleFrntMinReq;
SIG_GROUP_ 65 PtTqAtAxleReMinReq 1 : PtTqAtAxleReMinReqChks PtTqAtAxleReMinReqCntr PtTqAtAxleReMinReqPtTqAtAxleReMinReq;
SIG_GROUP_ 1456 SRSdevelpsignalgroupTX 1 : SRSdevelpsignalgroupTXFunctiondevpsignalgroup1 SRSdevelpsignalgroupTXFunctiondevpsignalgroup2 SRSdevelpsignalgroupTXFunctiondevpsignalgroup3 SRSdevelpsignalgroupTXFunctiondevpsignalgroup4 SRSdevelpsignalgroupTXFunctiondevpsignalgroup5 SRSdevelpsignalgroupTXFunctiondevpsignalgroup6 SRSdevelpsignalgroupTXFunctiondevpsignalgroup7 SRSdevelpsignalgroupTXFunctiondevpsignalgroup8;
SIG_GROUP_ 49 SteerWhlSnsr 1 : SteerWhlSnsrChks SteerWhlSnsrCntr SteerWhlSnsrQf SteerWhlSnsrSteerWhlAg SteerWhlSnsrSteerWhlAgSpd;
SIG_GROUP_ 389 TrsmActrPosnSafe 1 : TrsmActrPosnSafeTrsmActrPosn TrsmActrPosnSafeTrsmActrPosnChks TrsmActrPosnSafeTrsmActrPosnCntr;
SIG_GROUP_ 343 TrsmActrSnsrPosn 1 : TrsmActrSnsrPosnChks TrsmActrSnsrPosnCntr TrsmActrSnsrPosnTrsmActrSnsrPosn;
SIG_GROUP_ 273 TrsmN 1 : TrsmNChks TrsmNCntr TrsmNInp TrsmNInpOk TrsmNOutp TrsmNOutpOk;
SIG_GROUP_ 339 TrsmToPrpsnNReqRecAux 1 : TrsmToPrpsnNReqRecAuxTrsmNReqCtrl TrsmToPrpsnNReqRecAuxTrsmNReqMax TrsmToPrpsnNReqRecAuxTrsmNReqMin;
SIG_GROUP_ 1518 VDDMPropCANInternalDevRespMesg 1 : VDDMPropCANInternalDevRespMesgFunctiondevpsignalgroup1 VDDMPropCANInternalDevRespMesgFunctiondevpsignalgroup2 VDDMPropCANInternalDevRespMesgFunctiondevpsignalgroup3 VDDMPropCANInternalDevRespMesgFunctiondevpsignalgroup4 VDDMPropCANInternalDevRespMesgFunctiondevpsignalgroup5 VDDMPropCANInternalDevRespMesgFunctiondevpsignalgroup6 VDDMPropCANInternalDevRespMesgFunctiondevpsignalgroup7 VDDMPropCANInternalDevRespMesgFunctiondevpsignalgroup8;
SIG_GROUP_ 645 VehBattU 1 : VehBattUSysU VehBattUSysUQf;
SIG_GROUP_ 565 VehCfgPrm 1 : VehCfgPrmBlkIDBytePosn1 VehCfgPrmCCPBytePosn2 VehCfgPrmCCPBytePosn3 VehCfgPrmCCPBytePosn4 VehCfgPrmCCPBytePosn5 VehCfgPrmCCPBytePosn6 VehCfgPrmCCPBytePosn7 VehCfgPrmCCPBytePosn8;
SIG_GROUP_ 566 VehCfgPrmExt 1 : VehCfgPrmExtBlkIDBytePosn1 VehCfgPrmExtCCPBytePosn2 VehCfgPrmExtCCPBytePosn3 VehCfgPrmExtCCPBytePosn4 VehCfgPrmExtCCPBytePosn5 VehCfgPrmExtCCPBytePosn6 VehCfgPrmExtCCPBytePosn7 VehCfgPrmExtCCPBytePosn8;
SIG_GROUP_ 86 VehModMngtGlbSafe1 1 : VehModMngtGlbSafe1CarModSts1 VehModMngtGlbSafe1CarModSubtypWdCarModSubtyp VehModMngtGlbSafe1Chks VehModMngtGlbSafe1Cntr VehModMngtGlbSafe1EgyLvlElecMai VehModMngtGlbSafe1EgyLvlElecSubtyp VehModMngtGlbSafe1FltEgyCnsWdSts VehModMngtGlbSafe1PwrLvlElecMai VehModMngtGlbSafe1PwrLvlElecSubtyp VehModMngtGlbSafe1UsgModSts;
SIG_GROUP_ 118 VehMtnSt 1 : VehMtnStChks VehMtnStCntr VehMtnStVehMtnSt;
SIG_GROUP_ 118 VehSpdLgt 1 : VehSpdLgtChks VehSpdLgtCntr VehSpdLgtQf VehSpdLgtVehSpdLgt;
SIG_GROUP_ 1362 VFCVectorOBC 1 : VFCVectorOBCBlockID VFCVectorOBCVFCid0 VFCVectorOBCVFCid1 VFCVectorOBCVFCid10 VFCVectorOBCVFCid11 VFCVectorOBCVFCid12 VFCVectorOBCVFCid13 VFCVectorOBCVFCid14 VFCVectorOBCVFCid15 VFCVectorOBCVFCid16 VFCVectorOBCVFCid17 VFCVectorOBCVFCid18 VFCVectorOBCVFCid19 VFCVectorOBCVFCid2 VFCVectorOBCVFCid20 VFCVectorOBCVFCid21 VFCVectorOBCVFCid22 VFCVectorOBCVFCid23 VFCVectorOBCVFCid24 VFCVectorOBCVFCid25 VFCVectorOBCVFCid26 VFCVectorOBCVFCid27 VFCVectorOBCVFCid28 VFCVectorOBCVFCid29 VFCVectorOBCVFCid3 VFCVectorOBCVFCid30 VFCVectorOBCVFCid31 VFCVectorOBCVFCid32 VFCVectorOBCVFCid33 VFCVectorOBCVFCid34 VFCVectorOBCVFCid35 VFCVectorOBCVFCid36 VFCVectorOBCVFCid37 VFCVectorOBCVFCid38 VFCVectorOBCVFCid39 VFCVectorOBCVFCid4 VFCVectorOBCVFCid40 VFCVectorOBCVFCid41 VFCVectorOBCVFCid42 VFCVectorOBCVFCid43 VFCVectorOBCVFCid44 VFCVectorOBCVFCid45 VFCVectorOBCVFCid46 VFCVectorOBCVFCid47 VFCVectorOBCVFCid48 VFCVectorOBCVFCid49 VFCVectorOBCVFCid5 VFCVectorOBCVFCid50 VFCVectorOBCVFCid51 VFCVectorOBCVFCid52 VFCVectorOBCVFCid53 VFCVectorOBCVFCid54 VFCVectorOBCVFCid55 VFCVectorOBCVFCid56 VFCVectorOBCVFCid57 VFCVectorOBCVFCid58 VFCVectorOBCVFCid59 VFCVectorOBCVFCid6 VFCVectorOBCVFCid60 VFCVectorOBCVFCid61 VFCVectorOBCVFCid7 VFCVectorOBCVFCid8 VFCVectorOBCVFCid9;
SIG_GROUP_ 134 WhlSpdCircumlFrnt 1 : WhlSpdCircumlFrntChks WhlSpdCircumlFrntCntr WhlSpdCircumlFrntLe WhlSpdCircumlFrntLeQf WhlSpdCircumlFrntRi WhlSpdCircumlFrntRiQf;
SIG_GROUP_ 113 WhlSpdCircumlRe 1 : WhlSpdCircumlReChks WhlSpdCircumlReCntr WhlSpdCircumlReLe WhlSpdCircumlReLeQf WhlSpdCircumlReRi WhlSpdCircumlReRiQf;
